VERSION ""

NS_ :

BS_:

BU_: MCTM_LS TIM_LS EOCM2cp_K2_LS EOCM2cp_K1_LS ADIMa_LS BCM_LS SAM_SR_LS SAM_SL_LS SAM_PR_LS SAM_PL_LS CGM3a_LS Dummy_LS VICM_LS ECC_LS PEPS_LS AOS_LS SDM_PR_LS AOS2_LS DLM_LS SCCM_2_LS SCCM_1_LS UPA_LS ADIMb_LS

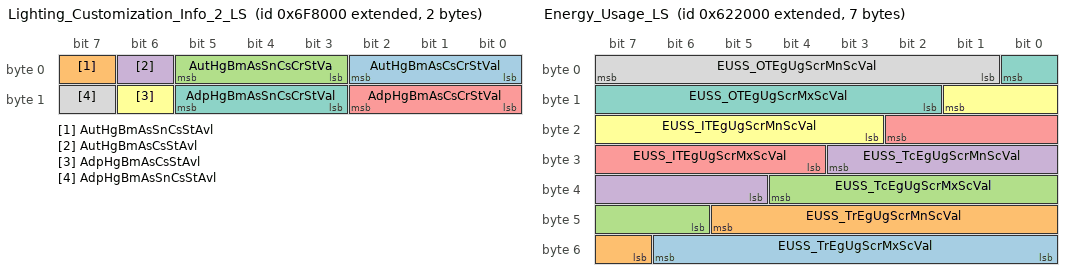
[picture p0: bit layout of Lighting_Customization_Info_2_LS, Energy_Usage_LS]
BO_ 2154790912 Lighting_Customization_Info_2_LS: 2 EOCM2cp_K2_LS
 SG_ AutHgBmAsCsCrStVal : 2|3@0+ (1,0) [0|7] ""  CGM3a_LS
 SG_ AutHgBmAsSnCsStAvl : 7|1@0+ (1,0) [0|1] ""  CGM3a_LS
 SG_ AutHgBmAsSnCsCrStVa : 5|3@0+ (1,0) [0|7] ""  CGM3a_LS
 SG_ AutHgBmAsCsStAvl : 6|1@0+ (1,0) [0|1] ""  CGM3a_LS
 SG_ AdpHgBmAsCsCrStVal : 10|3@0+ (1,0) [0|7] ""  CGM3a_LS
 SG_ AdpHgBmAsCsStAvl : 14|1@0+ (1,0) [0|1] ""  CGM3a_LS
 SG_ AdpHgBmAsSnCsCrStVal : 13|3@0+ (1,0) [0|7] ""  CGM3a_LS
 SG_ AdpHgBmAsSnCsStAvl : 15|1@0+ (1,0) [0|1] ""  CGM3a_LS

BO_ 2159149056 ODI_TEL_2_CenterStack_LS: 8 CGM3a_LS
 SG_ ODI_TEL2CntrStck : 7|64@0+ (1,0) [0|1.84467440737096E+019] ""  MCTM_LS

BO_ 2150227968 Phone_Speech_Rec_Status_LS: 1 CGM3a_LS
 SG_ PhnSpRcgnApSt : 1|2@0+ (1,0) [0|3] ""  MCTM_LS

BO_ 2153914368 Energy_Usage_LS: 7 VICM_LS
 SG_ EUSS_TrEgUgScrMxScVal : 54|7@0- (0.1,0) [-5|5] ""  CGM3a_LS
 SG_ EUSS_TrEgUgScrMnScVal : 45|7@0- (0.1,0) [-5|5] ""  CGM3a_LS
 SG_ EUSS_TcEgUgScrMxScVal : 36|7@0- (0.1,0) [-5|5] ""  CGM3a_LS
 SG_ EUSS_TcEgUgScrMnScVal : 27|7@0- (0.1,0) [-5|5] ""  CGM3a_LS
 SG_ EUSS_ITEgUgScrMxScVal : 18|7@0- (0.1,0) [-5|5] ""  CGM3a_LS
 SG_ EUSS_ITEgUgScrMnScVal : 9|7@0- (0.1,0) [-5|5] ""  CGM3a_LS
 SG_ EUSS_OTEgUgScrMxScVal : 0|7@0- (0.1,0) [-5|5] ""  CGM3a_LS
 SG_ EUSS_OTEgUgScrMnScVal : 7|7@0- (0.1,0) [-5|5] ""  CGM3a_LS

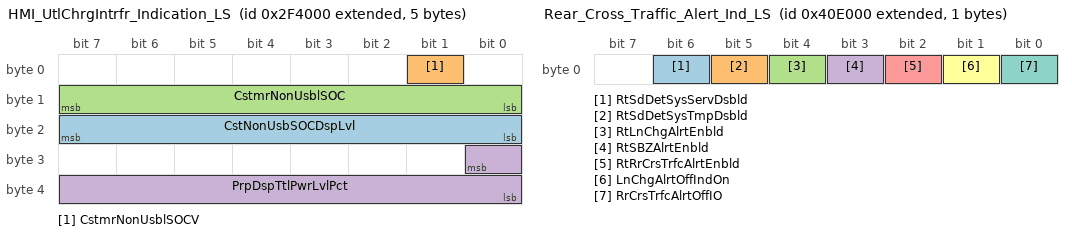
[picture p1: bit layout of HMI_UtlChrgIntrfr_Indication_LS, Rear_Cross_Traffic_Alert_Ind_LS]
BO_ 2150580224 HMI_UtlChrgIntrfr_Indication_LS: 5 VICM_LS
 SG_ CstNonUsbSOCDspLvl : 23|8@0+ (0.392157,0) [0|100.000035] "%"  CGM3a_LS
 SG_ CstmrNonUsblSOCV : 1|1@0+ (1,0) [0|1] ""  CGM3a_LS
 SG_ CstmrNonUsblSOC : 15|8@0+ (0.392157,0) [0|100.000035] "%"  CGM3a_LS
 SG_ PrpDspTtlPwrLvlPct : 24|9@0- (0.392157,0) [-100.392192|100.000035] "%"  CGM3a_LS

BO_ 2020 USDT_Req_to_VICM_LS: 8 CGM3a_LS
 SG_ DgnInf : 7|64@0+ (1,0) [0|1.84467440737096E+019] ""  CGM3a_LS,VICM_LS

BO_ 2151735296 Rear_Cross_Traffic_Alert_Ind_LS: 1 EOCM2cp_K2_LS
 SG_ RtSdDetSysServDsbld : 6|1@0+ (1,0) [0|1] ""  CGM3a_LS
 SG_ RtSdDetSysTmpDsbld : 5|1@0+ (1,0) [0|1] ""  CGM3a_LS
 SG_ RtLnChgAlrtEnbld : 4|1@0+ (1,0) [0|1] ""  CGM3a_LS
 SG_ RtSBZAlrtEnbld : 3|1@0+ (1,0) [0|1] ""  CGM3a_LS
 SG_ RtRrCrsTrfcAlrtEnbld : 2|1@0+ (1,0) [0|1] ""  CGM3a_LS
 SG_ LnChgAlrtOffIndOn : 1|1@0+ (1,0) [0|1] ""  CGM3a_LS
 SG_ RrCrsTrfcAlrtOffIO : 0|1@0+ (1,0) [0|1] ""  CGM3a_LS

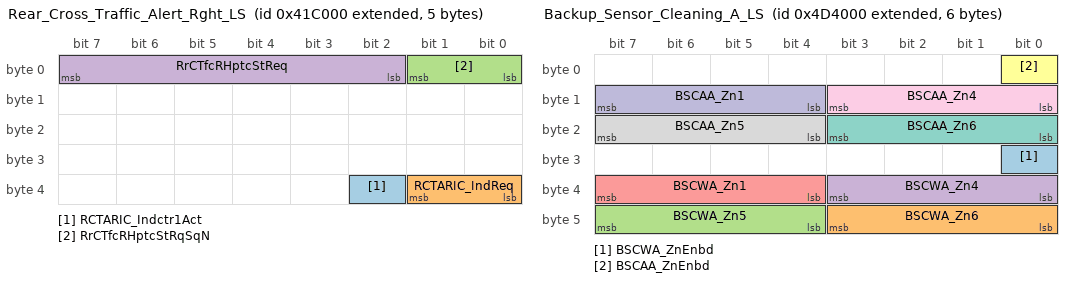
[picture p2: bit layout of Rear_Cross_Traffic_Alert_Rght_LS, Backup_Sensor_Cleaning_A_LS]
BO_ 2151792640 Rear_Cross_Traffic_Alert_Rght_LS: 5 EOCM2cp_K2_LS
 SG_ RCTARIC_Indctr1Act : 34|1@0+ (1,0) [0|1] ""  CGM3a_LS
 SG_ RCTARIC_IndReq : 33|2@0+ (1,0) [0|3] ""  CGM3a_LS
 SG_ RrCTfcRHptcStRqSqN : 1|2@0+ (1,0) [0|3] ""  CGM3a_LS
 SG_ RrCTfcRHptcStReq : 7|6@0+ (1,0) [0|63] ""  CGM3a_LS

BO_ 2152546304 Backup_Sensor_Cleaning_A_LS: 6 ADIMb_LS
 SG_ BSCWA_ZnEnbd : 24|1@0+ (1,0) [0|1] ""  CGM3a_LS,SCCM_1_LS
 SG_ BSCWA_Zn6 : 43|4@0+ (0.25,0) [0|3.75] "s"  CGM3a_LS,SCCM_1_LS
 SG_ BSCWA_Zn5 : 47|4@0+ (0.25,0) [0|3.75] "s"  CGM3a_LS,SCCM_1_LS
 SG_ BSCWA_Zn4 : 35|4@0+ (0.25,0) [0|3.75] "s"  CGM3a_LS,SCCM_1_LS
 SG_ BSCWA_Zn1 : 39|4@0+ (0.25,0) [0|3.75] "s"  CGM3a_LS,SCCM_1_LS
 SG_ BSCAA_ZnEnbd : 0|1@0+ (1,0) [0|1] ""  CGM3a_LS,SCCM_1_LS
 SG_ BSCAA_Zn6 : 19|4@0+ (0.25,0) [0|3.75] "s"  CGM3a_LS,SCCM_1_LS
 SG_ BSCAA_Zn5 : 23|4@0+ (0.25,0) [0|3.75] "s"  CGM3a_LS,SCCM_1_LS
 SG_ BSCAA_Zn4 : 11|4@0+ (0.25,0) [0|3.75] "s"  CGM3a_LS,SCCM_1_LS
 SG_ BSCAA_Zn1 : 15|4@0+ (0.25,0) [0|3.75] "s"  CGM3a_LS,SCCM_1_LS

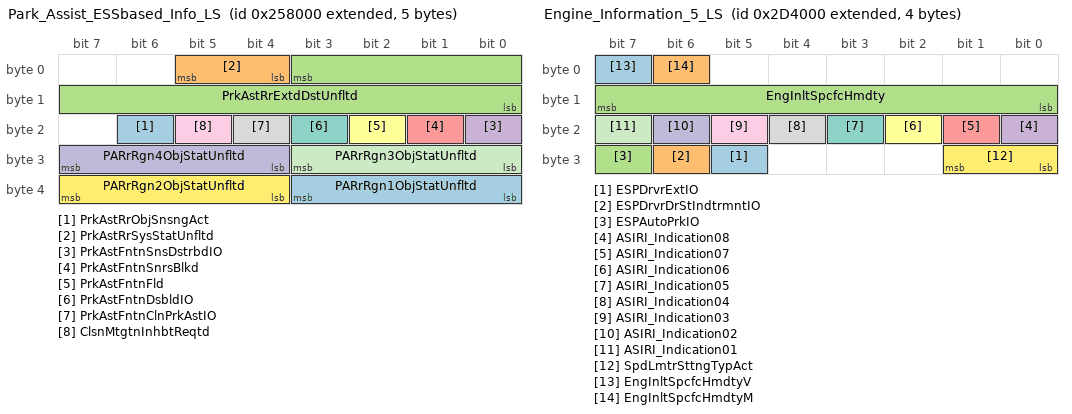
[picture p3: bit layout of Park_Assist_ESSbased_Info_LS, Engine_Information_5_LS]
BO_ 2149941248 Park_Assist_ESSbased_Info_LS: 5 UPA_LS
 SG_ PrkAstRrObjSnsngAct : 22|1@0+ (1,0) [0|1] ""  CGM3a_LS,EOCM2cp_K2_LS
 SG_ PrkAstRrSysStatUnfltd : 5|2@0+ (1,0) [0|3] ""  CGM3a_LS,EOCM2cp_K2_LS
 SG_ PrkAstRrExtdDstUnfltd : 3|12@0+ (0.01,0) [0|40.95] "m"  CGM3a_LS,EOCM2cp_K2_LS
 SG_ PrkAstFntnSnsDstrbdIO : 16|1@0+ (1,0) [0|1] ""  CGM3a_LS,EOCM2cp_K2_LS
 SG_ PrkAstFntnSnrsBlkd : 17|1@0+ (1,0) [0|1] ""  CGM3a_LS,EOCM2cp_K2_LS
 SG_ PrkAstFntnFld : 18|1@0+ (1,0) [0|1] ""  CGM3a_LS,EOCM2cp_K2_LS
 SG_ PrkAstFntnDsbldIO : 19|1@0+ (1,0) [0|1] ""  CGM3a_LS,EOCM2cp_K2_LS
 SG_ PrkAstFntnClnPrkAstIO : 20|1@0+ (1,0) [0|1] ""  CGM3a_LS,EOCM2cp_K2_LS
 SG_ ClsnMtgtnInhbtReqtd : 21|1@0+ (1,0) [0|1] ""  CGM3a_LS,EOCM2cp_K2_LS
 SG_ PARrRgn4ObjStatUnfltd : 31|4@0+ (1,0) [0|15] ""  CGM3a_LS,EOCM2cp_K2_LS
 SG_ PARrRgn3ObjStatUnfltd : 27|4@0+ (1,0) [0|15] ""  CGM3a_LS,EOCM2cp_K2_LS
 SG_ PARrRgn2ObjStatUnfltd : 39|4@0+ (1,0) [0|15] ""  CGM3a_LS,EOCM2cp_K2_LS
 SG_ PARrRgn1ObjStatUnfltd : 35|4@0+ (1,0) [0|15] ""  CGM3a_LS,EOCM2cp_K2_LS

BO_ 2156314624 High_Volt_Time_Based_Chrg_LS: 8 VICM_LS
 SG_ HVChrgSysSplyFltIO : 23|1@0+ (1,0) [0|1] ""  CGM3a_LS
 SG_ OffBrdCSFltDtctd : 6|1@0+ (1,0) [0|1] ""  CGM3a_LS
 SG_ OBVhCsACChgRqBnVs : 7|1@0+ (1,0) [0|1] ""  CGM3a_LS,BCM_LS
 SG_ TODCNPDT_Min : 13|6@0+ (1,0) [0|63] "Minute"  CGM3a_LS,BCM_LS
 SG_ TODCNPDT_Hr : 2|5@0+ (1,0) [0|31] "Hour"  CGM3a_LS,BCM_LS
 SG_ TODCNPDT_DyOfWk : 5|3@0+ (1,0) [0|7] ""  CGM3a_LS,BCM_LS
 SG_ HVBatBlkSOC : 63|8@0+ (0.392157,0) [0|100.000035] "%"  CGM3a_LS
 SG_ TODCOpMd : 22|3@0+ (1,0) [0|7] ""  CGM3a_LS
 SG_ TODCDMPTO_TpOvR : 51|4@0+ (1,0) [0|15] ""  CGM3a_LS,BCM_LS
 SG_ TODCDMPTO_CmPgR : 52|1@0+ (1,0) [0|1] ""  CGM3a_LS,BCM_LS
 SG_ HVChrgSysStNot : 55|3@0+ (1,0) [0|7] ""  CGM3a_LS,BCM_LS
 SG_ HVChrgAbrtRsn : 19|3@0+ (1,0) [0|7] ""  CGM3a_LS
 SG_ HVCSCLPD_UsrIntTyp : 16|2@0+ (1,0) [0|3] ""  CGM3a_LS,BCM_LS
 SG_ HVCSCLPD_RdCrntLv3 : 44|5@0+ (1,0) [0|31] "A"  CGM3a_LS,BCM_LS
 SG_ HVCSCLPD_RdCrntLv2 : 33|5@0+ (1,0) [0|31] "A"  CGM3a_LS,BCM_LS
 SG_ HVCSCLPD_RdCrntLv1 : 38|5@0+ (1,0) [0|31] "A"  CGM3a_LS,BCM_LS
 SG_ HVCSCLPD_NrmChrgC : 27|5@0+ (1,0) [0|31] "A"  CGM3a_LS,BCM_LS
 SG_ HVCSCLPD_ChgLvlPfS : 30|3@0+ (1,0) [0|7] ""  CGM3a_LS,BCM_LS

BO_ 2150449152 Engine_Information_5_LS: 4 BCM_LS
 SG_ ESPDrvrExtIO : 29|1@0+ (1,0) [0|1] ""  CGM3a_LS
 SG_ ESPDrvrDrStIndtrmntIO : 30|1@0+ (1,0) [0|1] ""  CGM3a_LS
 SG_ ESPAutoPrkIO : 31|1@0+ (1,0) [0|1] ""  CGM3a_LS
 SG_ ASIRI_Indication08 : 16|1@0+ (1,0) [0|1] ""  CGM3a_LS
 SG_ ASIRI_Indication07 : 17|1@0+ (1,0) [0|1] ""  CGM3a_LS
 SG_ ASIRI_Indication06 : 18|1@0+ (1,0) [0|1] ""  CGM3a_LS
 SG_ ASIRI_Indication05 : 19|1@0+ (1,0) [0|1] ""  CGM3a_LS
 SG_ ASIRI_Indication04 : 20|1@0+ (1,0) [0|1] ""  CGM3a_LS
 SG_ ASIRI_Indication03 : 21|1@0+ (1,0) [0|1] ""  CGM3a_LS
 SG_ ASIRI_Indication02 : 22|1@0+ (1,0) [0|1] ""  CGM3a_LS
 SG_ ASIRI_Indication01 : 23|1@0+ (1,0) [0|1] ""  CGM3a_LS
 SG_ SpdLmtrSttngTypAct : 25|2@0+ (1,0) [0|3] ""  CGM3a_LS
 SG_ EngInltSpcfcHmdtyV : 7|1@0+ (1,0) [0|1] ""  CGM3a_LS,ECC_LS
 SG_ EngInltSpcfcHmdtyM : 6|1@0+ (1,0) [0|1] ""  CGM3a_LS,ECC_LS
 SG_ EngInltSpcfcHmdty : 15|8@0+ (0.0196078,0) [0|4.999989] "% water"  CGM3a_LS,ECC_LS

BO_ 2149793792 FCA_VisionBased_Info_LS: 6 BCM_LS
 SG_ FCACustStngAvlbl : 6|1@0+ (1,0) [0|1] ""  CGM3a_LS
 SG_ FwdClnAlrtCustCrntSetngVal : 3|3@0+ (1,0) [0|7] ""  CGM3a_LS

BO_ 2150080512 Aux_Coolant_Heater_Status_LS: 8 VICM_LS
 SG_ LBCVLS_VehGPSLctV : 27|1@0+ (1,0) [0|1] ""  CGM3a_LS
 SG_ LBCVLS_VehGPSLct : 26|3@0+ (1,0) [0|7] ""  CGM3a_LS
 SG_ LBCPSS_PosUpdtStat : 20|2@0+ (1,0) [0|3] ""  CGM3a_LS
 SG_ LBCPSS_PosUpdtLct : 18|3@0+ (1,0) [0|7] ""  CGM3a_LS
 SG_ LBCCsStAvl : 7|1@0+ (1,0) [0|1] ""  CGM3a_LS
 SG_ LBCCsCrStVal : 2|2@0+ (1,0) [0|3] ""  CGM3a_LS
 SG_ LBCCF_Lct4PosStrdIO : 28|1@0+ (1,0) [0|1] ""  CGM3a_LS
 SG_ LBCCF_Lct3PosStrdIO : 29|1@0+ (1,0) [0|1] ""  CGM3a_LS
 SG_ LBCCF_Lct2PosStrdIO : 30|1@0+ (1,0) [0|1] ""  CGM3a_LS
 SG_ LBCCF_Lct1PosStrdIO : 31|1@0+ (1,0) [0|1] ""  CGM3a_LS
 SG_ LBCCDRR_PosNumbr : 10|3@0+ (1,0) [0|7] ""  CGM3a_LS
 SG_ LBCCDRR_ClrStrdPosResp : 12|2@0+ (1,0) [0|3] ""  CGM3a_LS
 SG_ ChrgCyclOvrlEngyEcnEq : 51|12@0+ (0.1,0) [0|409.5] "km/l"  CGM3a_LS
 SG_ ChrgCyclElecEngyEcnEq : 35|12@0+ (0.1,0) [0|409.5] "km/l"  CGM3a_LS
 SG_ LBCChrgLvlPrfExpIO : 6|1@0+ (1,0) [0|1] ""  CGM3a_LS
 SG_ EngAstHtDfrdHtMdAct : 0|1@0+ (1,0) [0|1] ""  CGM3a_LS,ECC_LS
 SG_ AuxClntHtrVlvStat : 5|3@0+ (1,0) [0|7] ""  CGM3a_LS,ECC_LS

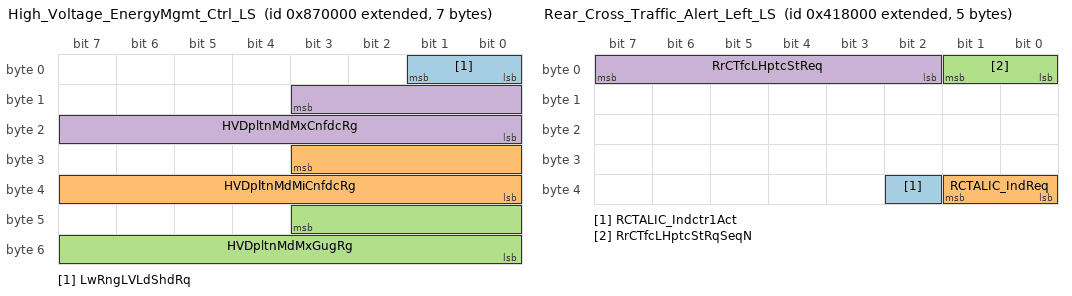
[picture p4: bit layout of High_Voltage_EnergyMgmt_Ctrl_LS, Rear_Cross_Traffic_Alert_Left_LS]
BO_ 2156331008 High_Voltage_EnergyMgmt_Ctrl_LS: 7 VICM_LS
 SG_ LwRngLVLdShdRq : 1|2@0+ (1,0) [0|3] ""  CGM3a_LS,BCM_LS
 SG_ HVDpltnMdMiCnfdcRg : 27|12@0+ (0.1,0) [0|409.5] "km"  CGM3a_LS
 SG_ HVDpltnMdMxGugRg : 43|12@0+ (0.1,0) [0|409.5] "km"  CGM3a_LS
 SG_ HVDpltnMdMxCnfdcRg : 11|12@0+ (0.1,0) [0|409.5] "km"  CGM3a_LS

BO_ 2151776256 Rear_Cross_Traffic_Alert_Left_LS: 5 EOCM2cp_K2_LS
 SG_ RCTALIC_Indctr1Act : 34|1@0+ (1,0) [0|1] ""  CGM3a_LS
 SG_ RCTALIC_IndReq : 33|2@0+ (1,0) [0|3] ""  CGM3a_LS
 SG_ RrCTfcLHptcStRqSeqN : 1|2@0+ (1,0) [0|3] ""  CGM3a_LS
 SG_ RrCTfcLHptcStReq : 7|6@0+ (1,0) [0|63] ""  CGM3a_LS

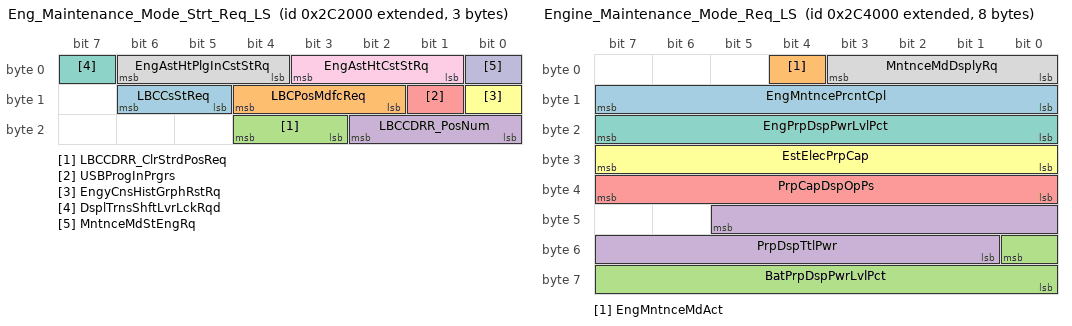
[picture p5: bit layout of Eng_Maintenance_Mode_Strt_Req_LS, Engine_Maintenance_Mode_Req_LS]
BO_ 2150375424 Eng_Maintenance_Mode_Strt_Req_LS: 3 CGM3a_LS
 SG_ LBCCsStReq : 14|2@0+ (1,0) [0|3] ""  VICM_LS
 SG_ LBCPosMdfcReq : 12|3@0+ (1,0) [0|7] ""  VICM_LS
 SG_ LBCCDRR_ClrStrdPosReq : 20|2@0+ (1,0) [0|3] ""  VICM_LS
 SG_ LBCCDRR_PosNum : 18|3@0+ (1,0) [0|7] ""  VICM_LS
 SG_ USBProgInPrgrs : 9|1@0+ (1,0) [0|1] ""  BCM_LS
 SG_ EngyCnsHistGrphRstRq : 8|1@0+ (1,0) [0|1] ""  VICM_LS
 SG_ DsplTrnsShftLvrLckRqd : 7|1@0+ (1,0) [0|1] ""  BCM_LS
 SG_ EngAstHtPlgInCstStRq : 6|3@0+ (1,0) [0|7] ""  VICM_LS
 SG_ EngAstHtCstStRq : 3|3@0+ (1,0) [0|7] ""  VICM_LS
 SG_ MntnceMdStEngRq : 0|1@0+ (1,0) [0|1] ""  VICM_LS

BO_ 2150383616 Engine_Maintenance_Mode_Req_LS: 8 VICM_LS
 SG_ EngMntncePrcntCpl : 15|8@0+ (0.392157,0) [0|100.000035] "%"  CGM3a_LS
 SG_ EngMntnceMdAct : 4|1@0+ (1,0) [0|1] ""  CGM3a_LS
 SG_ BatPrpDspPwrLvlPct : 48|9@0- (0.392157,0) [-100.392192|100.000035] "%"  CGM3a_LS
 SG_ PrpDspTtlPwr : 45|13@0+ (0.5,-326.6) [-326.6|3768.9] "kW"  CGM3a_LS
 SG_ PrpCapDspOpPs : 39|8@0+ (0.392157,0) [0|100.000035] "%"  CGM3a_LS
 SG_ EstElecPrpCap : 31|8@0+ (0.392157,0) [0|100.000035] "%"  CGM3a_LS
 SG_ EngPrpDspPwrLvlPct : 23|8@0+ (0.392157,0) [0|100.000035] "%"  CGM3a_LS
 SG_ MntnceMdDsplyRq : 3|4@0+ (1,0) [0|15] ""  CGM3a_LS

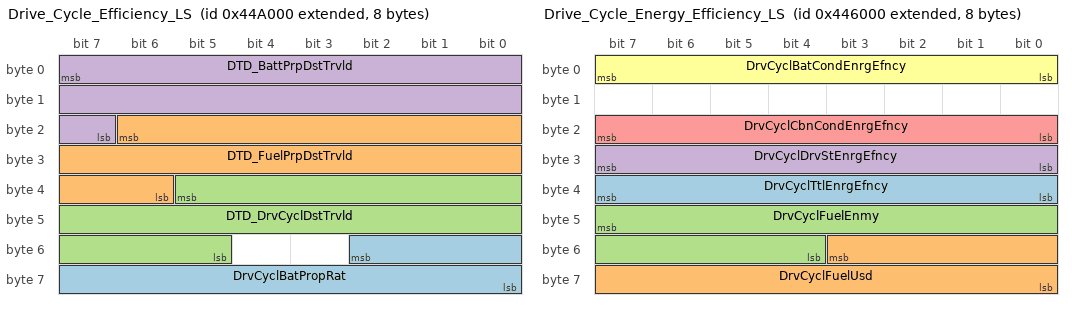
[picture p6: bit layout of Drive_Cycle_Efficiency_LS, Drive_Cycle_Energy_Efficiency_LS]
BO_ 2151981056 Drive_Cycle_Efficiency_LS: 8 VICM_LS
 SG_ DrvCyclBatPropRat : 50|11@0+ (0.048852,0) [0|100.000044] "%"  CGM3a_LS
 SG_ DTD_FuelPrpDstTrvld : 22|17@0+ (0.015625,0) [0|2047.984375] "km"  CGM3a_LS
 SG_ DTD_DrvCyclDstTrvld : 37|17@0+ (0.015625,0) [0|2047.984375] "km"  CGM3a_LS
 SG_ DTD_BattPrpDstTrvld : 7|17@0+ (0.015625,0) [0|2047.984375] "km"  CGM3a_LS

BO_ 2151964672 Drive_Cycle_Energy_Efficiency_LS: 8 VICM_LS
 SG_ DrvCyclTtlEnrgEfncy : 39|8@0+ (0.392157,0) [0|100.000035] "%"  CGM3a_LS
 SG_ DrvCyclFuelUsd : 51|12@0+ (0.125,0) [0|511.875] "liters"  CGM3a_LS
 SG_ DrvCyclFuelEnmy : 47|12@0+ (0.1,0) [0|409.5] "km/liters"  CGM3a_LS
 SG_ DrvCyclDrvStEnrgEfncy : 31|8@0+ (0.392157,0) [0|100.000035] "%"  CGM3a_LS
 SG_ DrvCyclCbnCondEnrgEfncy : 23|8@0+ (0.392157,0) [0|100.000035] "%"  CGM3a_LS
 SG_ DrvCyclBatCondEnrgEfncy : 7|8@0+ (0.392157,0) [0|100.000035] "%"  CGM3a_LS

BO_ 2156298240 High_Volt_Batt_Time_Pwr_Chrg_LS: 8 VICM_LS
 SG_ HTRActvIndOn : 59|1@0+ (1,0) [0|1] ""  CGM3a_LS
 SG_ HVBSTLPC_MntOfHr : 53|6@0+ (1,0) [0|63] "Minute"  CGM3a_LS,BCM_LS
 SG_ HVBSTLPC_HrOfDy : 42|5@0+ (1,0) [0|31] "Hour"  CGM3a_LS,BCM_LS
 SG_ HVBSTLPC_DyOfWk : 45|3@0+ (1,0) [0|7] ""  CGM3a_LS,BCM_LS
 SG_ HVBSTHPC_MntOfHr : 35|6@0+ (1,0) [0|63] "Minute"  CGM3a_LS,BCM_LS
 SG_ HVBSTHPC_HrOfDy : 24|5@0+ (1,0) [0|31] "Hour"  CGM3a_LS,BCM_LS
 SG_ HVBSTHPC_DyOfWk : 27|3@0+ (1,0) [0|7] ""  CGM3a_LS,BCM_LS
 SG_ HVBCTLPC_MntOfHr : 17|6@0+ (1,0) [0|63] "Minute"  CGM3a_LS,BCM_LS
 SG_ HVBCTLPC_HrOfDy : 22|5@0+ (1,0) [0|31] "Hour"  CGM3a_LS,BCM_LS
 SG_ HVBCTLPC_DyOfWk : 9|3@0+ (1,0) [0|7] ""  CGM3a_LS,BCM_LS
 SG_ HVBCTHPC_MntOfHr : 15|6@0+ (1,0) [0|63] "Minute"  CGM3a_LS,BCM_LS
 SG_ HVBCTHPC_HrOfDy : 4|5@0+ (1,0) [0|31] "Hour"  CGM3a_LS,BCM_LS
 SG_ HVBCTHPC_DyOfWk : 7|3@0+ (1,0) [0|7] ""  CGM3a_LS,BCM_LS
 SG_ InvldHMIEtrIO : 61|1@0+ (1,0) [0|1] ""  CGM3a_LS
 SG_ InsfcntTmTFlChrgIO : 60|1@0+ (1,0) [0|1] ""  CGM3a_LS
 SG_ HVBatChrgCrdAlrtReq : 63|2@0+ (1,0) [0|3] ""  CGM3a_LS,BCM_LS
 SG_ HVCSDTES_NPDTIO : 56|1@0+ (1,0) [0|1] ""  CGM3a_LS,BCM_LS
 SG_ HVCSDTES_LoPwrCIO : 58|1@0+ (1,0) [0|1] ""  CGM3a_LS,BCM_LS
 SG_ HVCSDTES_HiPwrCIO : 57|1@0+ (1,0) [0|1] ""  CGM3a_LS,BCM_LS

BO_ 2149924864 Drv_Pref_Mode_Switch_Status_LS: 8 BCM_LS
 SG_ a_12VBatSysUnstab : 55|1@0+ (1,0) [0|1] ""  CGM3a_LS
 SG_ FwdClnMtgnBrkReqAct : 7|1@0+ (1,0) [0|1] ""  CGM3a_LS
 SG_ TireRRLowTracIO : 54|1@0+ (1,0) [0|1] ""  CGM3a_LS
 SG_ TireRFLowTracIO : 53|1@0+ (1,0) [0|1] ""  CGM3a_LS
 SG_ TireLRLowTracIO : 52|1@0+ (1,0) [0|1] ""  CGM3a_LS
 SG_ TireLFLowTracIO : 51|1@0+ (1,0) [0|1] ""  CGM3a_LS
 SG_ HilRlbkCtrlActIO : 6|1@0+ (1,0) [0|1] ""  CGM3a_LS
 SG_ FstIdlMdAct : 39|1@0+ (1,0) [0|1] ""  CGM3a_LS
 SG_ DrvSelMd8Stat : 37|1@0+ (1,0) [0|1] ""  CGM3a_LS,ECC_LS
 SG_ DrvSelMd8ReqDnd : 38|1@0+ (1,0) [0|1] ""  CGM3a_LS
 SG_ DrvSelMd7Stat : 35|1@0+ (1,0) [0|1] ""  CGM3a_LS,ECC_LS
 SG_ DrvSelMd7ReqDnd : 36|1@0+ (1,0) [0|1] ""  CGM3a_LS
 SG_ DrvSelMd6Stat : 13|1@0+ (1,0) [0|1] ""  CGM3a_LS,ECC_LS
 SG_ DrvSelMd6ReqDnd : 14|1@0+ (1,0) [0|1] ""  CGM3a_LS
 SG_ DrvSelMd5Stat : 11|1@0+ (1,0) [0|1] ""  CGM3a_LS,ECC_LS
 SG_ DrvSelMd5ReqDnd : 12|1@0+ (1,0) [0|1] ""  CGM3a_LS
 SG_ DrvSelMd4Stat : 9|1@0+ (1,0) [0|1] ""  CGM3a_LS,ECC_LS
 SG_ DrvSelMd4ReqDnd : 10|1@0+ (1,0) [0|1] ""  CGM3a_LS
 SG_ DSMSS_DrvSelMd0Pn : 24|1@0+ (1,0) [0|1] ""  CGM3a_LS
 SG_ DSMSS_DrvSelMd8Pn : 25|1@0+ (1,0) [0|1] ""  CGM3a_LS
 SG_ DSMSS_DrvSelMd7Pn : 26|1@0+ (1,0) [0|1] ""  CGM3a_LS
 SG_ DSMSS_DrvSelMd6Pn : 27|1@0+ (1,0) [0|1] ""  CGM3a_LS
 SG_ DSMSS_DrvSelMd5Pn : 28|1@0+ (1,0) [0|1] ""  CGM3a_LS
 SG_ DSMSS_DrvSelMd4Pn : 29|1@0+ (1,0) [0|1] ""  CGM3a_LS
 SG_ DSMSS_DrvSelMd3Pn : 30|1@0+ (1,0) [0|1] ""  CGM3a_LS
 SG_ DSMSS_DrvSelMd2Pn : 31|1@0+ (1,0) [0|1] ""  CGM3a_LS
 SG_ DSMSS_DrvSelMd1Pn : 16|1@0+ (1,0) [0|1] ""  CGM3a_LS
 SG_ DSMSS_DrvSelMd8Un : 17|1@0+ (1,0) [0|1] ""  CGM3a_LS
 SG_ DSMSS_DrvSelMd7Un : 18|1@0+ (1,0) [0|1] ""  CGM3a_LS
 SG_ DSMSS_DrvSelMd6Un : 19|1@0+ (1,0) [0|1] ""  CGM3a_LS
 SG_ DSMSS_DrvSelMd5Un : 20|1@0+ (1,0) [0|1] ""  CGM3a_LS
 SG_ DSMSS_DrvSelMd4Un : 21|1@0+ (1,0) [0|1] ""  CGM3a_LS
 SG_ DSMSS_DrvSelMd3Un : 22|1@0+ (1,0) [0|1] ""  CGM3a_LS
 SG_ DSMSS_DrvSelMd2Un : 23|1@0+ (1,0) [0|1] ""  CGM3a_LS
 SG_ DSMSS_DrvSelMd1Un : 8|1@0+ (1,0) [0|1] ""  CGM3a_LS
 SG_ DrvSelMd3Stat : 4|1@0+ (1,0) [0|1] ""  CGM3a_LS,VICM_LS,ECC_LS
 SG_ DrvSelMd3ReqDnd : 5|1@0+ (1,0) [0|1] ""  CGM3a_LS
 SG_ DrvSelMd2Stat : 2|1@0+ (1,0) [0|1] ""  CGM3a_LS,VICM_LS,ECC_LS
 SG_ DrvSelMd2ReqDnd : 3|1@0+ (1,0) [0|1] ""  CGM3a_LS
 SG_ DrvSelMd1Stat : 0|1@0+ (1,0) [0|1] ""  CGM3a_LS,VICM_LS,ECC_LS
 SG_ DrvSelMd1ReqDnd : 1|1@0+ (1,0) [0|1] ""  CGM3a_LS
 SG_ CPSCA_Resrv3Avail : 56|1@0+ (1,0) [0|1] ""  CGM3a_LS
 SG_ CPSCA_Resrv2Avail : 57|1@0+ (1,0) [0|1] ""  CGM3a_LS
 SG_ CPSCA_Resrv1Avail : 58|1@0+ (1,0) [0|1] ""  CGM3a_LS
 SG_ CPSCA_AlrtBrkStrAvail : 59|1@0+ (1,0) [0|1] ""  CGM3a_LS
 SG_ CPSCA_AlrtBrkAvail : 60|1@0+ (1,0) [0|1] ""  CGM3a_LS
 SG_ CPSCA_AlrtAvail : 61|1@0+ (1,0) [0|1] ""  CGM3a_LS
 SG_ CPSCA_OffAvail : 62|1@0+ (1,0) [0|1] ""  CGM3a_LS

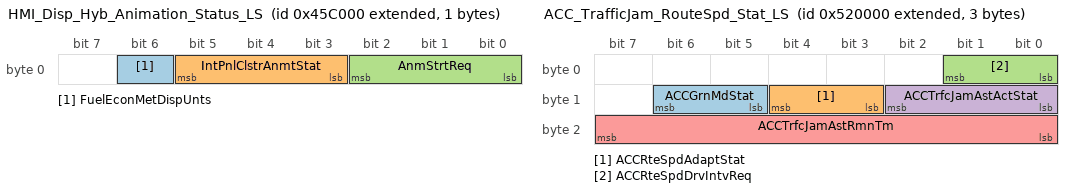
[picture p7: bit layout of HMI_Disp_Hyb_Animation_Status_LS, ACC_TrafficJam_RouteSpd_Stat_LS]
BO_ 2152054784 HMI_Disp_Hyb_Animation_Status_LS: 1 CGM3a_LS
 SG_ FuelEconMetDispUnts : 6|1@0+ (1,0) [0|1] ""  VICM_LS
 SG_ IntPnlClstrAnmtStat : 5|3@0+ (1,0) [0|7] "" Vector__XXX
 SG_ AnmStrtReq : 2|3@0+ (1,0) [0|7] "" Vector__XXX

BO_ 2150301696 HMI_Animation_Initiator_LS: 1 BCM_LS
 SG_ WlcAnmReq : 0|1@0+ (1,0) [0|1] ""  CGM3a_LS

BO_ 2152857600 ACC_TrafficJam_RouteSpd_Stat_LS: 3 EOCM2cp_K2_LS
 SG_ ACCGrnMdStat : 14|2@0+ (1,0) [0|3] ""  CGM3a_LS
 SG_ ACCRteSpdAdaptStat : 12|2@0+ (1,0) [0|3] ""  CGM3a_LS
 SG_ ACCRteSpdDrvIntvReq : 1|2@0+ (1,0) [0|3] ""  CGM3a_LS
 SG_ ACCTrfcJamAstActStat : 10|3@0+ (1,0) [0|7] ""  CGM3a_LS
 SG_ ACCTrfcJamAstRmnTm : 23|8@0+ (1,0) [0|255] "sec"  CGM3a_LS

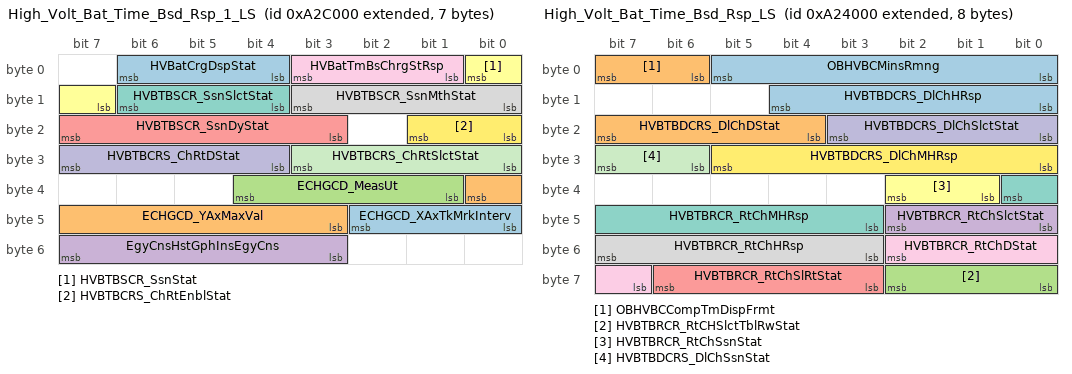
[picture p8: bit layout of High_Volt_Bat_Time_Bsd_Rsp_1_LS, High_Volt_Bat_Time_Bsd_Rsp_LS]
BO_ 2158149632 High_Volt_Bat_Time_Bsd_Rsp_1_LS: 7 VICM_LS
 SG_ ECHGCD_XAxTkMrkInterv : 42|3@0+ (1,0) [0|7] ""  CGM3a_LS
 SG_ ECHGCD_YAxMaxVal : 32|6@0+ (4,0) [0|252] ""  CGM3a_LS
 SG_ ECHGCD_MeasUt : 36|4@0+ (1,0) [0|15] ""  CGM3a_LS
 SG_ EgyCnsHstGphInsEgyCns : 55|5@0+ (1,0) [0|31] ""  CGM3a_LS
 SG_ HVBTBSCR_SsnDyStat : 23|5@0+ (1,0) [0|31] "day"  CGM3a_LS
 SG_ HVBTBSCR_SsnStat : 0|2@0+ (1,0) [0|3] ""  CGM3a_LS
 SG_ HVBTBSCR_SsnSlctStat : 14|3@0+ (1,0) [0|7] ""  CGM3a_LS
 SG_ HVBTBSCR_SsnMthStat : 11|4@0+ (1,0) [0|15] ""  CGM3a_LS
 SG_ HVBatTmBsChrgStRsp : 3|3@0+ (1,0) [0|7] ""  CGM3a_LS,BCM_LS
 SG_ HVBTBCRS_ChRtDStat : 31|4@0+ (1,0) [0|15] ""  CGM3a_LS
 SG_ HVBTBCRS_ChRtSlctStat : 27|4@0+ (1,0) [0|15] ""  CGM3a_LS
 SG_ HVBTBCRS_ChRtEnblStat : 17|2@0+ (1,0) [0|3] ""  CGM3a_LS
 SG_ HVBatCrgDspStat : 6|3@0+ (1,0) [0|7] ""  CGM3a_LS,BCM_LS

BO_ 2158116864 High_Volt_Bat_Time_Bsd_Rsp_LS: 8 VICM_LS
 SG_ OBHVBCMinsRmng : 5|6@0+ (1,0) [0|63] ""  CGM3a_LS
 SG_ OBHVBCCompTmDispFrmt : 7|2@0+ (1,0) [0|3] ""  CGM3a_LS
 SG_ HVBTBRCR_RtCHSlctTblRwStat : 58|3@0+ (1,0) [0|7] "rows"  CGM3a_LS
 SG_ HVBTBRCR_RtChSlctStat : 42|3@0+ (1,0) [0|7] ""  CGM3a_LS
 SG_ HVBTBRCR_RtChSlRtStat : 62|4@0+ (1,0) [0|15] ""  CGM3a_LS
 SG_ HVBTBRCR_RtChSsnStat : 34|2@0+ (1,0) [0|3] ""  CGM3a_LS
 SG_ HVBTBRCR_RtChMHRsp : 32|6@0+ (1,0) [0|63] "min"  CGM3a_LS
 SG_ HVBTBRCR_RtChHRsp : 55|5@0+ (1,0) [0|31] "hr"  CGM3a_LS
 SG_ HVBTBRCR_RtChDStat : 50|4@0+ (1,0) [0|15] ""  CGM3a_LS
 SG_ HVBTBDCRS_DlChSlctStat : 19|4@0+ (1,0) [0|15] ""  CGM3a_LS,BCM_LS
 SG_ HVBTBDCRS_DlChSsnStat : 31|2@0+ (1,0) [0|3] ""  CGM3a_LS,BCM_LS
 SG_ HVBTBDCRS_DlChMHRsp : 29|6@0+ (1,0) [0|63] "min"  CGM3a_LS,BCM_LS
 SG_ HVBTBDCRS_DlChHRsp : 12|5@0+ (1,0) [0|31] "hr"  CGM3a_LS,BCM_LS
 SG_ HVBTBDCRS_DlChDStat : 23|4@0+ (1,0) [0|15] ""  CGM3a_LS,BCM_LS

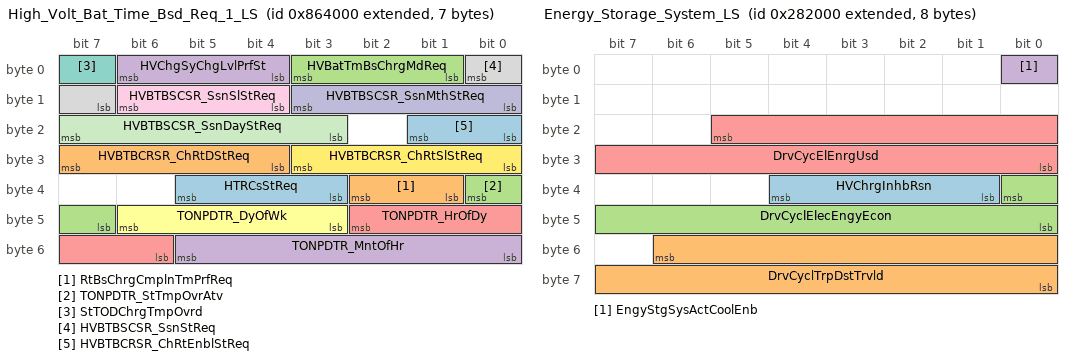
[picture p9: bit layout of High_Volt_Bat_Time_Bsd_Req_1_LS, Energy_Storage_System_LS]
BO_ 2156281856 High_Volt_Bat_Time_Bsd_Req_1_LS: 7 CGM3a_LS
 SG_ HTRCsStReq : 37|3@0+ (1,0) [0|7] ""  VICM_LS
 SG_ RtBsChrgCmplnTmPrfReq : 34|2@0+ (1,0) [0|3] ""  VICM_LS
 SG_ TONPDTR_StTmpOvrAtv : 32|2@0+ (1,0) [0|3] ""  VICM_LS
 SG_ TONPDTR_MntOfHr : 53|6@0+ (1,0) [0|63] "Minute"  VICM_LS
 SG_ TONPDTR_HrOfDy : 42|5@0+ (1,0) [0|31] "Hour"  VICM_LS
 SG_ TONPDTR_DyOfWk : 46|4@0+ (1,0) [0|15] ""  VICM_LS
 SG_ StTODChrgTmpOvrd : 7|1@0+ (1,0) [0|1] ""  VICM_LS
 SG_ HVBTBSCSR_SsnStReq : 0|2@0+ (1,0) [0|3] ""  VICM_LS
 SG_ HVBTBSCSR_SsnSlStReq : 14|3@0+ (1,0) [0|7] ""  VICM_LS
 SG_ HVBTBSCSR_SsnMthStReq : 11|4@0+ (1,0) [0|15] ""  VICM_LS
 SG_ HVBTBSCSR_SsnDayStReq : 23|5@0+ (1,0) [0|31] "day"  VICM_LS
 SG_ HVBTBCRSR_ChRtSlStReq : 27|4@0+ (1,0) [0|15] ""  VICM_LS
 SG_ HVBTBCRSR_ChRtEnblStReq : 17|2@0+ (1,0) [0|3] ""  VICM_LS
 SG_ HVBTBCRSR_ChRtDStReq : 31|4@0+ (1,0) [0|15] ""  VICM_LS
 SG_ HVBatTmBsChrgMdReq : 3|3@0+ (1,0) [0|7] ""  VICM_LS
 SG_ HVChgSyChgLvlPrfSt : 6|3@0+ (1,0) [0|7] ""  VICM_LS

BO_ 2156265472 High_Volt_Bat_Time_Bsd_Req_LS: 8 CGM3a_LS
 SG_ EngyUsgScrnMeasUtStat : 39|4@0+ (1,0) [0|15] ""  VICM_LS
 SG_ OffBrdHVCVehCsChRq : 35|1@0+ (1,0) [0|1] ""  VICM_LS
 SG_ PrtyChrgRq : 7|2@0+ (1,0) [0|3] ""  VICM_LS
 SG_ HVBTBRCSR_RtChSlStReq : 42|3@0+ (1,0) [0|7] ""  VICM_LS
 SG_ HVBTBRCSR_RtChSlRtStReq : 46|4@0+ (1,0) [0|15] ""  VICM_LS
 SG_ HVBTBRCSR_RtChSsnStReq : 50|2@0+ (1,0) [0|3] ""  VICM_LS
 SG_ HVBTBRCSR_RtChMHStReq : 48|6@0+ (1,0) [0|63] "min"  VICM_LS
 SG_ HVBTBRCSR_RtChHStReq : 55|5@0+ (1,0) [0|31] "hr"  VICM_LS
 SG_ HVBTBRCSR_RtChDStReq : 34|4@0+ (1,0) [0|15] ""  VICM_LS
 SG_ HVBTBRCSR_RtChSlTbRwReq : 58|3@0+ (1,0) [0|7] "rows"  VICM_LS
 SG_ HVBTBDCSRQ_DlChSlStReq : 19|4@0+ (1,0) [0|15] ""  VICM_LS
 SG_ HVBTBDCSRQ_DlChSsnStReq : 31|2@0+ (1,0) [0|3] ""  VICM_LS
 SG_ HVBTBDCSRQ_DlChMHStReq : 29|6@0+ (1,0) [0|63] "min"  VICM_LS
 SG_ HVBTBDCSRQ_DlChHStReq : 12|5@0+ (1,0) [0|31] "hr"  VICM_LS
 SG_ HVBTBDCSRQ_DlChDStReq : 23|4@0+ (1,0) [0|15] ""  VICM_LS
 SG_ ChgPwLsAlCzStRq : 5|3@0+ (1,0) [0|7] ""  VICM_LS
 SG_ ChgCdTfAlCzStRq : 2|3@0+ (1,0) [0|7] ""  VICM_LS
 SG_ ChgSysAudInCsStReq : 15|3@0+ (1,0) [0|7] ""  VICM_LS

BO_ 2150113280 Energy_Storage_System_LS: 8 VICM_LS
 SG_ HVChrgInhbRsn : 36|4@0+ (1,0) [0|15] ""  CGM3a_LS
 SG_ DrvCyclTrpDstTrvld : 54|15@0+ (0.1,0) [0|3276.7] "km"  CGM3a_LS
 SG_ DrvCyclElecEngyEcon : 32|9@0+ (0.1,0) [0|51.1] ""  CGM3a_LS
 SG_ EngyStgSysActCoolEnb : 0|1@0+ (1,0) [0|1] ""  CGM3a_LS,ECC_LS,BCM_LS
 SG_ DrvCycElEnrgUsd : 21|14@0+ (0.36,0) [0|5897.88] "MJ"  CGM3a_LS

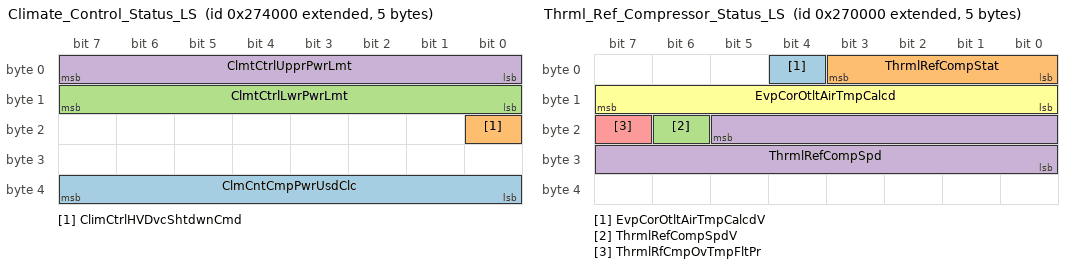
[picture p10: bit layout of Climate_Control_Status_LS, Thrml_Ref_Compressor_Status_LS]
BO_ 2150055936 Climate_Control_Status_LS: 5 VICM_LS
 SG_ ClmCntCmpPwrUsdClc : 39|8@0+ (0.04,0) [0|10.2] "kW"  CGM3a_LS,ECC_LS
 SG_ ClimCtrlHVDvcShtdwnCmd : 16|1@0+ (1,0) [0|1] ""  ECC_LS,CGM3a_LS
 SG_ ClmtCtrlLwrPwrLmt : 15|8@0+ (0.1,0) [0|25.5] "kW"  CGM3a_LS,ECC_LS
 SG_ ClmtCtrlUpprPwrLmt : 7|8@0+ (0.1,0) [0|25.5] "kW"  CGM3a_LS,ECC_LS

BO_ 2150039552 Thrml_Ref_Compressor_Status_LS: 5 VICM_LS
 SG_ EvpCorOtltAirTmpCalcdV : 4|1@0+ (1,0) [0|1] ""  CGM3a_LS,ECC_LS
 SG_ ThrmlRefCompStat : 3|4@0+ (1,0) [0|15] ""  CGM3a_LS,ECC_LS
 SG_ ThrmlRefCompSpdV : 22|1@0+ (1,0) [0|1] ""  CGM3a_LS,ECC_LS
 SG_ ThrmlRefCompSpd : 21|14@0+ (1,0) [0|16383] "rpm"  CGM3a_LS,ECC_LS
 SG_ ThrmlRfCmpOvTmpFltPr : 23|1@0+ (1,0) [0|1] ""  CGM3a_LS,ECC_LS
 SG_ EvpCorOtltAirTmpCalcd : 15|8@0+ (0.5,-40) [-40|87.5] "deg C"  CGM3a_LS,ECC_LS

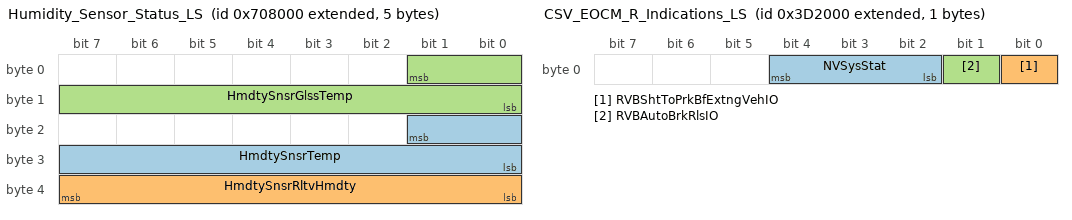
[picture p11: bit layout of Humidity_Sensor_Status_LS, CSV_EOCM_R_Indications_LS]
BO_ 2154856448 Humidity_Sensor_Status_LS: 5 BCM_LS
 SG_ HmdtySnsrTemp : 17|10@0+ (0.146628,-50) [-50|100.000444] "deg C"  CGM3a_LS,VICM_LS,ECC_LS
 SG_ HmdtySnsrRltvHmdty : 39|8@0+ (0.392157,0) [0|100.000035] "%"  CGM3a_LS,VICM_LS,ECC_LS
 SG_ HmdtySnsrGlssTemp : 1|10@0+ (0.146628,-50) [-50|100.000444] "deg C"  CGM3a_LS,ECC_LS

BO_ 2151489536 CSV_EOCM_R_Indications_LS: 1 EOCM2cp_K2_LS
 SG_ NVSysStat : 4|3@0+ (1,0) [0|7] ""  CGM3a_LS
 SG_ RVBShtToPrkBfExtngVehIO : 0|1@0+ (1,0) [0|1] ""  CGM3a_LS
 SG_ RVBAutoBrkRlsIO : 1|1@0+ (1,0) [0|1] ""  CGM3a_LS

BA_DEF_ SG_  "VNSigPrimaryTriggering" ENUM  "No","Yes";
BA_DEF_ SG_  "VNSigRemoteDiagnostics" ENUM  "No","Yes";
BA_DEF_ SG_  "VNSigInfotainment" ENUM  "No","Yes";
BA_DEF_ SG_  "VNSigParkedVehicle" ENUM  "No","Yes";
BA_DEF_ SG_  "VNSigIntermediate" ENUM  "No","Yes";
BA_DEF_ SG_  "VNSigUnused_4" ENUM  "No","Yes";
BA_DEF_ SG_  "SignalType" STRING ;
BA_DEF_ SG_  "PacketOrder" INT 0 65535;
BA_DEF_ SG_  "SignalLongName" STRING ;
BA_DEF_ SG_  "GenSigStartValue" INT 0 65535;
BA_DEF_ SG_  "VNSigDiagnostic" ENUM  "No","Yes";
BA_DEF_ SG_  "VNSigAllNodes" ENUM  "No","Yes";
BA_DEF_ SG_  "GenSigDeltaValue" INT 0 0;
BA_DEF_ SG_  "GenSigSendType" ENUM  "not used","not used","not used","not used","not used","not used","not used","NoSigSendType","not used","not used","OnAnyChange","OnChangeIfActive","OnDelta";
BA_DEF_ SG_  "GenSigSendOnInit" ENUM  "Not Initialized","Application","Handler";
BA_DEF_ BO_  "AppGenMsgCycleTime" INT 0 0;
BA_DEF_ BO_  "TpTxIndex" INT 0 99;
BA_DEF_ BO_  "GenMsgILSupport" ENUM  "No","Yes";
BA_DEF_ BO_  "TpApplType" STRING ;
BA_DEF_ BO_  "Prio" INT 0 7;
BA_DEF_ BO_  "MessageSubnet" ENUM  "LS","HS","CE","PE","HV","FO","LE","HE2","PHS","PCE","DLCLS","DLCHS","DLCCE","DLCFO";
BA_DEF_ BO_  "GenMsgMandatoryToSupervision" ENUM  "No","Yes";
BA_DEF_ BO_  "DiagState" ENUM  "No","Yes";
BA_DEF_ BO_  "GenMsgStartDelayTime" INT 0 100000;
BA_DEF_ BO_  "GenMsgDelayTime" INT 0 100000;
BA_DEF_ BO_  "GenMsgCycleTime" INT 0 100000;
BA_DEF_ BO_  "GenMsgCycleTimeFast" INT 0 100000;
BA_DEF_ BO_  "GenMsgSendType" ENUM  "cyclicX","spontanX","cyclicIfActiveX","spontanWithDelay","cyclicAndSpontanX","cyclicAndSpontanWithDelay","spontanWithRepitition","cyclicIfActiveAndSpontanWD";
BA_DEF_ BO_  "DiagResponse" ENUM  "No","Yes";
BA_DEF_ BO_  "DiagRequest" ENUM  "No","Yes";
BA_DEF_ BO_  "NmMessage" ENUM  "No","Yes";
BA_DEF_REL_ BU_SG_REL_  "GenSigSuprvRespComment" STRING ;
BA_DEF_REL_ BU_SG_REL_  "GenSigVBitResp" ENUM  "No","Yes";
BA_DEF_REL_ BU_SG_REL_  "GenSigVBitRespComment" STRING ;
BA_DEF_REL_ BU_SG_REL_  "GenSigVDAFailComment" STRING ;
BA_DEF_REL_ BU_SG_REL_  "GenSigVDAFailResp" ENUM  "No","Yes";
BA_DEF_REL_ BU_SG_REL_  "GenSigRxStartValue" STRING ;
BA_DEF_REL_ BU_SG_REL_  "GenSigSuprvRespSubValue" INT 0 65535;
BA_DEF_REL_ BU_SG_REL_  "GenSigSuprvResp" ENUM  "None","Notify App","Substitute Default";
BA_DEF_REL_ BU_SG_REL_  "GenSigTimeoutMsg" HEX 0 268435455;
BA_DEF_REL_ BU_SG_REL_  "GenSigTimeoutTime" INT 0 15000;
BA_DEF_DEF_  "VNSigPrimaryTriggering" "No";
BA_DEF_DEF_  "VNSigRemoteDiagnostics" "No";
BA_DEF_DEF_  "VNSigInfotainment" "No";
BA_DEF_DEF_  "VNSigParkedVehicle" "No";
BA_DEF_DEF_  "VNSigIntermediate" "No";
BA_DEF_DEF_  "VNSigUnused_4" "No";
BA_DEF_DEF_  "SignalType" "";
BA_DEF_DEF_  "PacketOrder" 0;
BA_DEF_DEF_  "SignalLongName" "";
BA_DEF_DEF_  "GenSigStartValue" 0;
BA_DEF_DEF_  "VNSigDiagnostic" "No";
BA_DEF_DEF_  "VNSigAllNodes" "No";
BA_DEF_DEF_  "GenSigDeltaValue" 0;
BA_DEF_DEF_  "GenSigSendType" "NoSigSendType";
BA_DEF_DEF_  "GenSigSendOnInit" "Not Initialized";
BA_DEF_DEF_  "AppGenMsgCycleTime" 0;
BA_DEF_DEF_  "TpTxIndex" 0;
BA_DEF_DEF_  "GenMsgILSupport" "Yes";
BA_DEF_DEF_  "TpApplType" "";
BA_DEF_DEF_  "Prio" 4;
BA_DEF_DEF_  "MessageSubnet" "LS";
BA_DEF_DEF_  "GenMsgMandatoryToSupervision" "No";
BA_DEF_DEF_  "DiagState" "No";
BA_DEF_DEF_  "GenMsgStartDelayTime" 0;
BA_DEF_DEF_  "GenMsgDelayTime" 0;
BA_DEF_DEF_  "GenMsgCycleTime" 0;
BA_DEF_DEF_  "GenMsgCycleTimeFast" 0;
BA_DEF_DEF_  "GenMsgSendType" "spontanX";
BA_DEF_DEF_  "DiagResponse" "No";
BA_DEF_DEF_  "DiagRequest" "No";
BA_DEF_DEF_  "NmMessage" "No";
BA_DEF_DEF_REL_ "GenSigSuprvRespComment" "";
BA_DEF_DEF_REL_ "GenSigVBitResp" "No";
BA_DEF_DEF_REL_ "GenSigVBitRespComment" "";
BA_DEF_DEF_REL_ "GenSigVDAFailComment" "";
BA_DEF_DEF_REL_ "GenSigVDAFailResp" "No";
BA_DEF_DEF_REL_ "GenSigRxStartValue" "";
BA_DEF_DEF_REL_ "GenSigSuprvRespSubValue" 0;
BA_DEF_DEF_REL_ "GenSigSuprvResp" "None";
BA_DEF_DEF_REL_ "GenSigTimeoutMsg" 0;
BA_DEF_DEF_REL_ "GenSigTimeoutTime" 0;
BA_ "GenMsgDelayTime" BO_ 2154790912 100;
BA_ "GenMsgDelayTime" BO_ 2159149056 10;
BA_ "GenMsgDelayTime" BO_ 2150227968 100;
BA_ "GenMsgDelayTime" BO_ 2153914368 100;
BA_ "GenMsgDelayTime" BO_ 2150580224 100;
BA_ "Prio" BO_ 2020 0;
BA_ "DiagRequest" BO_ 2020 1;
BA_ "GenMsgDelayTime" BO_ 2151735296 100;
BA_ "GenMsgDelayTime" BO_ 2151792640 100;
BA_ "GenMsgDelayTime" BO_ 2152546304 100;
BA_ "GenMsgDelayTime" BO_ 2149941248 30;
BA_ "GenMsgDelayTime" BO_ 2156314624 100;
BA_ "GenMsgDelayTime" BO_ 2150449152 100;
BA_ "GenMsgDelayTime" BO_ 2149793792 100;
BA_ "GenMsgDelayTime" BO_ 2150080512 100;
BA_ "GenMsgDelayTime" BO_ 2156331008 100;
BA_ "GenMsgDelayTime" BO_ 2151776256 100;
BA_ "GenMsgDelayTime" BO_ 2150375424 100;
BA_ "GenMsgDelayTime" BO_ 2150383616 100;
BA_ "GenMsgDelayTime" BO_ 2151981056 100;
BA_ "GenMsgDelayTime" BO_ 2151964672 100;
BA_ "GenMsgDelayTime" BO_ 2156298240 100;
BA_ "GenMsgDelayTime" BO_ 2149924864 100;
BA_ "GenMsgDelayTime" BO_ 2152054784 100;
BA_ "GenMsgDelayTime" BO_ 2150301696 100;
BA_ "GenMsgDelayTime" BO_ 2152857600 100;
BA_ "GenMsgDelayTime" BO_ 2158149632 100;
BA_ "GenMsgDelayTime" BO_ 2158116864 100;
BA_ "GenMsgDelayTime" BO_ 2156281856 100;
BA_ "GenMsgDelayTime" BO_ 2156265472 100;
BA_ "GenMsgDelayTime" BO_ 2150113280 100;
BA_ "GenMsgDelayTime" BO_ 2150055936 100;
BA_ "GenMsgDelayTime" BO_ 2150039552 100;
BA_ "GenMsgDelayTime" BO_ 2154856448 100;
BA_ "GenMsgDelayTime" BO_ 2151489536 100;
BA_ "GenSigSendType" SG_ 2154790912 AutHgBmAsCsCrStVal 10;
BA_ "GenSigSendOnInit" SG_ 2154790912 AutHgBmAsCsCrStVal 2;
BA_ "SignalType" SG_ 2154790912 AutHgBmAsCsCrStVal "ENM";
BA_ "SignalLongName" SG_ 2154790912 AutHgBmAsCsCrStVal "Auto High Beam Assist Customization Current Setting Value";
BA_ "VNSigAllNodes" SG_ 2154790912 AutHgBmAsCsCrStVal 1;
BA_ "GenSigSendType" SG_ 2154790912 AutHgBmAsSnCsStAvl 10;
BA_ "GenSigSendOnInit" SG_ 2154790912 AutHgBmAsSnCsStAvl 2;
BA_ "SignalType" SG_ 2154790912 AutHgBmAsSnCsStAvl "BLN";
BA_ "SignalLongName" SG_ 2154790912 AutHgBmAsSnCsStAvl "Auto High Beam Assist With Sensitivity Customization Setting Available";
BA_ "VNSigAllNodes" SG_ 2154790912 AutHgBmAsSnCsStAvl 1;
BA_ "GenSigSendType" SG_ 2154790912 AutHgBmAsSnCsCrStVa 10;
BA_ "GenSigSendOnInit" SG_ 2154790912 AutHgBmAsSnCsCrStVa 2;
BA_ "SignalType" SG_ 2154790912 AutHgBmAsSnCsCrStVa "ENM";
BA_ "SignalLongName" SG_ 2154790912 AutHgBmAsSnCsCrStVa "Auto High Beam Assist With Sensitivity Customization Current Setting Value";
BA_ "VNSigAllNodes" SG_ 2154790912 AutHgBmAsSnCsCrStVa 1;
BA_ "GenSigSendType" SG_ 2154790912 AutHgBmAsCsStAvl 10;
BA_ "GenSigSendOnInit" SG_ 2154790912 AutHgBmAsCsStAvl 2;
BA_ "SignalType" SG_ 2154790912 AutHgBmAsCsStAvl "BLN";
BA_ "SignalLongName" SG_ 2154790912 AutHgBmAsCsStAvl "Auto High Beam Assist Customization Setting Available";
BA_ "VNSigAllNodes" SG_ 2154790912 AutHgBmAsCsStAvl 1;
BA_ "GenSigSendType" SG_ 2154790912 AdpHgBmAsCsCrStVal 10;
BA_ "GenSigSendOnInit" SG_ 2154790912 AdpHgBmAsCsCrStVal 2;
BA_ "SignalType" SG_ 2154790912 AdpHgBmAsCsCrStVal "ENM";
BA_ "SignalLongName" SG_ 2154790912 AdpHgBmAsCsCrStVal "Adaptive High Beam Assist Customization Current Setting Value";
BA_ "VNSigAllNodes" SG_ 2154790912 AdpHgBmAsCsCrStVal 1;
BA_ "GenSigSendType" SG_ 2154790912 AdpHgBmAsCsStAvl 10;
BA_ "GenSigSendOnInit" SG_ 2154790912 AdpHgBmAsCsStAvl 2;
BA_ "SignalType" SG_ 2154790912 AdpHgBmAsCsStAvl "BLN";
BA_ "SignalLongName" SG_ 2154790912 AdpHgBmAsCsStAvl "Adaptive High Beam Assist Customization Setting Available";
BA_ "VNSigAllNodes" SG_ 2154790912 AdpHgBmAsCsStAvl 1;
BA_ "GenSigSendType" SG_ 2154790912 AdpHgBmAsSnCsCrStVal 10;
BA_ "GenSigSendOnInit" SG_ 2154790912 AdpHgBmAsSnCsCrStVal 2;
BA_ "SignalType" SG_ 2154790912 AdpHgBmAsSnCsCrStVal "ENM";
BA_ "SignalLongName" SG_ 2154790912 AdpHgBmAsSnCsCrStVal "Adaptive High Beam Assist With Sensitivity Customization Current Setting Value";
BA_ "VNSigAllNodes" SG_ 2154790912 AdpHgBmAsSnCsCrStVal 1;
BA_ "GenSigSendType" SG_ 2154790912 AdpHgBmAsSnCsStAvl 10;
BA_ "GenSigSendOnInit" SG_ 2154790912 AdpHgBmAsSnCsStAvl 2;
BA_ "SignalType" SG_ 2154790912 AdpHgBmAsSnCsStAvl "BLN";
BA_ "SignalLongName" SG_ 2154790912 AdpHgBmAsSnCsStAvl "Adaptive High Beam Assist With Sensitivity Customization Setting Available";
BA_ "VNSigAllNodes" SG_ 2154790912 AdpHgBmAsSnCsStAvl 1;
BA_ "VNSigInfotainment" SG_ 2159149056 ODI_TEL2CntrStck 1;
BA_ "SignalType" SG_ 2159149056 ODI_TEL2CntrStck "UNM";
BA_ "SignalLongName" SG_ 2159149056 ODI_TEL2CntrStck "Open Display Interface TEL 2 CenterStack";
BA_ "VNSigAllNodes" SG_ 2159149056 ODI_TEL2CntrStck 1;
BA_ "VNSigInfotainment" SG_ 2150227968 PhnSpRcgnApSt 1;
BA_ "SignalType" SG_ 2150227968 PhnSpRcgnApSt "ENM";
BA_ "SignalLongName" SG_ 2150227968 PhnSpRcgnApSt "Phone Speech Recognition/Audio Prompt Status";
BA_ "VNSigAllNodes" SG_ 2150227968 PhnSpRcgnApSt 1;
BA_ "GenSigDeltaValue" SG_ 2153914368 EUSS_TrEgUgScrMxScVal 1;
BA_ "GenSigSendType" SG_ 2153914368 EUSS_TrEgUgScrMxScVal 12;
BA_ "GenSigSendOnInit" SG_ 2153914368 EUSS_TrEgUgScrMxScVal 1;
BA_ "VNSigInfotainment" SG_ 2153914368 EUSS_TrEgUgScrMxScVal 1;
BA_ "SignalType" SG_ 2153914368 EUSS_TrEgUgScrMxScVal "SNM";
BA_ "PacketOrder" SG_ 2153914368 EUSS_TrEgUgScrMxScVal 8;
BA_ "SignalLongName" SG_ 2153914368 EUSS_TrEgUgScrMxScVal "Energy Usage Score Scaling : Terrain Energy Usage Score Maximum Scale Value";
BA_ "VNSigAllNodes" SG_ 2153914368 EUSS_TrEgUgScrMxScVal 1;
BA_ "GenSigDeltaValue" SG_ 2153914368 EUSS_TrEgUgScrMnScVal 1;
BA_ "GenSigSendType" SG_ 2153914368 EUSS_TrEgUgScrMnScVal 12;
BA_ "GenSigSendOnInit" SG_ 2153914368 EUSS_TrEgUgScrMnScVal 1;
BA_ "VNSigInfotainment" SG_ 2153914368 EUSS_TrEgUgScrMnScVal 1;
BA_ "SignalType" SG_ 2153914368 EUSS_TrEgUgScrMnScVal "SNM";
BA_ "PacketOrder" SG_ 2153914368 EUSS_TrEgUgScrMnScVal 7;
BA_ "SignalLongName" SG_ 2153914368 EUSS_TrEgUgScrMnScVal "Energy Usage Score Scaling : Terrain Energy Usage Score Minimum Scale Value";
BA_ "VNSigAllNodes" SG_ 2153914368 EUSS_TrEgUgScrMnScVal 1;
BA_ "GenSigDeltaValue" SG_ 2153914368 EUSS_TcEgUgScrMxScVal 1;
BA_ "GenSigSendType" SG_ 2153914368 EUSS_TcEgUgScrMxScVal 12;
BA_ "GenSigSendOnInit" SG_ 2153914368 EUSS_TcEgUgScrMxScVal 1;
BA_ "VNSigInfotainment" SG_ 2153914368 EUSS_TcEgUgScrMxScVal 1;
BA_ "SignalType" SG_ 2153914368 EUSS_TcEgUgScrMxScVal "SNM";
BA_ "PacketOrder" SG_ 2153914368 EUSS_TcEgUgScrMxScVal 6;
BA_ "SignalLongName" SG_ 2153914368 EUSS_TcEgUgScrMxScVal "Energy Usage Score Scaling : Technique Energy Usage Score Maximum Scale Value";
BA_ "VNSigAllNodes" SG_ 2153914368 EUSS_TcEgUgScrMxScVal 1;
BA_ "GenSigDeltaValue" SG_ 2153914368 EUSS_TcEgUgScrMnScVal 1;
BA_ "GenSigSendType" SG_ 2153914368 EUSS_TcEgUgScrMnScVal 12;
BA_ "GenSigSendOnInit" SG_ 2153914368 EUSS_TcEgUgScrMnScVal 1;
BA_ "VNSigInfotainment" SG_ 2153914368 EUSS_TcEgUgScrMnScVal 1;
BA_ "SignalType" SG_ 2153914368 EUSS_TcEgUgScrMnScVal "SNM";
BA_ "PacketOrder" SG_ 2153914368 EUSS_TcEgUgScrMnScVal 5;
BA_ "SignalLongName" SG_ 2153914368 EUSS_TcEgUgScrMnScVal "Energy Usage Score Scaling : Technique Energy Usage Score Minimum Scale Value";
BA_ "VNSigAllNodes" SG_ 2153914368 EUSS_TcEgUgScrMnScVal 1;
BA_ "GenSigDeltaValue" SG_ 2153914368 EUSS_ITEgUgScrMxScVal 1;
BA_ "GenSigSendType" SG_ 2153914368 EUSS_ITEgUgScrMxScVal 12;
BA_ "GenSigSendOnInit" SG_ 2153914368 EUSS_ITEgUgScrMxScVal 1;
BA_ "VNSigInfotainment" SG_ 2153914368 EUSS_ITEgUgScrMxScVal 1;
BA_ "SignalType" SG_ 2153914368 EUSS_ITEgUgScrMxScVal "SNM";
BA_ "PacketOrder" SG_ 2153914368 EUSS_ITEgUgScrMxScVal 4;
BA_ "SignalLongName" SG_ 2153914368 EUSS_ITEgUgScrMxScVal "Energy Usage Score Scaling : Inside Temp Energy Usage Score Max Scale Value";
BA_ "VNSigAllNodes" SG_ 2153914368 EUSS_ITEgUgScrMxScVal 1;
BA_ "GenSigDeltaValue" SG_ 2153914368 EUSS_ITEgUgScrMnScVal 1;
BA_ "GenSigSendType" SG_ 2153914368 EUSS_ITEgUgScrMnScVal 12;
BA_ "GenSigSendOnInit" SG_ 2153914368 EUSS_ITEgUgScrMnScVal 1;
BA_ "VNSigInfotainment" SG_ 2153914368 EUSS_ITEgUgScrMnScVal 1;
BA_ "SignalType" SG_ 2153914368 EUSS_ITEgUgScrMnScVal "SNM";
BA_ "PacketOrder" SG_ 2153914368 EUSS_ITEgUgScrMnScVal 3;
BA_ "SignalLongName" SG_ 2153914368 EUSS_ITEgUgScrMnScVal "Energy Usage Score Scaling : Inside Temp Energy Usage Score Min Scale Value";
BA_ "VNSigAllNodes" SG_ 2153914368 EUSS_ITEgUgScrMnScVal 1;
BA_ "GenSigDeltaValue" SG_ 2153914368 EUSS_OTEgUgScrMxScVal 1;
BA_ "GenSigSendType" SG_ 2153914368 EUSS_OTEgUgScrMxScVal 12;
BA_ "GenSigSendOnInit" SG_ 2153914368 EUSS_OTEgUgScrMxScVal 1;
BA_ "VNSigInfotainment" SG_ 2153914368 EUSS_OTEgUgScrMxScVal 1;
BA_ "SignalType" SG_ 2153914368 EUSS_OTEgUgScrMxScVal "SNM";
BA_ "PacketOrder" SG_ 2153914368 EUSS_OTEgUgScrMxScVal 2;
BA_ "SignalLongName" SG_ 2153914368 EUSS_OTEgUgScrMxScVal "Energy Usage Score Scaling : Outside Temp Energy Usage Score Max Scale Value";
BA_ "VNSigAllNodes" SG_ 2153914368 EUSS_OTEgUgScrMxScVal 1;
BA_ "GenSigDeltaValue" SG_ 2153914368 EUSS_OTEgUgScrMnScVal 1;
BA_ "GenSigSendType" SG_ 2153914368 EUSS_OTEgUgScrMnScVal 12;
BA_ "GenSigSendOnInit" SG_ 2153914368 EUSS_OTEgUgScrMnScVal 1;
BA_ "VNSigInfotainment" SG_ 2153914368 EUSS_OTEgUgScrMnScVal 1;
BA_ "SignalType" SG_ 2153914368 EUSS_OTEgUgScrMnScVal "SNM";
BA_ "PacketOrder" SG_ 2153914368 EUSS_OTEgUgScrMnScVal 1;
BA_ "SignalLongName" SG_ 2153914368 EUSS_OTEgUgScrMnScVal "Energy Usage Score Scaling : Outside Temp Energy Usage Score Min Scale Value";
BA_ "VNSigAllNodes" SG_ 2153914368 EUSS_OTEgUgScrMnScVal 1;
BA_ "GenSigDeltaValue" SG_ 2150580224 CstNonUsbSOCDspLvl 1;
BA_ "GenSigSendType" SG_ 2150580224 CstNonUsbSOCDspLvl 12;
BA_ "GenSigSendOnInit" SG_ 2150580224 CstNonUsbSOCDspLvl 1;
BA_ "SignalType" SG_ 2150580224 CstNonUsbSOCDspLvl "UNM";
BA_ "SignalLongName" SG_ 2150580224 CstNonUsbSOCDspLvl "Customer Non Usable State of Charge Display Level";
BA_ "VNSigAllNodes" SG_ 2150580224 CstNonUsbSOCDspLvl 1;
BA_ "GenSigSendType" SG_ 2150580224 CstmrNonUsblSOCV 10;
BA_ "GenSigSendOnInit" SG_ 2150580224 CstmrNonUsblSOCV 1;
BA_ "SignalType" SG_ 2150580224 CstmrNonUsblSOCV "ENM";
BA_ "SignalLongName" SG_ 2150580224 CstmrNonUsblSOCV "Customer Non Usable State of Charge Validity";
BA_ "VNSigAllNodes" SG_ 2150580224 CstmrNonUsblSOCV 1;
BA_ "GenSigDeltaValue" SG_ 2150580224 CstmrNonUsblSOC 1;
BA_ "GenSigSendType" SG_ 2150580224 CstmrNonUsblSOC 12;
BA_ "GenSigSendOnInit" SG_ 2150580224 CstmrNonUsblSOC 1;
BA_ "SignalType" SG_ 2150580224 CstmrNonUsblSOC "UNM";
BA_ "SignalLongName" SG_ 2150580224 CstmrNonUsblSOC "Customer Non Usable State of Charge";
BA_ "VNSigAllNodes" SG_ 2150580224 CstmrNonUsblSOC 1;
BA_ "GenSigDeltaValue" SG_ 2150580224 PrpDspTtlPwrLvlPct 1;
BA_ "GenSigSendType" SG_ 2150580224 PrpDspTtlPwrLvlPct 12;
BA_ "GenSigSendOnInit" SG_ 2150580224 PrpDspTtlPwrLvlPct 1;
BA_ "VNSigInfotainment" SG_ 2150580224 PrpDspTtlPwrLvlPct 1;
BA_ "SignalType" SG_ 2150580224 PrpDspTtlPwrLvlPct "SNM";
BA_ "SignalLongName" SG_ 2150580224 PrpDspTtlPwrLvlPct "Propulsion Display Total Power Level Percent";
BA_ "VNSigAllNodes" SG_ 2150580224 PrpDspTtlPwrLvlPct 1;
BA_ "SignalType" SG_ 2020 DgnInf "UNM";
BA_ "SignalLongName" SG_ 2020 DgnInf "Diagnostic Information";
BA_ "VNSigDiagnostic" SG_ 2020 DgnInf 1;
BA_ "VNSigAllNodes" SG_ 2020 DgnInf 1;
BA_ "GenSigSendType" SG_ 2151735296 RtSdDetSysServDsbld 10;
BA_ "SignalType" SG_ 2151735296 RtSdDetSysServDsbld "BLN";
BA_ "SignalLongName" SG_ 2151735296 RtSdDetSysServDsbld "Right Side Detection System Service Disabled";
BA_ "VNSigAllNodes" SG_ 2151735296 RtSdDetSysServDsbld 1;
BA_ "GenSigSendType" SG_ 2151735296 RtSdDetSysTmpDsbld 10;
BA_ "SignalType" SG_ 2151735296 RtSdDetSysTmpDsbld "BLN";
BA_ "SignalLongName" SG_ 2151735296 RtSdDetSysTmpDsbld "Right Side Detection System Temp Disabled";
BA_ "VNSigAllNodes" SG_ 2151735296 RtSdDetSysTmpDsbld 1;
BA_ "GenSigSendType" SG_ 2151735296 RtLnChgAlrtEnbld 10;
BA_ "SignalType" SG_ 2151735296 RtLnChgAlrtEnbld "BLN";
BA_ "SignalLongName" SG_ 2151735296 RtLnChgAlrtEnbld "Right Lane Change Alert Enabled";
BA_ "VNSigAllNodes" SG_ 2151735296 RtLnChgAlrtEnbld 1;
BA_ "GenSigSendType" SG_ 2151735296 RtSBZAlrtEnbld 10;
BA_ "SignalType" SG_ 2151735296 RtSBZAlrtEnbld "BLN";
BA_ "SignalLongName" SG_ 2151735296 RtSBZAlrtEnbld "Right Side Blind Zone Alert Enabled";
BA_ "VNSigAllNodes" SG_ 2151735296 RtSBZAlrtEnbld 1;
BA_ "GenSigSendType" SG_ 2151735296 RtRrCrsTrfcAlrtEnbld 10;
BA_ "SignalType" SG_ 2151735296 RtRrCrsTrfcAlrtEnbld "BLN";
BA_ "SignalLongName" SG_ 2151735296 RtRrCrsTrfcAlrtEnbld "Right Rear Cross Traffic Alert Enabled";
BA_ "VNSigAllNodes" SG_ 2151735296 RtRrCrsTrfcAlrtEnbld 1;
BA_ "GenSigSendType" SG_ 2151735296 LnChgAlrtOffIndOn 10;
BA_ "SignalType" SG_ 2151735296 LnChgAlrtOffIndOn "BLN";
BA_ "SignalLongName" SG_ 2151735296 LnChgAlrtOffIndOn "Lane Change Alert Off Indication On";
BA_ "VNSigAllNodes" SG_ 2151735296 LnChgAlrtOffIndOn 1;
BA_ "GenSigSendType" SG_ 2151735296 RrCrsTrfcAlrtOffIO 10;
BA_ "SignalType" SG_ 2151735296 RrCrsTrfcAlrtOffIO "BLN";
BA_ "SignalLongName" SG_ 2151735296 RrCrsTrfcAlrtOffIO "Rear Cross Traffic Alert Off Indication On";
BA_ "VNSigAllNodes" SG_ 2151735296 RrCrsTrfcAlrtOffIO 1;
BA_ "GenSigSendType" SG_ 2151792640 RCTARIC_Indctr1Act 10;
BA_ "SignalType" SG_ 2151792640 RCTARIC_Indctr1Act "BLN";
BA_ "PacketOrder" SG_ 2151792640 RCTARIC_Indctr1Act 1;
BA_ "SignalLongName" SG_ 2151792640 RCTARIC_Indctr1Act "Rear Cross Traffic Alert Right Indication Control : Indicator 1 Active";
BA_ "VNSigAllNodes" SG_ 2151792640 RCTARIC_Indctr1Act 1;
BA_ "GenSigSendType" SG_ 2151792640 RCTARIC_IndReq 10;
BA_ "SignalType" SG_ 2151792640 RCTARIC_IndReq "ENM";
BA_ "PacketOrder" SG_ 2151792640 RCTARIC_IndReq 2;
BA_ "SignalLongName" SG_ 2151792640 RCTARIC_IndReq "Rear Cross Traffic Alert Right Indication Control : Indication Request";
BA_ "VNSigAllNodes" SG_ 2151792640 RCTARIC_IndReq 1;
BA_ "GenSigDeltaValue" SG_ 2151792640 RrCTfcRHptcStRqSqN 1;
BA_ "GenSigSendType" SG_ 2151792640 RrCTfcRHptcStRqSqN 12;
BA_ "SignalType" SG_ 2151792640 RrCTfcRHptcStRqSqN "UNM";
BA_ "SignalLongName" SG_ 2151792640 RrCTfcRHptcStRqSqN "Rear Cross Traffic Alert Right Haptic Seat Request Sequence Number";
BA_ "VNSigAllNodes" SG_ 2151792640 RrCTfcRHptcStRqSqN 1;
BA_ "GenSigDeltaValue" SG_ 2151792640 RrCTfcRHptcStReq 1;
BA_ "GenSigSendType" SG_ 2151792640 RrCTfcRHptcStReq 12;
BA_ "SignalType" SG_ 2151792640 RrCTfcRHptcStReq "UNM";
BA_ "SignalLongName" SG_ 2151792640 RrCTfcRHptcStReq "Rear Cross Traffic Alert Right Haptic Seat Request";
BA_ "VNSigAllNodes" SG_ 2151792640 RrCTfcRHptcStReq 1;
BA_ "GenSigSendType" SG_ 2152546304 BSCWA_ZnEnbd 10;
BA_ "SignalType" SG_ 2152546304 BSCWA_ZnEnbd "BLN";
BA_ "SignalLongName" SG_ 2152546304 BSCWA_ZnEnbd "Backup Sensor Cleaning Wash A: Zone Enabled";
BA_ "VNSigAllNodes" SG_ 2152546304 BSCWA_ZnEnbd 1;
BA_ "GenSigDeltaValue" SG_ 2152546304 BSCWA_Zn6 1;
BA_ "GenSigSendType" SG_ 2152546304 BSCWA_Zn6 12;
BA_ "SignalType" SG_ 2152546304 BSCWA_Zn6 "UNM";
BA_ "SignalLongName" SG_ 2152546304 BSCWA_Zn6 "Backup Sensor Cleaning Wash A: Zone 6";
BA_ "VNSigAllNodes" SG_ 2152546304 BSCWA_Zn6 1;
BA_ "GenSigDeltaValue" SG_ 2152546304 BSCWA_Zn5 1;
BA_ "GenSigSendType" SG_ 2152546304 BSCWA_Zn5 12;
BA_ "SignalType" SG_ 2152546304 BSCWA_Zn5 "UNM";
BA_ "SignalLongName" SG_ 2152546304 BSCWA_Zn5 "Backup Sensor Cleaning Wash A: Zone 5";
BA_ "VNSigAllNodes" SG_ 2152546304 BSCWA_Zn5 1;
BA_ "GenSigDeltaValue" SG_ 2152546304 BSCWA_Zn4 1;
BA_ "GenSigSendType" SG_ 2152546304 BSCWA_Zn4 12;
BA_ "SignalType" SG_ 2152546304 BSCWA_Zn4 "UNM";
BA_ "SignalLongName" SG_ 2152546304 BSCWA_Zn4 "Backup Sensor Cleaning Wash A: Zone 4";
BA_ "VNSigAllNodes" SG_ 2152546304 BSCWA_Zn4 1;
BA_ "GenSigDeltaValue" SG_ 2152546304 BSCWA_Zn1 1;
BA_ "GenSigSendType" SG_ 2152546304 BSCWA_Zn1 12;
BA_ "SignalType" SG_ 2152546304 BSCWA_Zn1 "UNM";
BA_ "SignalLongName" SG_ 2152546304 BSCWA_Zn1 "Backup Sensor Cleaning Wash A: Zone 1";
BA_ "VNSigAllNodes" SG_ 2152546304 BSCWA_Zn1 1;
BA_ "GenSigSendType" SG_ 2152546304 BSCAA_ZnEnbd 10;
BA_ "SignalType" SG_ 2152546304 BSCAA_ZnEnbd "BLN";
BA_ "SignalLongName" SG_ 2152546304 BSCAA_ZnEnbd "Backup Sensor Cleaning Air A: Zone Enabled";
BA_ "VNSigAllNodes" SG_ 2152546304 BSCAA_ZnEnbd 1;
BA_ "GenSigDeltaValue" SG_ 2152546304 BSCAA_Zn6 1;
BA_ "GenSigSendType" SG_ 2152546304 BSCAA_Zn6 12;
BA_ "SignalType" SG_ 2152546304 BSCAA_Zn6 "UNM";
BA_ "SignalLongName" SG_ 2152546304 BSCAA_Zn6 "Backup Sensor Cleaning Air A: Zone 6";
BA_ "VNSigAllNodes" SG_ 2152546304 BSCAA_Zn6 1;
BA_ "GenSigDeltaValue" SG_ 2152546304 BSCAA_Zn5 1;
BA_ "GenSigSendType" SG_ 2152546304 BSCAA_Zn5 12;
BA_ "SignalType" SG_ 2152546304 BSCAA_Zn5 "UNM";
BA_ "SignalLongName" SG_ 2152546304 BSCAA_Zn5 "Backup Sensor Cleaning Air A: Zone 5";
BA_ "VNSigAllNodes" SG_ 2152546304 BSCAA_Zn5 1;
BA_ "GenSigDeltaValue" SG_ 2152546304 BSCAA_Zn4 1;
BA_ "GenSigSendType" SG_ 2152546304 BSCAA_Zn4 12;
BA_ "SignalType" SG_ 2152546304 BSCAA_Zn4 "UNM";
BA_ "SignalLongName" SG_ 2152546304 BSCAA_Zn4 "Backup Sensor Cleaning Air A: Zone 4";
BA_ "VNSigAllNodes" SG_ 2152546304 BSCAA_Zn4 1;
BA_ "GenSigDeltaValue" SG_ 2152546304 BSCAA_Zn1 1;
BA_ "GenSigSendType" SG_ 2152546304 BSCAA_Zn1 12;
BA_ "SignalType" SG_ 2152546304 BSCAA_Zn1 "UNM";
BA_ "SignalLongName" SG_ 2152546304 BSCAA_Zn1 "Backup Sensor Cleaning Air A: Zone 1";
BA_ "VNSigAllNodes" SG_ 2152546304 BSCAA_Zn1 1;
BA_ "GenSigSendType" SG_ 2149941248 PrkAstRrObjSnsngAct 10;
BA_ "GenSigSendOnInit" SG_ 2149941248 PrkAstRrObjSnsngAct 2;
BA_ "SignalType" SG_ 2149941248 PrkAstRrObjSnsngAct "BLN";
BA_ "SignalLongName" SG_ 2149941248 PrkAstRrObjSnsngAct "Park Assistance Rear Object Sensing Active";
BA_ "VNSigAllNodes" SG_ 2149941248 PrkAstRrObjSnsngAct 1;
BA_ "GenSigSendType" SG_ 2149941248 PrkAstRrSysStatUnfltd 10;
BA_ "GenSigSendOnInit" SG_ 2149941248 PrkAstRrSysStatUnfltd 2;
BA_ "SignalType" SG_ 2149941248 PrkAstRrSysStatUnfltd "ENM";
BA_ "SignalLongName" SG_ 2149941248 PrkAstRrSysStatUnfltd "Parking Assistance Rear System Status Unfiltered";
BA_ "VNSigAllNodes" SG_ 2149941248 PrkAstRrSysStatUnfltd 1;
BA_ "GenSigDeltaValue" SG_ 2149941248 PrkAstRrExtdDstUnfltd 1;
BA_ "GenSigSendType" SG_ 2149941248 PrkAstRrExtdDstUnfltd 12;
BA_ "GenSigSendOnInit" SG_ 2149941248 PrkAstRrExtdDstUnfltd 2;
BA_ "SignalType" SG_ 2149941248 PrkAstRrExtdDstUnfltd "UNM";
BA_ "SignalLongName" SG_ 2149941248 PrkAstRrExtdDstUnfltd "Parking Assistance Rear Extended Distance Unfiltered";
BA_ "VNSigAllNodes" SG_ 2149941248 PrkAstRrExtdDstUnfltd 1;
BA_ "GenSigSendType" SG_ 2149941248 PrkAstFntnSnsDstrbdIO 10;
BA_ "GenSigSendOnInit" SG_ 2149941248 PrkAstFntnSnsDstrbdIO 2;
BA_ "SignalType" SG_ 2149941248 PrkAstFntnSnsDstrbdIO "BLN";
BA_ "SignalLongName" SG_ 2149941248 PrkAstFntnSnsDstrbdIO "Parking Assistance Function Sensors Disturbed Indication On";
BA_ "VNSigAllNodes" SG_ 2149941248 PrkAstFntnSnsDstrbdIO 1;
BA_ "GenSigSendType" SG_ 2149941248 PrkAstFntnSnrsBlkd 10;
BA_ "GenSigSendOnInit" SG_ 2149941248 PrkAstFntnSnrsBlkd 2;
BA_ "SignalType" SG_ 2149941248 PrkAstFntnSnrsBlkd "BLN";
BA_ "SignalLongName" SG_ 2149941248 PrkAstFntnSnrsBlkd "Parking Assistance Function Sensors Blocked";
BA_ "VNSigAllNodes" SG_ 2149941248 PrkAstFntnSnrsBlkd 1;
BA_ "GenSigSendType" SG_ 2149941248 PrkAstFntnFld 10;
BA_ "GenSigSendOnInit" SG_ 2149941248 PrkAstFntnFld 2;
BA_ "SignalType" SG_ 2149941248 PrkAstFntnFld "BLN";
BA_ "SignalLongName" SG_ 2149941248 PrkAstFntnFld "Parking Assistance Function Failed";
BA_ "VNSigAllNodes" SG_ 2149941248 PrkAstFntnFld 1;
BA_ "GenSigSendType" SG_ 2149941248 PrkAstFntnDsbldIO 10;
BA_ "GenSigSendOnInit" SG_ 2149941248 PrkAstFntnDsbldIO 2;
BA_ "SignalType" SG_ 2149941248 PrkAstFntnDsbldIO "BLN";
BA_ "SignalLongName" SG_ 2149941248 PrkAstFntnDsbldIO "Parking Assistance Function Disabled Indication On";
BA_ "VNSigAllNodes" SG_ 2149941248 PrkAstFntnDsbldIO 1;
BA_ "GenSigSendType" SG_ 2149941248 PrkAstFntnClnPrkAstIO 10;
BA_ "GenSigSendOnInit" SG_ 2149941248 PrkAstFntnClnPrkAstIO 2;
BA_ "SignalType" SG_ 2149941248 PrkAstFntnClnPrkAstIO "BLN";
BA_ "SignalLongName" SG_ 2149941248 PrkAstFntnClnPrkAstIO "Parking Assistance Function Clean Parking Assist Indication On";
BA_ "VNSigAllNodes" SG_ 2149941248 PrkAstFntnClnPrkAstIO 1;
BA_ "GenSigSendType" SG_ 2149941248 ClsnMtgtnInhbtReqtd 10;
BA_ "GenSigSendOnInit" SG_ 2149941248 ClsnMtgtnInhbtReqtd 2;
BA_ "SignalType" SG_ 2149941248 ClsnMtgtnInhbtReqtd "BLN";
BA_ "SignalLongName" SG_ 2149941248 ClsnMtgtnInhbtReqtd "Collision Mitigation Inhibit Requested";
BA_ "VNSigAllNodes" SG_ 2149941248 ClsnMtgtnInhbtReqtd 1;
BA_ "GenSigSendType" SG_ 2149941248 PARrRgn4ObjStatUnfltd 10;
BA_ "GenSigSendOnInit" SG_ 2149941248 PARrRgn4ObjStatUnfltd 2;
BA_ "SignalType" SG_ 2149941248 PARrRgn4ObjStatUnfltd "ENM";
BA_ "SignalLongName" SG_ 2149941248 PARrRgn4ObjStatUnfltd "Parking Assistance Rear Region 4 Object Status Unfiltered";
BA_ "VNSigAllNodes" SG_ 2149941248 PARrRgn4ObjStatUnfltd 1;
BA_ "GenSigSendType" SG_ 2149941248 PARrRgn3ObjStatUnfltd 10;
BA_ "GenSigSendOnInit" SG_ 2149941248 PARrRgn3ObjStatUnfltd 2;
BA_ "SignalType" SG_ 2149941248 PARrRgn3ObjStatUnfltd "ENM";
BA_ "SignalLongName" SG_ 2149941248 PARrRgn3ObjStatUnfltd "Parking Assistance Rear Region 3 Object Status Unfiltered";
BA_ "VNSigAllNodes" SG_ 2149941248 PARrRgn3ObjStatUnfltd 1;
BA_ "GenSigSendType" SG_ 2149941248 PARrRgn2ObjStatUnfltd 10;
BA_ "GenSigSendOnInit" SG_ 2149941248 PARrRgn2ObjStatUnfltd 2;
BA_ "SignalType" SG_ 2149941248 PARrRgn2ObjStatUnfltd "ENM";
BA_ "SignalLongName" SG_ 2149941248 PARrRgn2ObjStatUnfltd "Parking Assistance Rear Region 2 Object Status Unfiltered";
BA_ "VNSigAllNodes" SG_ 2149941248 PARrRgn2ObjStatUnfltd 1;
BA_ "GenSigSendType" SG_ 2149941248 PARrRgn1ObjStatUnfltd 10;
BA_ "GenSigSendOnInit" SG_ 2149941248 PARrRgn1ObjStatUnfltd 2;
BA_ "SignalType" SG_ 2149941248 PARrRgn1ObjStatUnfltd "ENM";
BA_ "SignalLongName" SG_ 2149941248 PARrRgn1ObjStatUnfltd "Parking Assistance Rear Region 1 Object Status Unfiltered";
BA_ "VNSigAllNodes" SG_ 2149941248 PARrRgn1ObjStatUnfltd 1;
BA_ "GenSigSendType" SG_ 2156314624 HVChrgSysSplyFltIO 10;
BA_ "SignalType" SG_ 2156314624 HVChrgSysSplyFltIO "BLN";
BA_ "SignalLongName" SG_ 2156314624 HVChrgSysSplyFltIO "High Voltage Charging System Supply Fault Indication On";
BA_ "VNSigAllNodes" SG_ 2156314624 HVChrgSysSplyFltIO 1;
BA_ "GenSigSendType" SG_ 2156314624 OffBrdCSFltDtctd 10;
BA_ "VNSigInfotainment" SG_ 2156314624 OffBrdCSFltDtctd 1;
BA_ "SignalType" SG_ 2156314624 OffBrdCSFltDtctd "BLN";
BA_ "SignalLongName" SG_ 2156314624 OffBrdCSFltDtctd "Off Board Charge Station Fault Detected";
BA_ "VNSigAllNodes" SG_ 2156314624 OffBrdCSFltDtctd 1;
BA_ "GenSigSendType" SG_ 2156314624 OBVhCsACChgRqBnVs 10;
BA_ "GenSigSendOnInit" SG_ 2156314624 OBVhCsACChgRqBnVs 1;
BA_ "VNSigInfotainment" SG_ 2156314624 OBVhCsACChgRqBnVs 1;
BA_ "SignalType" SG_ 2156314624 OBVhCsACChgRqBnVs "BLN";
BA_ "SignalLongName" SG_ 2156314624 OBVhCsACChgRqBnVs "On Board Vehicle Cease AC Charging Request Button Visible";
BA_ "VNSigAllNodes" SG_ 2156314624 OBVhCsACChgRqBnVs 1;
BA_ "GenSigDeltaValue" SG_ 2156314624 TODCNPDT_Min 1;
BA_ "GenSigSendType" SG_ 2156314624 TODCNPDT_Min 12;
BA_ "GenSigSendOnInit" SG_ 2156314624 TODCNPDT_Min 1;
BA_ "VNSigInfotainment" SG_ 2156314624 TODCNPDT_Min 1;
BA_ "SignalType" SG_ 2156314624 TODCNPDT_Min "UNM";
BA_ "PacketOrder" SG_ 2156314624 TODCNPDT_Min 3;
BA_ "SignalLongName" SG_ 2156314624 TODCNPDT_Min "Time Of Day Charging Next Planned Departure Time : Minute";
BA_ "VNSigAllNodes" SG_ 2156314624 TODCNPDT_Min 1;
BA_ "GenSigDeltaValue" SG_ 2156314624 TODCNPDT_Hr 1;
BA_ "GenSigSendType" SG_ 2156314624 TODCNPDT_Hr 12;
BA_ "GenSigSendOnInit" SG_ 2156314624 TODCNPDT_Hr 1;
BA_ "VNSigInfotainment" SG_ 2156314624 TODCNPDT_Hr 1;
BA_ "SignalType" SG_ 2156314624 TODCNPDT_Hr "UNM";
BA_ "PacketOrder" SG_ 2156314624 TODCNPDT_Hr 2;
BA_ "SignalLongName" SG_ 2156314624 TODCNPDT_Hr "Time Of Day Charging Next Planned Departure Time : Hour";
BA_ "VNSigAllNodes" SG_ 2156314624 TODCNPDT_Hr 1;
BA_ "GenSigSendType" SG_ 2156314624 TODCNPDT_DyOfWk 10;
BA_ "GenSigSendOnInit" SG_ 2156314624 TODCNPDT_DyOfWk 1;
BA_ "VNSigInfotainment" SG_ 2156314624 TODCNPDT_DyOfWk 1;
BA_ "SignalType" SG_ 2156314624 TODCNPDT_DyOfWk "ENM";
BA_ "PacketOrder" SG_ 2156314624 TODCNPDT_DyOfWk 1;
BA_ "SignalLongName" SG_ 2156314624 TODCNPDT_DyOfWk "Time Of Day Charging Next Planned Departure Time : Day of Week";
BA_ "VNSigAllNodes" SG_ 2156314624 TODCNPDT_DyOfWk 1;
BA_ "GenSigDeltaValue" SG_ 2156314624 HVBatBlkSOC 1;
BA_ "GenSigSendType" SG_ 2156314624 HVBatBlkSOC 12;
BA_ "GenSigSendOnInit" SG_ 2156314624 HVBatBlkSOC 1;
BA_ "VNSigInfotainment" SG_ 2156314624 HVBatBlkSOC 1;
BA_ "SignalType" SG_ 2156314624 HVBatBlkSOC "UNM";
BA_ "SignalLongName" SG_ 2156314624 HVBatBlkSOC "High Voltage Battery Bulk State of Charge";
BA_ "VNSigAllNodes" SG_ 2156314624 HVBatBlkSOC 1;
BA_ "GenSigSendType" SG_ 2156314624 TODCOpMd 10;
BA_ "VNSigInfotainment" SG_ 2156314624 TODCOpMd 1;
BA_ "SignalType" SG_ 2156314624 TODCOpMd "ENM";
BA_ "SignalLongName" SG_ 2156314624 TODCOpMd "Time of Day Charging Operating Mode";
BA_ "VNSigAllNodes" SG_ 2156314624 TODCOpMd 1;
BA_ "GenSigSendType" SG_ 2156314624 TODCDMPTO_TpOvR 10;
BA_ "GenSigSendOnInit" SG_ 2156314624 TODCDMPTO_TpOvR 1;
BA_ "VNSigInfotainment" SG_ 2156314624 TODCDMPTO_TpOvR 1;
BA_ "SignalType" SG_ 2156314624 TODCDMPTO_TpOvR "ENM";
BA_ "PacketOrder" SG_ 2156314624 TODCDMPTO_TpOvR 2;
BA_ "SignalLongName" SG_ 2156314624 TODCDMPTO_TpOvR "Time of Day Charging Display Main Page Temporary Override : Display Temporary Override Request";
BA_ "VNSigAllNodes" SG_ 2156314624 TODCDMPTO_TpOvR 1;
BA_ "GenSigSendType" SG_ 2156314624 TODCDMPTO_CmPgR 10;
BA_ "GenSigSendOnInit" SG_ 2156314624 TODCDMPTO_CmPgR 1;
BA_ "VNSigInfotainment" SG_ 2156314624 TODCDMPTO_CmPgR 1;
BA_ "SignalType" SG_ 2156314624 TODCDMPTO_CmPgR "BLN";
BA_ "PacketOrder" SG_ 2156314624 TODCDMPTO_CmPgR 1;
BA_ "SignalLongName" SG_ 2156314624 TODCDMPTO_CmPgR "Time of Day Charging Display Main Page Temporary Override : Charging Complete Page Requested";
BA_ "VNSigAllNodes" SG_ 2156314624 TODCDMPTO_CmPgR 1;
BA_ "GenSigSendType" SG_ 2156314624 HVChrgSysStNot 10;
BA_ "VNSigInfotainment" SG_ 2156314624 HVChrgSysStNot 1;
BA_ "SignalType" SG_ 2156314624 HVChrgSysStNot "ENM";
BA_ "SignalLongName" SG_ 2156314624 HVChrgSysStNot "High Voltage Charger System Status Notification";
BA_ "VNSigAllNodes" SG_ 2156314624 HVChrgSysStNot 1;
BA_ "GenSigSendType" SG_ 2156314624 HVChrgAbrtRsn 10;
BA_ "VNSigInfotainment" SG_ 2156314624 HVChrgAbrtRsn 1;
BA_ "SignalType" SG_ 2156314624 HVChrgAbrtRsn "ENM";
BA_ "SignalLongName" SG_ 2156314624 HVChrgAbrtRsn "High Voltage Charge Abort Reason";
BA_ "VNSigAllNodes" SG_ 2156314624 HVChrgAbrtRsn 1;
BA_ "GenSigSendType" SG_ 2156314624 HVCSCLPD_UsrIntTyp 10;
BA_ "GenSigSendOnInit" SG_ 2156314624 HVCSCLPD_UsrIntTyp 1;
BA_ "VNSigInfotainment" SG_ 2156314624 HVCSCLPD_UsrIntTyp 1;
BA_ "SignalType" SG_ 2156314624 HVCSCLPD_UsrIntTyp "ENM";
BA_ "PacketOrder" SG_ 2156314624 HVCSCLPD_UsrIntTyp 1;
BA_ "SignalLongName" SG_ 2156314624 HVCSCLPD_UsrIntTyp "High Voltage Charging System Charge Level Preference Data : User Interface Type";
BA_ "VNSigAllNodes" SG_ 2156314624 HVCSCLPD_UsrIntTyp 1;
BA_ "GenSigDeltaValue" SG_ 2156314624 HVCSCLPD_RdCrntLv3 1;
BA_ "GenSigSendType" SG_ 2156314624 HVCSCLPD_RdCrntLv3 12;
BA_ "GenSigSendOnInit" SG_ 2156314624 HVCSCLPD_RdCrntLv3 1;
BA_ "VNSigInfotainment" SG_ 2156314624 HVCSCLPD_RdCrntLv3 1;
BA_ "SignalType" SG_ 2156314624 HVCSCLPD_RdCrntLv3 "UNM";
BA_ "PacketOrder" SG_ 2156314624 HVCSCLPD_RdCrntLv3 6;
BA_ "SignalLongName" SG_ 2156314624 HVCSCLPD_RdCrntLv3 "High Voltage Charging System Charge Level Preference Data : Reduced Current Level 3";
BA_ "VNSigAllNodes" SG_ 2156314624 HVCSCLPD_RdCrntLv3 1;
BA_ "GenSigDeltaValue" SG_ 2156314624 HVCSCLPD_RdCrntLv2 1;
BA_ "GenSigSendType" SG_ 2156314624 HVCSCLPD_RdCrntLv2 12;
BA_ "GenSigSendOnInit" SG_ 2156314624 HVCSCLPD_RdCrntLv2 1;
BA_ "VNSigInfotainment" SG_ 2156314624 HVCSCLPD_RdCrntLv2 1;
BA_ "SignalType" SG_ 2156314624 HVCSCLPD_RdCrntLv2 "UNM";
BA_ "PacketOrder" SG_ 2156314624 HVCSCLPD_RdCrntLv2 5;
BA_ "SignalLongName" SG_ 2156314624 HVCSCLPD_RdCrntLv2 "High Voltage Charging System Charge Level Preference Data : Reduced Current Level 2";
BA_ "VNSigAllNodes" SG_ 2156314624 HVCSCLPD_RdCrntLv2 1;
BA_ "GenSigDeltaValue" SG_ 2156314624 HVCSCLPD_RdCrntLv1 1;
BA_ "GenSigSendType" SG_ 2156314624 HVCSCLPD_RdCrntLv1 12;
BA_ "GenSigSendOnInit" SG_ 2156314624 HVCSCLPD_RdCrntLv1 1;
BA_ "VNSigInfotainment" SG_ 2156314624 HVCSCLPD_RdCrntLv1 1;
BA_ "SignalType" SG_ 2156314624 HVCSCLPD_RdCrntLv1 "UNM";
BA_ "PacketOrder" SG_ 2156314624 HVCSCLPD_RdCrntLv1 4;
BA_ "SignalLongName" SG_ 2156314624 HVCSCLPD_RdCrntLv1 "High Voltage Charging System Charge Level Preference Data : Reduced Current Level 1";
BA_ "VNSigAllNodes" SG_ 2156314624 HVCSCLPD_RdCrntLv1 1;
BA_ "GenSigDeltaValue" SG_ 2156314624 HVCSCLPD_NrmChrgC 1;
BA_ "GenSigSendType" SG_ 2156314624 HVCSCLPD_NrmChrgC 12;
BA_ "GenSigSendOnInit" SG_ 2156314624 HVCSCLPD_NrmChrgC 1;
BA_ "VNSigInfotainment" SG_ 2156314624 HVCSCLPD_NrmChrgC 1;
BA_ "SignalType" SG_ 2156314624 HVCSCLPD_NrmChrgC "UNM";
BA_ "PacketOrder" SG_ 2156314624 HVCSCLPD_NrmChrgC 3;
BA_ "SignalLongName" SG_ 2156314624 HVCSCLPD_NrmChrgC "High Voltage Charging System Charge Level Preference Data : Normal Charge Current";
BA_ "VNSigAllNodes" SG_ 2156314624 HVCSCLPD_NrmChrgC 1;
BA_ "GenSigSendType" SG_ 2156314624 HVCSCLPD_ChgLvlPfS 10;
BA_ "GenSigSendOnInit" SG_ 2156314624 HVCSCLPD_ChgLvlPfS 1;
BA_ "VNSigInfotainment" SG_ 2156314624 HVCSCLPD_ChgLvlPfS 1;
BA_ "SignalType" SG_ 2156314624 HVCSCLPD_ChgLvlPfS "ENM";
BA_ "PacketOrder" SG_ 2156314624 HVCSCLPD_ChgLvlPfS 2;
BA_ "SignalLongName" SG_ 2156314624 HVCSCLPD_ChgLvlPfS "High Voltage Charging System Charge Level Preference Data : Charge Level Preference Status";
BA_ "VNSigAllNodes" SG_ 2156314624 HVCSCLPD_ChgLvlPfS 1;
BA_ "GenSigSendType" SG_ 2150449152 ESPDrvrExtIO 10;
BA_ "SignalType" SG_ 2150449152 ESPDrvrExtIO "BLN";
BA_ "SignalLongName" SG_ 2150449152 ESPDrvrExtIO "Electronic Shift Primary Driver Exit Indication On";
BA_ "VNSigAllNodes" SG_ 2150449152 ESPDrvrExtIO 1;
BA_ "GenSigSendType" SG_ 2150449152 ESPDrvrDrStIndtrmntIO 10;
BA_ "SignalType" SG_ 2150449152 ESPDrvrDrStIndtrmntIO "BLN";
BA_ "SignalLongName" SG_ 2150449152 ESPDrvrDrStIndtrmntIO "Electronic Shift Primary Driver Door State Indeterminate Indication On";
BA_ "VNSigAllNodes" SG_ 2150449152 ESPDrvrDrStIndtrmntIO 1;
BA_ "GenSigSendType" SG_ 2150449152 ESPAutoPrkIO 10;
BA_ "SignalType" SG_ 2150449152 ESPAutoPrkIO "BLN";
BA_ "SignalLongName" SG_ 2150449152 ESPAutoPrkIO "Electronic Shift Primary Auto Park Indication On";
BA_ "VNSigAllNodes" SG_ 2150449152 ESPAutoPrkIO 1;
BA_ "GenSigSendType" SG_ 2150449152 ASIRI_Indication08 10;
BA_ "SignalType" SG_ 2150449152 ASIRI_Indication08 "BLN";
BA_ "PacketOrder" SG_ 2150449152 ASIRI_Indication08 8;
BA_ "SignalLongName" SG_ 2150449152 ASIRI_Indication08 "Auto Stop Inhibit Reason Indication : Indication 8";
BA_ "VNSigAllNodes" SG_ 2150449152 ASIRI_Indication08 1;
BA_ "GenSigSendType" SG_ 2150449152 ASIRI_Indication07 10;
BA_ "SignalType" SG_ 2150449152 ASIRI_Indication07 "BLN";
BA_ "PacketOrder" SG_ 2150449152 ASIRI_Indication07 7;
BA_ "SignalLongName" SG_ 2150449152 ASIRI_Indication07 "Auto Stop Inhibit Reason Indication : Indication 7";
BA_ "VNSigAllNodes" SG_ 2150449152 ASIRI_Indication07 1;
BA_ "GenSigSendType" SG_ 2150449152 ASIRI_Indication06 10;
BA_ "SignalType" SG_ 2150449152 ASIRI_Indication06 "BLN";
BA_ "PacketOrder" SG_ 2150449152 ASIRI_Indication06 6;
BA_ "SignalLongName" SG_ 2150449152 ASIRI_Indication06 "Auto Stop Inhibit Reason Indication : Indication 6";
BA_ "VNSigAllNodes" SG_ 2150449152 ASIRI_Indication06 1;
BA_ "GenSigSendType" SG_ 2150449152 ASIRI_Indication05 10;
BA_ "SignalType" SG_ 2150449152 ASIRI_Indication05 "BLN";
BA_ "PacketOrder" SG_ 2150449152 ASIRI_Indication05 5;
BA_ "SignalLongName" SG_ 2150449152 ASIRI_Indication05 "Auto Stop Inhibit Reason Indication : Indication 5";
BA_ "VNSigAllNodes" SG_ 2150449152 ASIRI_Indication05 1;
BA_ "GenSigSendType" SG_ 2150449152 ASIRI_Indication04 10;
BA_ "SignalType" SG_ 2150449152 ASIRI_Indication04 "BLN";
BA_ "PacketOrder" SG_ 2150449152 ASIRI_Indication04 4;
BA_ "SignalLongName" SG_ 2150449152 ASIRI_Indication04 "Auto Stop Inhibit Reason Indication : Indication 4";
BA_ "VNSigAllNodes" SG_ 2150449152 ASIRI_Indication04 1;
BA_ "GenSigSendType" SG_ 2150449152 ASIRI_Indication03 10;
BA_ "SignalType" SG_ 2150449152 ASIRI_Indication03 "BLN";
BA_ "PacketOrder" SG_ 2150449152 ASIRI_Indication03 3;
BA_ "SignalLongName" SG_ 2150449152 ASIRI_Indication03 "Auto Stop Inhibit Reason Indication : Indication 3";
BA_ "VNSigAllNodes" SG_ 2150449152 ASIRI_Indication03 1;
BA_ "GenSigSendType" SG_ 2150449152 ASIRI_Indication02 10;
BA_ "SignalType" SG_ 2150449152 ASIRI_Indication02 "BLN";
BA_ "PacketOrder" SG_ 2150449152 ASIRI_Indication02 2;
BA_ "SignalLongName" SG_ 2150449152 ASIRI_Indication02 "Auto Stop Inhibit Reason Indication : Indication 2";
BA_ "VNSigAllNodes" SG_ 2150449152 ASIRI_Indication02 1;
BA_ "GenSigSendType" SG_ 2150449152 ASIRI_Indication01 10;
BA_ "SignalType" SG_ 2150449152 ASIRI_Indication01 "BLN";
BA_ "PacketOrder" SG_ 2150449152 ASIRI_Indication01 1;
BA_ "SignalLongName" SG_ 2150449152 ASIRI_Indication01 "Auto Stop Inhibit Reason Indication : Indication 1";
BA_ "VNSigAllNodes" SG_ 2150449152 ASIRI_Indication01 1;
BA_ "GenSigSendType" SG_ 2150449152 SpdLmtrSttngTypAct 10;
BA_ "SignalType" SG_ 2150449152 SpdLmtrSttngTypAct "ENM";
BA_ "SignalLongName" SG_ 2150449152 SpdLmtrSttngTypAct "Speed Limiter Setting Type Active";
BA_ "VNSigAllNodes" SG_ 2150449152 SpdLmtrSttngTypAct 1;
BA_ "GenSigSendType" SG_ 2150449152 EngInltSpcfcHmdtyV 10;
BA_ "SignalType" SG_ 2150449152 EngInltSpcfcHmdtyV "ENM";
BA_ "SignalLongName" SG_ 2150449152 EngInltSpcfcHmdtyV "Engine Inlet Specific Humidity Validity";
BA_ "VNSigAllNodes" SG_ 2150449152 EngInltSpcfcHmdtyV 1;
BA_ "GenSigSendType" SG_ 2150449152 EngInltSpcfcHmdtyM 10;
BA_ "SignalType" SG_ 2150449152 EngInltSpcfcHmdtyM "ENM";
BA_ "SignalLongName" SG_ 2150449152 EngInltSpcfcHmdtyM "Engine Inlet Specific Humidity Mask";
BA_ "VNSigAllNodes" SG_ 2150449152 EngInltSpcfcHmdtyM 1;
BA_ "GenSigDeltaValue" SG_ 2150449152 EngInltSpcfcHmdty 1;
BA_ "GenSigSendType" SG_ 2150449152 EngInltSpcfcHmdty 12;
BA_ "SignalType" SG_ 2150449152 EngInltSpcfcHmdty "UNM";
BA_ "SignalLongName" SG_ 2150449152 EngInltSpcfcHmdty "Engine Inlet Specific Humidity";
BA_ "VNSigAllNodes" SG_ 2150449152 EngInltSpcfcHmdty 1;
BA_ "GenSigSendType" SG_ 2149793792 FCACustStngAvlbl 10;
BA_ "GenSigSendOnInit" SG_ 2149793792 FCACustStngAvlbl 2;
BA_ "SignalType" SG_ 2149793792 FCACustStngAvlbl "BLN";
BA_ "SignalLongName" SG_ 2149793792 FCACustStngAvlbl "Forward Collision Alert Customization Setting Available";
BA_ "VNSigAllNodes" SG_ 2149793792 FCACustStngAvlbl 1;
BA_ "GenSigSendType" SG_ 2149793792 FwdClnAlrtCustCrntSetngVal 10;
BA_ "GenSigSendOnInit" SG_ 2149793792 FwdClnAlrtCustCrntSetngVal 2;
BA_ "SignalType" SG_ 2149793792 FwdClnAlrtCustCrntSetngVal "ENM";
BA_ "SignalLongName" SG_ 2149793792 FwdClnAlrtCustCrntSetngVal "Forward Collision Alert Customization Current Setting Value";
BA_ "VNSigAllNodes" SG_ 2149793792 FwdClnAlrtCustCrntSetngVal 1;
BA_ "GenSigSendType" SG_ 2150080512 LBCVLS_VehGPSLctV 10;
BA_ "GenSigSendOnInit" SG_ 2150080512 LBCVLS_VehGPSLctV 1;
BA_ "PacketOrder" SG_ 2150080512 LBCVLS_VehGPSLctV 1;
BA_ "VNSigInfotainment" SG_ 2150080512 LBCVLS_VehGPSLctV 1;
BA_ "SignalType" SG_ 2150080512 LBCVLS_VehGPSLctV "ENM";
BA_ "SignalLongName" SG_ 2150080512 LBCVLS_VehGPSLctV "Location Based Charging Vehicle Location Status : Vehicle GPS Location Validity";
BA_ "VNSigAllNodes" SG_ 2150080512 LBCVLS_VehGPSLctV 1;
BA_ "GenSigSendType" SG_ 2150080512 LBCVLS_VehGPSLct 10;
BA_ "GenSigSendOnInit" SG_ 2150080512 LBCVLS_VehGPSLct 1;
BA_ "PacketOrder" SG_ 2150080512 LBCVLS_VehGPSLct 2;
BA_ "VNSigInfotainment" SG_ 2150080512 LBCVLS_VehGPSLct 1;
BA_ "SignalType" SG_ 2150080512 LBCVLS_VehGPSLct "ENM";
BA_ "SignalLongName" SG_ 2150080512 LBCVLS_VehGPSLct "Location Based Charging Vehicle Location Status : Vehicle GPS Location";
BA_ "VNSigAllNodes" SG_ 2150080512 LBCVLS_VehGPSLct 1;
BA_ "GenSigSendType" SG_ 2150080512 LBCPSS_PosUpdtStat 10;
BA_ "GenSigSendOnInit" SG_ 2150080512 LBCPSS_PosUpdtStat 1;
BA_ "VNSigInfotainment" SG_ 2150080512 LBCPSS_PosUpdtStat 1;
BA_ "SignalType" SG_ 2150080512 LBCPSS_PosUpdtStat "ENM";
BA_ "PacketOrder" SG_ 2150080512 LBCPSS_PosUpdtStat 1;
BA_ "SignalLongName" SG_ 2150080512 LBCPSS_PosUpdtStat "Location Based Charging Position Storage Status : Position Update Status";
BA_ "VNSigAllNodes" SG_ 2150080512 LBCPSS_PosUpdtStat 1;
BA_ "GenSigSendType" SG_ 2150080512 LBCPSS_PosUpdtLct 10;
BA_ "GenSigSendOnInit" SG_ 2150080512 LBCPSS_PosUpdtLct 1;
BA_ "VNSigInfotainment" SG_ 2150080512 LBCPSS_PosUpdtLct 1;
BA_ "SignalType" SG_ 2150080512 LBCPSS_PosUpdtLct "ENM";
BA_ "PacketOrder" SG_ 2150080512 LBCPSS_PosUpdtLct 2;
BA_ "SignalLongName" SG_ 2150080512 LBCPSS_PosUpdtLct "Location Based Charging Position Storage Status : Position Update Location";
BA_ "VNSigAllNodes" SG_ 2150080512 LBCPSS_PosUpdtLct 1;
BA_ "GenSigSendType" SG_ 2150080512 LBCCsStAvl 10;
BA_ "GenSigSendOnInit" SG_ 2150080512 LBCCsStAvl 1;
BA_ "VNSigInfotainment" SG_ 2150080512 LBCCsStAvl 1;
BA_ "SignalType" SG_ 2150080512 LBCCsStAvl "BLN";
BA_ "SignalLongName" SG_ 2150080512 LBCCsStAvl "Location Based Charging Customization Setting Available";
BA_ "VNSigAllNodes" SG_ 2150080512 LBCCsStAvl 1;
BA_ "GenSigSendType" SG_ 2150080512 LBCCsCrStVal 10;
BA_ "GenSigSendOnInit" SG_ 2150080512 LBCCsCrStVal 1;
BA_ "VNSigInfotainment" SG_ 2150080512 LBCCsCrStVal 1;
BA_ "SignalType" SG_ 2150080512 LBCCsCrStVal "ENM";
BA_ "SignalLongName" SG_ 2150080512 LBCCsCrStVal "Location Based Charging Customization Current Setting Value";
BA_ "VNSigAllNodes" SG_ 2150080512 LBCCsCrStVal 1;
BA_ "GenSigSendType" SG_ 2150080512 LBCCF_Lct4PosStrdIO 10;
BA_ "GenSigSendOnInit" SG_ 2150080512 LBCCF_Lct4PosStrdIO 1;
BA_ "VNSigInfotainment" SG_ 2150080512 LBCCF_Lct4PosStrdIO 1;
BA_ "SignalType" SG_ 2150080512 LBCCF_Lct4PosStrdIO "BLN";
BA_ "PacketOrder" SG_ 2150080512 LBCCF_Lct4PosStrdIO 4;
BA_ "SignalLongName" SG_ 2150080512 LBCCF_Lct4PosStrdIO "Location Based Charging Customer Feedback : Location 4 Position Stored Indication On";
BA_ "VNSigAllNodes" SG_ 2150080512 LBCCF_Lct4PosStrdIO 1;
BA_ "GenSigSendType" SG_ 2150080512 LBCCF_Lct3PosStrdIO 10;
BA_ "GenSigSendOnInit" SG_ 2150080512 LBCCF_Lct3PosStrdIO 1;
BA_ "VNSigInfotainment" SG_ 2150080512 LBCCF_Lct3PosStrdIO 1;
BA_ "SignalType" SG_ 2150080512 LBCCF_Lct3PosStrdIO "BLN";
BA_ "PacketOrder" SG_ 2150080512 LBCCF_Lct3PosStrdIO 3;
BA_ "SignalLongName" SG_ 2150080512 LBCCF_Lct3PosStrdIO "Location Based Charging Customer Feedback : Location 3 Position Stored Indication On";
BA_ "VNSigAllNodes" SG_ 2150080512 LBCCF_Lct3PosStrdIO 1;
BA_ "GenSigSendType" SG_ 2150080512 LBCCF_Lct2PosStrdIO 10;
BA_ "GenSigSendOnInit" SG_ 2150080512 LBCCF_Lct2PosStrdIO 1;
BA_ "VNSigInfotainment" SG_ 2150080512 LBCCF_Lct2PosStrdIO 1;
BA_ "SignalType" SG_ 2150080512 LBCCF_Lct2PosStrdIO "BLN";
BA_ "PacketOrder" SG_ 2150080512 LBCCF_Lct2PosStrdIO 2;
BA_ "SignalLongName" SG_ 2150080512 LBCCF_Lct2PosStrdIO "Location Based Charging Customer Feedback : Location 2 Position Stored Indication On";
BA_ "VNSigAllNodes" SG_ 2150080512 LBCCF_Lct2PosStrdIO 1;
BA_ "GenSigSendType" SG_ 2150080512 LBCCF_Lct1PosStrdIO 10;
BA_ "GenSigSendOnInit" SG_ 2150080512 LBCCF_Lct1PosStrdIO 1;
BA_ "VNSigInfotainment" SG_ 2150080512 LBCCF_Lct1PosStrdIO 1;
BA_ "SignalType" SG_ 2150080512 LBCCF_Lct1PosStrdIO "BLN";
BA_ "PacketOrder" SG_ 2150080512 LBCCF_Lct1PosStrdIO 1;
BA_ "SignalLongName" SG_ 2150080512 LBCCF_Lct1PosStrdIO "Location Based Charging Customer Feedback : Location 1 Position Stored Indication On";
BA_ "VNSigAllNodes" SG_ 2150080512 LBCCF_Lct1PosStrdIO 1;
BA_ "GenSigSendType" SG_ 2150080512 LBCCDRR_PosNumbr 10;
BA_ "VNSigInfotainment" SG_ 2150080512 LBCCDRR_PosNumbr 1;
BA_ "SignalType" SG_ 2150080512 LBCCDRR_PosNumbr "ENM";
BA_ "PacketOrder" SG_ 2150080512 LBCCDRR_PosNumbr 2;
BA_ "SignalLongName" SG_ 2150080512 LBCCDRR_PosNumbr "Location Based Charging Customer Data Reset Response : Position Number";
BA_ "VNSigAllNodes" SG_ 2150080512 LBCCDRR_PosNumbr 1;
BA_ "GenSigSendType" SG_ 2150080512 LBCCDRR_ClrStrdPosResp 10;
BA_ "VNSigInfotainment" SG_ 2150080512 LBCCDRR_ClrStrdPosResp 1;
BA_ "SignalType" SG_ 2150080512 LBCCDRR_ClrStrdPosResp "ENM";
BA_ "PacketOrder" SG_ 2150080512 LBCCDRR_ClrStrdPosResp 1;
BA_ "SignalLongName" SG_ 2150080512 LBCCDRR_ClrStrdPosResp "Location Based Charging Customer Data Reset Response : Clear Stored Position response";
BA_ "VNSigAllNodes" SG_ 2150080512 LBCCDRR_ClrStrdPosResp 1;
BA_ "GenSigDeltaValue" SG_ 2150080512 ChrgCyclOvrlEngyEcnEq 1;
BA_ "GenSigSendType" SG_ 2150080512 ChrgCyclOvrlEngyEcnEq 12;
BA_ "GenSigSendOnInit" SG_ 2150080512 ChrgCyclOvrlEngyEcnEq 1;
BA_ "VNSigInfotainment" SG_ 2150080512 ChrgCyclOvrlEngyEcnEq 1;
BA_ "SignalType" SG_ 2150080512 ChrgCyclOvrlEngyEcnEq "UNM";
BA_ "SignalLongName" SG_ 2150080512 ChrgCyclOvrlEngyEcnEq "Charge Cycle Overall Energy Economy Equivalent";
BA_ "VNSigAllNodes" SG_ 2150080512 ChrgCyclOvrlEngyEcnEq 1;
BA_ "GenSigDeltaValue" SG_ 2150080512 ChrgCyclElecEngyEcnEq 1;
BA_ "GenSigSendType" SG_ 2150080512 ChrgCyclElecEngyEcnEq 12;
BA_ "GenSigSendOnInit" SG_ 2150080512 ChrgCyclElecEngyEcnEq 1;
BA_ "VNSigInfotainment" SG_ 2150080512 ChrgCyclElecEngyEcnEq 1;
BA_ "SignalType" SG_ 2150080512 ChrgCyclElecEngyEcnEq "UNM";
BA_ "SignalLongName" SG_ 2150080512 ChrgCyclElecEngyEcnEq "Charge Cycle Electrical Energy Economy Equivalent";
BA_ "VNSigAllNodes" SG_ 2150080512 ChrgCyclElecEngyEcnEq 1;
BA_ "GenSigSendType" SG_ 2150080512 LBCChrgLvlPrfExpIO 10;
BA_ "GenSigSendOnInit" SG_ 2150080512 LBCChrgLvlPrfExpIO 1;
BA_ "VNSigInfotainment" SG_ 2150080512 LBCChrgLvlPrfExpIO 1;
BA_ "SignalType" SG_ 2150080512 LBCChrgLvlPrfExpIO "BLN";
BA_ "SignalLongName" SG_ 2150080512 LBCChrgLvlPrfExpIO "Location Based Charging Charge Level Preference Expiration Indication On";
BA_ "VNSigAllNodes" SG_ 2150080512 LBCChrgLvlPrfExpIO 1;
BA_ "GenSigSendType" SG_ 2150080512 EngAstHtDfrdHtMdAct 10;
BA_ "SignalType" SG_ 2150080512 EngAstHtDfrdHtMdAct "BLN";
BA_ "SignalLongName" SG_ 2150080512 EngAstHtDfrdHtMdAct "Engine Assisted Heating Deferred Heat Mode Active";
BA_ "VNSigAllNodes" SG_ 2150080512 EngAstHtDfrdHtMdAct 1;
BA_ "GenSigSendType" SG_ 2150080512 AuxClntHtrVlvStat 10;
BA_ "GenSigSendOnInit" SG_ 2150080512 AuxClntHtrVlvStat 1;
BA_ "SignalType" SG_ 2150080512 AuxClntHtrVlvStat "ENM";
BA_ "SignalLongName" SG_ 2150080512 AuxClntHtrVlvStat "Auxiliary Coolant Heater Valve Status";
BA_ "VNSigAllNodes" SG_ 2150080512 AuxClntHtrVlvStat 1;
BA_ "GenSigSendType" SG_ 2156331008 LwRngLVLdShdRq 10;
BA_ "VNSigInfotainment" SG_ 2156331008 LwRngLVLdShdRq 1;
BA_ "SignalType" SG_ 2156331008 LwRngLVLdShdRq "ENM";
BA_ "SignalLongName" SG_ 2156331008 LwRngLVLdShdRq "Low Range Low Voltage Load Shedding Request";
BA_ "VNSigAllNodes" SG_ 2156331008 LwRngLVLdShdRq 1;
BA_ "GenSigDeltaValue" SG_ 2156331008 HVDpltnMdMiCnfdcRg 1;
BA_ "GenSigSendType" SG_ 2156331008 HVDpltnMdMiCnfdcRg 12;
BA_ "GenSigSendOnInit" SG_ 2156331008 HVDpltnMdMiCnfdcRg 1;
BA_ "VNSigInfotainment" SG_ 2156331008 HVDpltnMdMiCnfdcRg 1;
BA_ "SignalType" SG_ 2156331008 HVDpltnMdMiCnfdcRg "UNM";
BA_ "SignalLongName" SG_ 2156331008 HVDpltnMdMiCnfdcRg "High Voltage Depletion Mode Minimum Confidence Range";
BA_ "VNSigAllNodes" SG_ 2156331008 HVDpltnMdMiCnfdcRg 1;
BA_ "GenSigDeltaValue" SG_ 2156331008 HVDpltnMdMxGugRg 1;
BA_ "GenSigSendType" SG_ 2156331008 HVDpltnMdMxGugRg 12;
BA_ "VNSigInfotainment" SG_ 2156331008 HVDpltnMdMxGugRg 1;
BA_ "SignalType" SG_ 2156331008 HVDpltnMdMxGugRg "UNM";
BA_ "SignalLongName" SG_ 2156331008 HVDpltnMdMxGugRg "High Voltage Depletion Mode Maximum Gauge Range";
BA_ "VNSigAllNodes" SG_ 2156331008 HVDpltnMdMxGugRg 1;
BA_ "GenSigDeltaValue" SG_ 2156331008 HVDpltnMdMxCnfdcRg 1;
BA_ "GenSigSendType" SG_ 2156331008 HVDpltnMdMxCnfdcRg 12;
BA_ "GenSigSendOnInit" SG_ 2156331008 HVDpltnMdMxCnfdcRg 1;
BA_ "VNSigInfotainment" SG_ 2156331008 HVDpltnMdMxCnfdcRg 1;
BA_ "SignalType" SG_ 2156331008 HVDpltnMdMxCnfdcRg "UNM";
BA_ "SignalLongName" SG_ 2156331008 HVDpltnMdMxCnfdcRg "High Voltage Depletion Mode Maximum Confidence Range";
BA_ "VNSigAllNodes" SG_ 2156331008 HVDpltnMdMxCnfdcRg 1;
BA_ "GenSigSendType" SG_ 2151776256 RCTALIC_Indctr1Act 10;
BA_ "SignalType" SG_ 2151776256 RCTALIC_Indctr1Act "BLN";
BA_ "PacketOrder" SG_ 2151776256 RCTALIC_Indctr1Act 1;
BA_ "SignalLongName" SG_ 2151776256 RCTALIC_Indctr1Act "Rear Cross Traffic Alert Left Indication Control : Indicator 1 Active";
BA_ "VNSigAllNodes" SG_ 2151776256 RCTALIC_Indctr1Act 1;
BA_ "GenSigSendType" SG_ 2151776256 RCTALIC_IndReq 10;
BA_ "SignalType" SG_ 2151776256 RCTALIC_IndReq "ENM";
BA_ "PacketOrder" SG_ 2151776256 RCTALIC_IndReq 2;
BA_ "SignalLongName" SG_ 2151776256 RCTALIC_IndReq "Rear Cross Traffic Alert Left Indication Control : Indication Request";
BA_ "VNSigAllNodes" SG_ 2151776256 RCTALIC_IndReq 1;
BA_ "GenSigDeltaValue" SG_ 2151776256 RrCTfcLHptcStRqSeqN 1;
BA_ "GenSigSendType" SG_ 2151776256 RrCTfcLHptcStRqSeqN 12;
BA_ "SignalType" SG_ 2151776256 RrCTfcLHptcStRqSeqN "UNM";
BA_ "SignalLongName" SG_ 2151776256 RrCTfcLHptcStRqSeqN "Rear Cross Traffic Alert Left Haptic Seat Request Sequence Number";
BA_ "VNSigAllNodes" SG_ 2151776256 RrCTfcLHptcStRqSeqN 1;
BA_ "GenSigDeltaValue" SG_ 2151776256 RrCTfcLHptcStReq 1;
BA_ "GenSigSendType" SG_ 2151776256 RrCTfcLHptcStReq 12;
BA_ "SignalType" SG_ 2151776256 RrCTfcLHptcStReq "UNM";
BA_ "SignalLongName" SG_ 2151776256 RrCTfcLHptcStReq "Rear Cross Traffic Alert Left Haptic Seat Request";
BA_ "VNSigAllNodes" SG_ 2151776256 RrCTfcLHptcStReq 1;
BA_ "GenSigSendType" SG_ 2150375424 LBCCsStReq 10;
BA_ "VNSigInfotainment" SG_ 2150375424 LBCCsStReq 1;
BA_ "SignalType" SG_ 2150375424 LBCCsStReq "ENM";
BA_ "SignalLongName" SG_ 2150375424 LBCCsStReq "Location Based Charging Customization Setting Request";
BA_ "VNSigAllNodes" SG_ 2150375424 LBCCsStReq 1;
BA_ "GenSigSendType" SG_ 2150375424 LBCPosMdfcReq 10;
BA_ "VNSigInfotainment" SG_ 2150375424 LBCPosMdfcReq 1;
BA_ "SignalType" SG_ 2150375424 LBCPosMdfcReq "ENM";
BA_ "SignalLongName" SG_ 2150375424 LBCPosMdfcReq "Location Based Charging Position Modification Request";
BA_ "VNSigAllNodes" SG_ 2150375424 LBCPosMdfcReq 1;
BA_ "GenSigSendType" SG_ 2150375424 LBCCDRR_ClrStrdPosReq 10;
BA_ "VNSigInfotainment" SG_ 2150375424 LBCCDRR_ClrStrdPosReq 1;
BA_ "SignalType" SG_ 2150375424 LBCCDRR_ClrStrdPosReq "ENM";
BA_ "PacketOrder" SG_ 2150375424 LBCCDRR_ClrStrdPosReq 1;
BA_ "SignalLongName" SG_ 2150375424 LBCCDRR_ClrStrdPosReq "Location Based Charging Customer Data Reset Request : Clear Stored Position Request";
BA_ "VNSigAllNodes" SG_ 2150375424 LBCCDRR_ClrStrdPosReq 1;
BA_ "GenSigSendType" SG_ 2150375424 LBCCDRR_PosNum 10;
BA_ "VNSigInfotainment" SG_ 2150375424 LBCCDRR_PosNum 1;
BA_ "SignalType" SG_ 2150375424 LBCCDRR_PosNum "ENM";
BA_ "PacketOrder" SG_ 2150375424 LBCCDRR_PosNum 2;
BA_ "SignalLongName" SG_ 2150375424 LBCCDRR_PosNum "Location Based Charging Customer Data Reset Request : Position Number";
BA_ "VNSigAllNodes" SG_ 2150375424 LBCCDRR_PosNum 1;
BA_ "GenSigSendType" SG_ 2150375424 USBProgInPrgrs 10;
BA_ "SignalType" SG_ 2150375424 USBProgInPrgrs "BLN";
BA_ "SignalLongName" SG_ 2150375424 USBProgInPrgrs "USB Programming In Progress";
BA_ "VNSigAllNodes" SG_ 2150375424 USBProgInPrgrs 1;
BA_ "GenSigSendType" SG_ 2150375424 EngyCnsHistGrphRstRq 10;
BA_ "VNSigInfotainment" SG_ 2150375424 EngyCnsHistGrphRstRq 1;
BA_ "SignalType" SG_ 2150375424 EngyCnsHistGrphRstRq "BLN";
BA_ "SignalLongName" SG_ 2150375424 EngyCnsHistGrphRstRq "Energy Consumption History Graph Reset Requested";
BA_ "VNSigAllNodes" SG_ 2150375424 EngyCnsHistGrphRstRq 1;
BA_ "GenSigSendType" SG_ 2150375424 DsplTrnsShftLvrLckRqd 10;
BA_ "SignalType" SG_ 2150375424 DsplTrnsShftLvrLckRqd "BLN";
BA_ "SignalLongName" SG_ 2150375424 DsplTrnsShftLvrLckRqd "Displays Transmission Shift Lever Lock Requested";
BA_ "VNSigAllNodes" SG_ 2150375424 DsplTrnsShftLvrLckRqd 1;
BA_ "GenSigSendType" SG_ 2150375424 EngAstHtPlgInCstStRq 10;
BA_ "VNSigInfotainment" SG_ 2150375424 EngAstHtPlgInCstStRq 1;
BA_ "SignalType" SG_ 2150375424 EngAstHtPlgInCstStRq "ENM";
BA_ "SignalLongName" SG_ 2150375424 EngAstHtPlgInCstStRq "Engine Assisted Heating Plugged-In Customization Setting Request";
BA_ "VNSigAllNodes" SG_ 2150375424 EngAstHtPlgInCstStRq 1;
BA_ "GenSigSendType" SG_ 2150375424 EngAstHtCstStRq 10;
BA_ "VNSigInfotainment" SG_ 2150375424 EngAstHtCstStRq 1;
BA_ "SignalType" SG_ 2150375424 EngAstHtCstStRq "ENM";
BA_ "SignalLongName" SG_ 2150375424 EngAstHtCstStRq "Engine Assisted Heating Customization Setting Request";
BA_ "VNSigAllNodes" SG_ 2150375424 EngAstHtCstStRq 1;
BA_ "GenSigSendType" SG_ 2150375424 MntnceMdStEngRq 10;
BA_ "GenSigSendOnInit" SG_ 2150375424 MntnceMdStEngRq 2;
BA_ "VNSigInfotainment" SG_ 2150375424 MntnceMdStEngRq 1;
BA_ "SignalType" SG_ 2150375424 MntnceMdStEngRq "BLN";
BA_ "SignalLongName" SG_ 2150375424 MntnceMdStEngRq "Maintenance Mode Start Engine Request";
BA_ "VNSigAllNodes" SG_ 2150375424 MntnceMdStEngRq 1;
BA_ "GenSigDeltaValue" SG_ 2150383616 EngMntncePrcntCpl 1;
BA_ "GenSigSendType" SG_ 2150383616 EngMntncePrcntCpl 12;
BA_ "SignalType" SG_ 2150383616 EngMntncePrcntCpl "UNM";
BA_ "SignalLongName" SG_ 2150383616 EngMntncePrcntCpl "Engine Maintenance Percent Complete";
BA_ "VNSigAllNodes" SG_ 2150383616 EngMntncePrcntCpl 1;
BA_ "GenSigSendType" SG_ 2150383616 EngMntnceMdAct 10;
BA_ "SignalType" SG_ 2150383616 EngMntnceMdAct "BLN";
BA_ "SignalLongName" SG_ 2150383616 EngMntnceMdAct "Engine Maintenance Mode Active";
BA_ "VNSigAllNodes" SG_ 2150383616 EngMntnceMdAct 1;
BA_ "GenSigDeltaValue" SG_ 2150383616 BatPrpDspPwrLvlPct 1;
BA_ "GenSigSendType" SG_ 2150383616 BatPrpDspPwrLvlPct 12;
BA_ "SignalType" SG_ 2150383616 BatPrpDspPwrLvlPct "SNM";
BA_ "SignalLongName" SG_ 2150383616 BatPrpDspPwrLvlPct "Battery Propulsion Display Power Level Percent";
BA_ "VNSigAllNodes" SG_ 2150383616 BatPrpDspPwrLvlPct 1;
BA_ "GenSigDeltaValue" SG_ 2150383616 PrpDspTtlPwr 1;
BA_ "GenSigSendType" SG_ 2150383616 PrpDspTtlPwr 12;
BA_ "VNSigInfotainment" SG_ 2150383616 PrpDspTtlPwr 1;
BA_ "SignalType" SG_ 2150383616 PrpDspTtlPwr "UNM";
BA_ "SignalLongName" SG_ 2150383616 PrpDspTtlPwr "Propulsion Display Total Power";
BA_ "VNSigAllNodes" SG_ 2150383616 PrpDspTtlPwr 1;
BA_ "GenSigDeltaValue" SG_ 2150383616 PrpCapDspOpPs 1;
BA_ "GenSigSendType" SG_ 2150383616 PrpCapDspOpPs 12;
BA_ "VNSigInfotainment" SG_ 2150383616 PrpCapDspOpPs 1;
BA_ "SignalType" SG_ 2150383616 PrpCapDspOpPs "UNM";
BA_ "SignalLongName" SG_ 2150383616 PrpCapDspOpPs "Propulsion Capability Display Operating Position";
BA_ "VNSigAllNodes" SG_ 2150383616 PrpCapDspOpPs 1;
BA_ "GenSigDeltaValue" SG_ 2150383616 EstElecPrpCap 1;
BA_ "GenSigSendType" SG_ 2150383616 EstElecPrpCap 12;
BA_ "SignalType" SG_ 2150383616 EstElecPrpCap "UNM";
BA_ "SignalLongName" SG_ 2150383616 EstElecPrpCap "Estimated Electrical Propulsion Capability";
BA_ "VNSigAllNodes" SG_ 2150383616 EstElecPrpCap 1;
BA_ "GenSigDeltaValue" SG_ 2150383616 EngPrpDspPwrLvlPct 1;
BA_ "GenSigSendType" SG_ 2150383616 EngPrpDspPwrLvlPct 12;
BA_ "VNSigInfotainment" SG_ 2150383616 EngPrpDspPwrLvlPct 1;
BA_ "SignalType" SG_ 2150383616 EngPrpDspPwrLvlPct "UNM";
BA_ "SignalLongName" SG_ 2150383616 EngPrpDspPwrLvlPct "Engine Propulsion Display Power Level Percent";
BA_ "VNSigAllNodes" SG_ 2150383616 EngPrpDspPwrLvlPct 1;
BA_ "GenSigSendType" SG_ 2150383616 MntnceMdDsplyRq 10;
BA_ "GenSigSendOnInit" SG_ 2150383616 MntnceMdDsplyRq 1;
BA_ "VNSigInfotainment" SG_ 2150383616 MntnceMdDsplyRq 1;
BA_ "SignalType" SG_ 2150383616 MntnceMdDsplyRq "ENM";
BA_ "SignalLongName" SG_ 2150383616 MntnceMdDsplyRq "Maintenance Mode Display Request";
BA_ "VNSigAllNodes" SG_ 2150383616 MntnceMdDsplyRq 1;
BA_ "GenSigDeltaValue" SG_ 2151981056 DrvCyclBatPropRat 1;
BA_ "GenSigSendType" SG_ 2151981056 DrvCyclBatPropRat 12;
BA_ "GenSigSendOnInit" SG_ 2151981056 DrvCyclBatPropRat 1;
BA_ "VNSigInfotainment" SG_ 2151981056 DrvCyclBatPropRat 1;
BA_ "SignalType" SG_ 2151981056 DrvCyclBatPropRat "UNM";
BA_ "SignalLongName" SG_ 2151981056 DrvCyclBatPropRat "Drive Cycle Battery Propulsion Ratio";
BA_ "VNSigAllNodes" SG_ 2151981056 DrvCyclBatPropRat 1;
BA_ "GenSigDeltaValue" SG_ 2151981056 DTD_FuelPrpDstTrvld 1;
BA_ "GenSigSendType" SG_ 2151981056 DTD_FuelPrpDstTrvld 12;
BA_ "GenSigSendOnInit" SG_ 2151981056 DTD_FuelPrpDstTrvld 1;
BA_ "VNSigInfotainment" SG_ 2151981056 DTD_FuelPrpDstTrvld 1;
BA_ "SignalType" SG_ 2151981056 DTD_FuelPrpDstTrvld "UNM";
BA_ "PacketOrder" SG_ 2151981056 DTD_FuelPrpDstTrvld 2;
BA_ "SignalLongName" SG_ 2151981056 DTD_FuelPrpDstTrvld "Distance Traveled Data : Fuel Propulsion Distance Traveled";
BA_ "VNSigAllNodes" SG_ 2151981056 DTD_FuelPrpDstTrvld 1;
BA_ "GenSigDeltaValue" SG_ 2151981056 DTD_DrvCyclDstTrvld 1;
BA_ "GenSigSendType" SG_ 2151981056 DTD_DrvCyclDstTrvld 12;
BA_ "GenSigSendOnInit" SG_ 2151981056 DTD_DrvCyclDstTrvld 1;
BA_ "VNSigInfotainment" SG_ 2151981056 DTD_DrvCyclDstTrvld 1;
BA_ "SignalType" SG_ 2151981056 DTD_DrvCyclDstTrvld "UNM";
BA_ "PacketOrder" SG_ 2151981056 DTD_DrvCyclDstTrvld 3;
BA_ "SignalLongName" SG_ 2151981056 DTD_DrvCyclDstTrvld "Distance Traveled Data : Drive Cycle Distance Traveled";
BA_ "VNSigAllNodes" SG_ 2151981056 DTD_DrvCyclDstTrvld 1;
BA_ "GenSigDeltaValue" SG_ 2151981056 DTD_BattPrpDstTrvld 1;
BA_ "GenSigSendType" SG_ 2151981056 DTD_BattPrpDstTrvld 12;
BA_ "GenSigSendOnInit" SG_ 2151981056 DTD_BattPrpDstTrvld 1;
BA_ "VNSigInfotainment" SG_ 2151981056 DTD_BattPrpDstTrvld 1;
BA_ "SignalType" SG_ 2151981056 DTD_BattPrpDstTrvld "UNM";
BA_ "PacketOrder" SG_ 2151981056 DTD_BattPrpDstTrvld 1;
BA_ "SignalLongName" SG_ 2151981056 DTD_BattPrpDstTrvld "Distance Traveled Data : Battery Propulsion Distance Traveled";
BA_ "VNSigAllNodes" SG_ 2151981056 DTD_BattPrpDstTrvld 1;
BA_ "GenSigDeltaValue" SG_ 2151964672 DrvCyclTtlEnrgEfncy 1;
BA_ "GenSigSendType" SG_ 2151964672 DrvCyclTtlEnrgEfncy 12;
BA_ "GenSigSendOnInit" SG_ 2151964672 DrvCyclTtlEnrgEfncy 1;
BA_ "VNSigInfotainment" SG_ 2151964672 DrvCyclTtlEnrgEfncy 1;
BA_ "SignalType" SG_ 2151964672 DrvCyclTtlEnrgEfncy "UNM";
BA_ "SignalLongName" SG_ 2151964672 DrvCyclTtlEnrgEfncy "Drive Cycle Total Energy Efficiency";
BA_ "VNSigAllNodes" SG_ 2151964672 DrvCyclTtlEnrgEfncy 1;
BA_ "GenSigDeltaValue" SG_ 2151964672 DrvCyclFuelUsd 1;
BA_ "GenSigSendType" SG_ 2151964672 DrvCyclFuelUsd 12;
BA_ "GenSigSendOnInit" SG_ 2151964672 DrvCyclFuelUsd 1;
BA_ "VNSigInfotainment" SG_ 2151964672 DrvCyclFuelUsd 1;
BA_ "SignalType" SG_ 2151964672 DrvCyclFuelUsd "UNM";
BA_ "SignalLongName" SG_ 2151964672 DrvCyclFuelUsd "Drive Cycle Fuel Used";
BA_ "VNSigAllNodes" SG_ 2151964672 DrvCyclFuelUsd 1;
BA_ "GenSigDeltaValue" SG_ 2151964672 DrvCyclFuelEnmy 1;
BA_ "GenSigSendType" SG_ 2151964672 DrvCyclFuelEnmy 12;
BA_ "GenSigSendOnInit" SG_ 2151964672 DrvCyclFuelEnmy 1;
BA_ "VNSigInfotainment" SG_ 2151964672 DrvCyclFuelEnmy 1;
BA_ "SignalType" SG_ 2151964672 DrvCyclFuelEnmy "UNM";
BA_ "SignalLongName" SG_ 2151964672 DrvCyclFuelEnmy "Drive Cycle Fuel Economy";
BA_ "VNSigAllNodes" SG_ 2151964672 DrvCyclFuelEnmy 1;
BA_ "GenSigDeltaValue" SG_ 2151964672 DrvCyclDrvStEnrgEfncy 1;
BA_ "GenSigSendType" SG_ 2151964672 DrvCyclDrvStEnrgEfncy 12;
BA_ "GenSigSendOnInit" SG_ 2151964672 DrvCyclDrvStEnrgEfncy 1;
BA_ "VNSigInfotainment" SG_ 2151964672 DrvCyclDrvStEnrgEfncy 1;
BA_ "SignalType" SG_ 2151964672 DrvCyclDrvStEnrgEfncy "UNM";
BA_ "SignalLongName" SG_ 2151964672 DrvCyclDrvStEnrgEfncy "Drive Cycle Driving Style Energy Efficiency";
BA_ "VNSigAllNodes" SG_ 2151964672 DrvCyclDrvStEnrgEfncy 1;
BA_ "GenSigDeltaValue" SG_ 2151964672 DrvCyclCbnCondEnrgEfncy 1;
BA_ "GenSigSendType" SG_ 2151964672 DrvCyclCbnCondEnrgEfncy 12;
BA_ "GenSigSendOnInit" SG_ 2151964672 DrvCyclCbnCondEnrgEfncy 1;
BA_ "VNSigInfotainment" SG_ 2151964672 DrvCyclCbnCondEnrgEfncy 1;
BA_ "SignalType" SG_ 2151964672 DrvCyclCbnCondEnrgEfncy "UNM";
BA_ "SignalLongName" SG_ 2151964672 DrvCyclCbnCondEnrgEfncy "Drive Cycle Cabin Conditioning Energy Efficiency";
BA_ "VNSigAllNodes" SG_ 2151964672 DrvCyclCbnCondEnrgEfncy 1;
BA_ "GenSigDeltaValue" SG_ 2151964672 DrvCyclBatCondEnrgEfncy 1;
BA_ "GenSigSendType" SG_ 2151964672 DrvCyclBatCondEnrgEfncy 12;
BA_ "GenSigSendOnInit" SG_ 2151964672 DrvCyclBatCondEnrgEfncy 1;
BA_ "VNSigInfotainment" SG_ 2151964672 DrvCyclBatCondEnrgEfncy 1;
BA_ "SignalType" SG_ 2151964672 DrvCyclBatCondEnrgEfncy "UNM";
BA_ "SignalLongName" SG_ 2151964672 DrvCyclBatCondEnrgEfncy "Drive Cycle Battery Conditioning Energy Efficiency";
BA_ "VNSigAllNodes" SG_ 2151964672 DrvCyclBatCondEnrgEfncy 1;
BA_ "GenSigSendType" SG_ 2156298240 HTRActvIndOn 10;
BA_ "GenSigSendOnInit" SG_ 2156298240 HTRActvIndOn 1;
BA_ "VNSigInfotainment" SG_ 2156298240 HTRActvIndOn 1;
BA_ "SignalType" SG_ 2156298240 HTRActvIndOn "BLN";
BA_ "SignalLongName" SG_ 2156298240 HTRActvIndOn "Hill Top Reserve Active Indication On";
BA_ "VNSigAllNodes" SG_ 2156298240 HTRActvIndOn 1;
BA_ "GenSigDeltaValue" SG_ 2156298240 HVBSTLPC_MntOfHr 1;
BA_ "GenSigSendType" SG_ 2156298240 HVBSTLPC_MntOfHr 12;
BA_ "GenSigSendOnInit" SG_ 2156298240 HVBSTLPC_MntOfHr 1;
BA_ "VNSigInfotainment" SG_ 2156298240 HVBSTLPC_MntOfHr 1;
BA_ "SignalType" SG_ 2156298240 HVBSTLPC_MntOfHr "UNM";
BA_ "PacketOrder" SG_ 2156298240 HVBSTLPC_MntOfHr 3;
BA_ "SignalLongName" SG_ 2156298240 HVBSTLPC_MntOfHr "High Voltage Battery Start Time Low Power Charge : Minute of Hour";
BA_ "VNSigAllNodes" SG_ 2156298240 HVBSTLPC_MntOfHr 1;
BA_ "GenSigDeltaValue" SG_ 2156298240 HVBSTLPC_HrOfDy 1;
BA_ "GenSigSendType" SG_ 2156298240 HVBSTLPC_HrOfDy 12;
BA_ "GenSigSendOnInit" SG_ 2156298240 HVBSTLPC_HrOfDy 1;
BA_ "VNSigInfotainment" SG_ 2156298240 HVBSTLPC_HrOfDy 1;
BA_ "SignalType" SG_ 2156298240 HVBSTLPC_HrOfDy "UNM";
BA_ "PacketOrder" SG_ 2156298240 HVBSTLPC_HrOfDy 2;
BA_ "SignalLongName" SG_ 2156298240 HVBSTLPC_HrOfDy "High Voltage Battery Start Time Low Power Charge : Hour of Day";
BA_ "VNSigAllNodes" SG_ 2156298240 HVBSTLPC_HrOfDy 1;
BA_ "GenSigSendType" SG_ 2156298240 HVBSTLPC_DyOfWk 10;
BA_ "GenSigSendOnInit" SG_ 2156298240 HVBSTLPC_DyOfWk 1;
BA_ "VNSigInfotainment" SG_ 2156298240 HVBSTLPC_DyOfWk 1;
BA_ "SignalType" SG_ 2156298240 HVBSTLPC_DyOfWk "ENM";
BA_ "PacketOrder" SG_ 2156298240 HVBSTLPC_DyOfWk 1;
BA_ "SignalLongName" SG_ 2156298240 HVBSTLPC_DyOfWk "High Voltage Battery Start Time Low Power Charge : Day of Week";
BA_ "VNSigAllNodes" SG_ 2156298240 HVBSTLPC_DyOfWk 1;
BA_ "GenSigDeltaValue" SG_ 2156298240 HVBSTHPC_MntOfHr 1;
BA_ "GenSigSendType" SG_ 2156298240 HVBSTHPC_MntOfHr 12;
BA_ "GenSigSendOnInit" SG_ 2156298240 HVBSTHPC_MntOfHr 1;
BA_ "VNSigInfotainment" SG_ 2156298240 HVBSTHPC_MntOfHr 1;
BA_ "SignalType" SG_ 2156298240 HVBSTHPC_MntOfHr "UNM";
BA_ "PacketOrder" SG_ 2156298240 HVBSTHPC_MntOfHr 3;
BA_ "SignalLongName" SG_ 2156298240 HVBSTHPC_MntOfHr "High Voltage Battery Start Time High Power Charge : Minute of Hour";
BA_ "VNSigAllNodes" SG_ 2156298240 HVBSTHPC_MntOfHr 1;
BA_ "GenSigDeltaValue" SG_ 2156298240 HVBSTHPC_HrOfDy 1;
BA_ "GenSigSendType" SG_ 2156298240 HVBSTHPC_HrOfDy 12;
BA_ "GenSigSendOnInit" SG_ 2156298240 HVBSTHPC_HrOfDy 1;
BA_ "VNSigInfotainment" SG_ 2156298240 HVBSTHPC_HrOfDy 1;
BA_ "SignalType" SG_ 2156298240 HVBSTHPC_HrOfDy "UNM";
BA_ "PacketOrder" SG_ 2156298240 HVBSTHPC_HrOfDy 2;
BA_ "SignalLongName" SG_ 2156298240 HVBSTHPC_HrOfDy "High Voltage Battery Start Time High Power Charge : Hour of Day";
BA_ "VNSigAllNodes" SG_ 2156298240 HVBSTHPC_HrOfDy 1;
BA_ "GenSigSendType" SG_ 2156298240 HVBSTHPC_DyOfWk 10;
BA_ "GenSigSendOnInit" SG_ 2156298240 HVBSTHPC_DyOfWk 1;
BA_ "VNSigInfotainment" SG_ 2156298240 HVBSTHPC_DyOfWk 1;
BA_ "SignalType" SG_ 2156298240 HVBSTHPC_DyOfWk "ENM";
BA_ "PacketOrder" SG_ 2156298240 HVBSTHPC_DyOfWk 1;
BA_ "SignalLongName" SG_ 2156298240 HVBSTHPC_DyOfWk "High Voltage Battery Start Time High Power Charge : Day of Week";
BA_ "VNSigAllNodes" SG_ 2156298240 HVBSTHPC_DyOfWk 1;
BA_ "GenSigDeltaValue" SG_ 2156298240 HVBCTLPC_MntOfHr 1;
BA_ "GenSigSendType" SG_ 2156298240 HVBCTLPC_MntOfHr 12;
BA_ "GenSigSendOnInit" SG_ 2156298240 HVBCTLPC_MntOfHr 1;
BA_ "VNSigInfotainment" SG_ 2156298240 HVBCTLPC_MntOfHr 1;
BA_ "SignalType" SG_ 2156298240 HVBCTLPC_MntOfHr "UNM";
BA_ "PacketOrder" SG_ 2156298240 HVBCTLPC_MntOfHr 3;
BA_ "SignalLongName" SG_ 2156298240 HVBCTLPC_MntOfHr "High Voltage Battery Complete Time Low Power Charge : Minute of Hour";
BA_ "VNSigAllNodes" SG_ 2156298240 HVBCTLPC_MntOfHr 1;
BA_ "GenSigDeltaValue" SG_ 2156298240 HVBCTLPC_HrOfDy 1;
BA_ "GenSigSendType" SG_ 2156298240 HVBCTLPC_HrOfDy 12;
BA_ "GenSigSendOnInit" SG_ 2156298240 HVBCTLPC_HrOfDy 1;
BA_ "VNSigInfotainment" SG_ 2156298240 HVBCTLPC_HrOfDy 1;
BA_ "SignalType" SG_ 2156298240 HVBCTLPC_HrOfDy "UNM";
BA_ "PacketOrder" SG_ 2156298240 HVBCTLPC_HrOfDy 2;
BA_ "SignalLongName" SG_ 2156298240 HVBCTLPC_HrOfDy "High Voltage Battery Complete Time Low Power Charge : Hour of Day";
BA_ "VNSigAllNodes" SG_ 2156298240 HVBCTLPC_HrOfDy 1;
BA_ "GenSigSendType" SG_ 2156298240 HVBCTLPC_DyOfWk 10;
BA_ "GenSigSendOnInit" SG_ 2156298240 HVBCTLPC_DyOfWk 1;
BA_ "VNSigInfotainment" SG_ 2156298240 HVBCTLPC_DyOfWk 1;
BA_ "SignalType" SG_ 2156298240 HVBCTLPC_DyOfWk "ENM";
BA_ "PacketOrder" SG_ 2156298240 HVBCTLPC_DyOfWk 1;
BA_ "SignalLongName" SG_ 2156298240 HVBCTLPC_DyOfWk "High Voltage Battery Complete Time Low Power Charge : Day of Week";
BA_ "VNSigAllNodes" SG_ 2156298240 HVBCTLPC_DyOfWk 1;
BA_ "GenSigDeltaValue" SG_ 2156298240 HVBCTHPC_MntOfHr 1;
BA_ "GenSigSendType" SG_ 2156298240 HVBCTHPC_MntOfHr 12;
BA_ "GenSigSendOnInit" SG_ 2156298240 HVBCTHPC_MntOfHr 1;
BA_ "VNSigInfotainment" SG_ 2156298240 HVBCTHPC_MntOfHr 1;
BA_ "SignalType" SG_ 2156298240 HVBCTHPC_MntOfHr "UNM";
BA_ "PacketOrder" SG_ 2156298240 HVBCTHPC_MntOfHr 3;
BA_ "SignalLongName" SG_ 2156298240 HVBCTHPC_MntOfHr "High Voltage Battery Complete Time High Power Charge : Minute of Hour";
BA_ "VNSigAllNodes" SG_ 2156298240 HVBCTHPC_MntOfHr 1;
BA_ "GenSigDeltaValue" SG_ 2156298240 HVBCTHPC_HrOfDy 1;
BA_ "GenSigSendType" SG_ 2156298240 HVBCTHPC_HrOfDy 12;
BA_ "GenSigSendOnInit" SG_ 2156298240 HVBCTHPC_HrOfDy 1;
BA_ "VNSigInfotainment" SG_ 2156298240 HVBCTHPC_HrOfDy 1;
BA_ "SignalType" SG_ 2156298240 HVBCTHPC_HrOfDy "UNM";
BA_ "PacketOrder" SG_ 2156298240 HVBCTHPC_HrOfDy 2;
BA_ "SignalLongName" SG_ 2156298240 HVBCTHPC_HrOfDy "High Voltage Battery Complete Time High Power Charge : Hour of Day";
BA_ "VNSigAllNodes" SG_ 2156298240 HVBCTHPC_HrOfDy 1;
BA_ "GenSigSendType" SG_ 2156298240 HVBCTHPC_DyOfWk 10;
BA_ "GenSigSendOnInit" SG_ 2156298240 HVBCTHPC_DyOfWk 1;
BA_ "VNSigInfotainment" SG_ 2156298240 HVBCTHPC_DyOfWk 1;
BA_ "SignalType" SG_ 2156298240 HVBCTHPC_DyOfWk "ENM";
BA_ "PacketOrder" SG_ 2156298240 HVBCTHPC_DyOfWk 1;
BA_ "SignalLongName" SG_ 2156298240 HVBCTHPC_DyOfWk "High Voltage Battery Complete Time High Power Charge : Day of Week";
BA_ "VNSigAllNodes" SG_ 2156298240 HVBCTHPC_DyOfWk 1;
BA_ "GenSigSendType" SG_ 2156298240 InvldHMIEtrIO 10;
BA_ "VNSigInfotainment" SG_ 2156298240 InvldHMIEtrIO 1;
BA_ "SignalType" SG_ 2156298240 InvldHMIEtrIO "BLN";
BA_ "SignalLongName" SG_ 2156298240 InvldHMIEtrIO "Invalid HMI Entry Indication On";
BA_ "VNSigAllNodes" SG_ 2156298240 InvldHMIEtrIO 1;
BA_ "GenSigSendType" SG_ 2156298240 InsfcntTmTFlChrgIO 10;
BA_ "VNSigInfotainment" SG_ 2156298240 InsfcntTmTFlChrgIO 1;
BA_ "SignalType" SG_ 2156298240 InsfcntTmTFlChrgIO "BLN";
BA_ "SignalLongName" SG_ 2156298240 InsfcntTmTFlChrgIO "Insufficient Time to Fully Charge Indication On";
BA_ "VNSigAllNodes" SG_ 2156298240 InsfcntTmTFlChrgIO 1;
BA_ "GenSigSendType" SG_ 2156298240 HVBatChrgCrdAlrtReq 10;
BA_ "VNSigInfotainment" SG_ 2156298240 HVBatChrgCrdAlrtReq 1;
BA_ "SignalType" SG_ 2156298240 HVBatChrgCrdAlrtReq "ENM";
BA_ "SignalLongName" SG_ 2156298240 HVBatChrgCrdAlrtReq "High Voltage Battery Charge Cord Alert Request";
BA_ "VNSigAllNodes" SG_ 2156298240 HVBatChrgCrdAlrtReq 1;
BA_ "GenSigSendType" SG_ 2156298240 HVCSDTES_NPDTIO 10;
BA_ "GenSigSendOnInit" SG_ 2156298240 HVCSDTES_NPDTIO 1;
BA_ "VNSigInfotainment" SG_ 2156298240 HVCSDTES_NPDTIO 1;
BA_ "SignalType" SG_ 2156298240 HVCSDTES_NPDTIO "BLN";
BA_ "PacketOrder" SG_ 2156298240 HVCSDTES_NPDTIO 3;
BA_ "SignalLongName" SG_ 2156298240 HVCSDTES_NPDTIO "High Voltage Charging System Departure Time Exceeded Status : Next Planned Departure Time Indication On";
BA_ "VNSigAllNodes" SG_ 2156298240 HVCSDTES_NPDTIO 1;
BA_ "GenSigSendType" SG_ 2156298240 HVCSDTES_LoPwrCIO 10;
BA_ "GenSigSendOnInit" SG_ 2156298240 HVCSDTES_LoPwrCIO 1;
BA_ "VNSigInfotainment" SG_ 2156298240 HVCSDTES_LoPwrCIO 1;
BA_ "SignalType" SG_ 2156298240 HVCSDTES_LoPwrCIO "BLN";
BA_ "PacketOrder" SG_ 2156298240 HVCSDTES_LoPwrCIO 1;
BA_ "SignalLongName" SG_ 2156298240 HVCSDTES_LoPwrCIO "High Voltage Charging System Departure Time Exceeded Status : Low Power Charge Complete Time Indication On";
BA_ "VNSigAllNodes" SG_ 2156298240 HVCSDTES_LoPwrCIO 1;
BA_ "GenSigSendType" SG_ 2156298240 HVCSDTES_HiPwrCIO 10;
BA_ "GenSigSendOnInit" SG_ 2156298240 HVCSDTES_HiPwrCIO 1;
BA_ "VNSigInfotainment" SG_ 2156298240 HVCSDTES_HiPwrCIO 1;
BA_ "SignalType" SG_ 2156298240 HVCSDTES_HiPwrCIO "BLN";
BA_ "PacketOrder" SG_ 2156298240 HVCSDTES_HiPwrCIO 2;
BA_ "SignalLongName" SG_ 2156298240 HVCSDTES_HiPwrCIO "High Voltage Charging System Departure Time Exceeded Status : High Power Charge Complete Time Indication On";
BA_ "VNSigAllNodes" SG_ 2156298240 HVCSDTES_HiPwrCIO 1;
BA_ "GenSigSendType" SG_ 2149924864 a_12VBatSysUnstab 10;
BA_ "SignalType" SG_ 2149924864 a_12VBatSysUnstab "BLN";
BA_ "SignalLongName" SG_ 2149924864 a_12VBatSysUnstab "12 Volt Battery System Unstable";
BA_ "VNSigAllNodes" SG_ 2149924864 a_12VBatSysUnstab 1;
BA_ "GenSigSendType" SG_ 2149924864 FwdClnMtgnBrkReqAct 10;
BA_ "SignalType" SG_ 2149924864 FwdClnMtgnBrkReqAct "BLN";
BA_ "SignalLongName" SG_ 2149924864 FwdClnMtgnBrkReqAct "Forward Collision Mitigation Braking Request Active";
BA_ "VNSigAllNodes" SG_ 2149924864 FwdClnMtgnBrkReqAct 1;
BA_ "GenSigSendType" SG_ 2149924864 TireRRLowTracIO 10;
BA_ "SignalType" SG_ 2149924864 TireRRLowTracIO "BLN";
BA_ "SignalLongName" SG_ 2149924864 TireRRLowTracIO "Tire Right Rear Low Traction Indication On";
BA_ "VNSigAllNodes" SG_ 2149924864 TireRRLowTracIO 1;
BA_ "GenSigSendType" SG_ 2149924864 TireRFLowTracIO 10;
BA_ "SignalType" SG_ 2149924864 TireRFLowTracIO "BLN";
BA_ "SignalLongName" SG_ 2149924864 TireRFLowTracIO "Tire Right Front Low Traction Indication On";
BA_ "VNSigAllNodes" SG_ 2149924864 TireRFLowTracIO 1;
BA_ "GenSigSendType" SG_ 2149924864 TireLRLowTracIO 10;
BA_ "SignalType" SG_ 2149924864 TireLRLowTracIO "BLN";
BA_ "SignalLongName" SG_ 2149924864 TireLRLowTracIO "Tire Left Rear Low Traction Indication On";
BA_ "VNSigAllNodes" SG_ 2149924864 TireLRLowTracIO 1;
BA_ "GenSigSendType" SG_ 2149924864 TireLFLowTracIO 10;
BA_ "SignalType" SG_ 2149924864 TireLFLowTracIO "BLN";
BA_ "SignalLongName" SG_ 2149924864 TireLFLowTracIO "Tire Left Front Low Traction Indication On";
BA_ "VNSigAllNodes" SG_ 2149924864 TireLFLowTracIO 1;
BA_ "GenSigSendType" SG_ 2149924864 HilRlbkCtrlActIO 10;
BA_ "SignalType" SG_ 2149924864 HilRlbkCtrlActIO "BLN";
BA_ "SignalLongName" SG_ 2149924864 HilRlbkCtrlActIO "Hill Rollback Control Active Indiction On";
BA_ "VNSigAllNodes" SG_ 2149924864 HilRlbkCtrlActIO 1;
BA_ "GenSigSendType" SG_ 2149924864 FstIdlMdAct 10;
BA_ "SignalType" SG_ 2149924864 FstIdlMdAct "BLN";
BA_ "SignalLongName" SG_ 2149924864 FstIdlMdAct "Fast Idle Mode Active";
BA_ "VNSigAllNodes" SG_ 2149924864 FstIdlMdAct 1;
BA_ "GenSigSendType" SG_ 2149924864 DrvSelMd8Stat 10;
BA_ "SignalType" SG_ 2149924864 DrvSelMd8Stat "ENM";
BA_ "SignalLongName" SG_ 2149924864 DrvSelMd8Stat "Driver Selected Mode 8 Status";
BA_ "VNSigAllNodes" SG_ 2149924864 DrvSelMd8Stat 1;
BA_ "GenSigSendType" SG_ 2149924864 DrvSelMd8ReqDnd 10;
BA_ "SignalType" SG_ 2149924864 DrvSelMd8ReqDnd "BLN";
BA_ "SignalLongName" SG_ 2149924864 DrvSelMd8ReqDnd "Driver Selected Mode 8 Request Denied";
BA_ "VNSigAllNodes" SG_ 2149924864 DrvSelMd8ReqDnd 1;
BA_ "GenSigSendType" SG_ 2149924864 DrvSelMd7Stat 10;
BA_ "SignalType" SG_ 2149924864 DrvSelMd7Stat "ENM";
BA_ "SignalLongName" SG_ 2149924864 DrvSelMd7Stat "Driver Selected Mode 7 Status";
BA_ "VNSigAllNodes" SG_ 2149924864 DrvSelMd7Stat 1;
BA_ "GenSigSendType" SG_ 2149924864 DrvSelMd7ReqDnd 10;
BA_ "SignalType" SG_ 2149924864 DrvSelMd7ReqDnd "BLN";
BA_ "SignalLongName" SG_ 2149924864 DrvSelMd7ReqDnd "Driver Selected Mode 7 Request Denied";
BA_ "VNSigAllNodes" SG_ 2149924864 DrvSelMd7ReqDnd 1;
BA_ "GenSigSendType" SG_ 2149924864 DrvSelMd6Stat 10;
BA_ "SignalType" SG_ 2149924864 DrvSelMd6Stat "ENM";
BA_ "SignalLongName" SG_ 2149924864 DrvSelMd6Stat "Driver Selected Mode 6 Status";
BA_ "VNSigAllNodes" SG_ 2149924864 DrvSelMd6Stat 1;
BA_ "GenSigSendType" SG_ 2149924864 DrvSelMd6ReqDnd 10;
BA_ "SignalType" SG_ 2149924864 DrvSelMd6ReqDnd "BLN";
BA_ "SignalLongName" SG_ 2149924864 DrvSelMd6ReqDnd "Driver Selected Mode 6 Request Denied";
BA_ "VNSigAllNodes" SG_ 2149924864 DrvSelMd6ReqDnd 1;
BA_ "GenSigSendType" SG_ 2149924864 DrvSelMd5Stat 10;
BA_ "SignalType" SG_ 2149924864 DrvSelMd5Stat "ENM";
BA_ "SignalLongName" SG_ 2149924864 DrvSelMd5Stat "Driver Selected Mode 5 Status";
BA_ "VNSigAllNodes" SG_ 2149924864 DrvSelMd5Stat 1;
BA_ "GenSigSendType" SG_ 2149924864 DrvSelMd5ReqDnd 10;
BA_ "SignalType" SG_ 2149924864 DrvSelMd5ReqDnd "BLN";
BA_ "SignalLongName" SG_ 2149924864 DrvSelMd5ReqDnd "Driver Selected Mode 5 Request Denied";
BA_ "VNSigAllNodes" SG_ 2149924864 DrvSelMd5ReqDnd 1;
BA_ "GenSigSendType" SG_ 2149924864 DrvSelMd4Stat 10;
BA_ "SignalType" SG_ 2149924864 DrvSelMd4Stat "ENM";
BA_ "SignalLongName" SG_ 2149924864 DrvSelMd4Stat "Driver Selected Mode 4 Status";
BA_ "VNSigAllNodes" SG_ 2149924864 DrvSelMd4Stat 1;
BA_ "GenSigSendType" SG_ 2149924864 DrvSelMd4ReqDnd 10;
BA_ "SignalType" SG_ 2149924864 DrvSelMd4ReqDnd "BLN";
BA_ "SignalLongName" SG_ 2149924864 DrvSelMd4ReqDnd "Driver Selected Mode 4 Request Denied";
BA_ "VNSigAllNodes" SG_ 2149924864 DrvSelMd4ReqDnd 1;
BA_ "GenSigSendType" SG_ 2149924864 DSMSS_DrvSelMd0Pn 10;
BA_ "GenSigSendOnInit" SG_ 2149924864 DSMSS_DrvSelMd0Pn 1;
BA_ "SignalType" SG_ 2149924864 DSMSS_DrvSelMd0Pn "BLN";
BA_ "PacketOrder" SG_ 2149924864 DSMSS_DrvSelMd0Pn 17;
BA_ "SignalLongName" SG_ 2149924864 DSMSS_DrvSelMd0Pn "Driver Selected Mode Selection Status : Driver Selected Mode 0 Pending";
BA_ "VNSigAllNodes" SG_ 2149924864 DSMSS_DrvSelMd0Pn 1;
BA_ "GenSigSendType" SG_ 2149924864 DSMSS_DrvSelMd8Pn 10;
BA_ "GenSigSendOnInit" SG_ 2149924864 DSMSS_DrvSelMd8Pn 1;
BA_ "SignalType" SG_ 2149924864 DSMSS_DrvSelMd8Pn "BLN";
BA_ "PacketOrder" SG_ 2149924864 DSMSS_DrvSelMd8Pn 16;
BA_ "SignalLongName" SG_ 2149924864 DSMSS_DrvSelMd8Pn "Driver Selected Mode Selection Status : Driver Selected Mode 8 Pending";
BA_ "VNSigAllNodes" SG_ 2149924864 DSMSS_DrvSelMd8Pn 1;
BA_ "GenSigSendType" SG_ 2149924864 DSMSS_DrvSelMd7Pn 10;
BA_ "GenSigSendOnInit" SG_ 2149924864 DSMSS_DrvSelMd7Pn 1;
BA_ "SignalType" SG_ 2149924864 DSMSS_DrvSelMd7Pn "BLN";
BA_ "PacketOrder" SG_ 2149924864 DSMSS_DrvSelMd7Pn 15;
BA_ "SignalLongName" SG_ 2149924864 DSMSS_DrvSelMd7Pn "Driver Selected Mode Selection Status : Driver Selected Mode 7 Pending";
BA_ "VNSigAllNodes" SG_ 2149924864 DSMSS_DrvSelMd7Pn 1;
BA_ "GenSigSendType" SG_ 2149924864 DSMSS_DrvSelMd6Pn 10;
BA_ "GenSigSendOnInit" SG_ 2149924864 DSMSS_DrvSelMd6Pn 1;
BA_ "SignalType" SG_ 2149924864 DSMSS_DrvSelMd6Pn "BLN";
BA_ "PacketOrder" SG_ 2149924864 DSMSS_DrvSelMd6Pn 14;
BA_ "SignalLongName" SG_ 2149924864 DSMSS_DrvSelMd6Pn "Driver Selected Mode Selection Status : Driver Selected Mode 6 Pending";
BA_ "VNSigAllNodes" SG_ 2149924864 DSMSS_DrvSelMd6Pn 1;
BA_ "GenSigSendType" SG_ 2149924864 DSMSS_DrvSelMd5Pn 10;
BA_ "GenSigSendOnInit" SG_ 2149924864 DSMSS_DrvSelMd5Pn 1;
BA_ "SignalType" SG_ 2149924864 DSMSS_DrvSelMd5Pn "BLN";
BA_ "PacketOrder" SG_ 2149924864 DSMSS_DrvSelMd5Pn 13;
BA_ "SignalLongName" SG_ 2149924864 DSMSS_DrvSelMd5Pn "Driver Selected Mode Selection Status : Driver Selected Mode 5 Pending";
BA_ "VNSigAllNodes" SG_ 2149924864 DSMSS_DrvSelMd5Pn 1;
BA_ "GenSigSendType" SG_ 2149924864 DSMSS_DrvSelMd4Pn 10;
BA_ "GenSigSendOnInit" SG_ 2149924864 DSMSS_DrvSelMd4Pn 1;
BA_ "SignalType" SG_ 2149924864 DSMSS_DrvSelMd4Pn "BLN";
BA_ "PacketOrder" SG_ 2149924864 DSMSS_DrvSelMd4Pn 12;
BA_ "SignalLongName" SG_ 2149924864 DSMSS_DrvSelMd4Pn "Driver Selected Mode Selection Status : Driver Selected Mode 4 Pending";
BA_ "VNSigAllNodes" SG_ 2149924864 DSMSS_DrvSelMd4Pn 1;
BA_ "GenSigSendType" SG_ 2149924864 DSMSS_DrvSelMd3Pn 10;
BA_ "GenSigSendOnInit" SG_ 2149924864 DSMSS_DrvSelMd3Pn 1;
BA_ "SignalType" SG_ 2149924864 DSMSS_DrvSelMd3Pn "BLN";
BA_ "PacketOrder" SG_ 2149924864 DSMSS_DrvSelMd3Pn 11;
BA_ "SignalLongName" SG_ 2149924864 DSMSS_DrvSelMd3Pn "Driver Selected Mode Selection Status : Driver Selected Mode 3 Pending";
BA_ "VNSigAllNodes" SG_ 2149924864 DSMSS_DrvSelMd3Pn 1;
BA_ "GenSigSendType" SG_ 2149924864 DSMSS_DrvSelMd2Pn 10;
BA_ "GenSigSendOnInit" SG_ 2149924864 DSMSS_DrvSelMd2Pn 1;
BA_ "SignalType" SG_ 2149924864 DSMSS_DrvSelMd2Pn "BLN";
BA_ "PacketOrder" SG_ 2149924864 DSMSS_DrvSelMd2Pn 10;
BA_ "SignalLongName" SG_ 2149924864 DSMSS_DrvSelMd2Pn "Driver Selected Mode Selection Status : Driver Selected Mode 2 Pending";
BA_ "VNSigAllNodes" SG_ 2149924864 DSMSS_DrvSelMd2Pn 1;
BA_ "GenSigSendType" SG_ 2149924864 DSMSS_DrvSelMd1Pn 10;
BA_ "GenSigSendOnInit" SG_ 2149924864 DSMSS_DrvSelMd1Pn 1;
BA_ "SignalType" SG_ 2149924864 DSMSS_DrvSelMd1Pn "BLN";
BA_ "PacketOrder" SG_ 2149924864 DSMSS_DrvSelMd1Pn 9;
BA_ "SignalLongName" SG_ 2149924864 DSMSS_DrvSelMd1Pn "Driver Selected Mode Selection Status : Driver Selected Mode 1 Pending";
BA_ "VNSigAllNodes" SG_ 2149924864 DSMSS_DrvSelMd1Pn 1;
BA_ "GenSigSendType" SG_ 2149924864 DSMSS_DrvSelMd8Un 10;
BA_ "GenSigSendOnInit" SG_ 2149924864 DSMSS_DrvSelMd8Un 1;
BA_ "SignalType" SG_ 2149924864 DSMSS_DrvSelMd8Un "BLN";
BA_ "PacketOrder" SG_ 2149924864 DSMSS_DrvSelMd8Un 8;
BA_ "SignalLongName" SG_ 2149924864 DSMSS_DrvSelMd8Un "Driver Selected Mode Selection Status : Driver Selected Mode 8 Unavailable";
BA_ "VNSigAllNodes" SG_ 2149924864 DSMSS_DrvSelMd8Un 1;
BA_ "GenSigSendType" SG_ 2149924864 DSMSS_DrvSelMd7Un 10;
BA_ "GenSigSendOnInit" SG_ 2149924864 DSMSS_DrvSelMd7Un 1;
BA_ "SignalType" SG_ 2149924864 DSMSS_DrvSelMd7Un "BLN";
BA_ "PacketOrder" SG_ 2149924864 DSMSS_DrvSelMd7Un 7;
BA_ "SignalLongName" SG_ 2149924864 DSMSS_DrvSelMd7Un "Driver Selected Mode Selection Status : Driver Selected Mode 7 Unavailable";
BA_ "VNSigAllNodes" SG_ 2149924864 DSMSS_DrvSelMd7Un 1;
BA_ "GenSigSendType" SG_ 2149924864 DSMSS_DrvSelMd6Un 10;
BA_ "GenSigSendOnInit" SG_ 2149924864 DSMSS_DrvSelMd6Un 1;
BA_ "SignalType" SG_ 2149924864 DSMSS_DrvSelMd6Un "BLN";
BA_ "PacketOrder" SG_ 2149924864 DSMSS_DrvSelMd6Un 6;
BA_ "SignalLongName" SG_ 2149924864 DSMSS_DrvSelMd6Un "Driver Selected Mode Selection Status : Driver Selected Mode 6 Unavailable";
BA_ "VNSigAllNodes" SG_ 2149924864 DSMSS_DrvSelMd6Un 1;
BA_ "GenSigSendType" SG_ 2149924864 DSMSS_DrvSelMd5Un 10;
BA_ "GenSigSendOnInit" SG_ 2149924864 DSMSS_DrvSelMd5Un 1;
BA_ "SignalType" SG_ 2149924864 DSMSS_DrvSelMd5Un "BLN";
BA_ "PacketOrder" SG_ 2149924864 DSMSS_DrvSelMd5Un 5;
BA_ "SignalLongName" SG_ 2149924864 DSMSS_DrvSelMd5Un "Driver Selected Mode Selection Status : Driver Selected Mode 5 Unavailable";
BA_ "VNSigAllNodes" SG_ 2149924864 DSMSS_DrvSelMd5Un 1;
BA_ "GenSigSendType" SG_ 2149924864 DSMSS_DrvSelMd4Un 10;
BA_ "GenSigSendOnInit" SG_ 2149924864 DSMSS_DrvSelMd4Un 1;
BA_ "SignalType" SG_ 2149924864 DSMSS_DrvSelMd4Un "BLN";
BA_ "PacketOrder" SG_ 2149924864 DSMSS_DrvSelMd4Un 4;
BA_ "SignalLongName" SG_ 2149924864 DSMSS_DrvSelMd4Un "Driver Selected Mode Selection Status : Driver Selected Mode 4 Unavailable";
BA_ "VNSigAllNodes" SG_ 2149924864 DSMSS_DrvSelMd4Un 1;
BA_ "GenSigSendType" SG_ 2149924864 DSMSS_DrvSelMd3Un 10;
BA_ "GenSigSendOnInit" SG_ 2149924864 DSMSS_DrvSelMd3Un 1;
BA_ "SignalType" SG_ 2149924864 DSMSS_DrvSelMd3Un "BLN";
BA_ "PacketOrder" SG_ 2149924864 DSMSS_DrvSelMd3Un 3;
BA_ "SignalLongName" SG_ 2149924864 DSMSS_DrvSelMd3Un "Driver Selected Mode Selection Status : Driver Selected Mode 3 Unavailable";
BA_ "VNSigAllNodes" SG_ 2149924864 DSMSS_DrvSelMd3Un 1;
BA_ "GenSigSendType" SG_ 2149924864 DSMSS_DrvSelMd2Un 10;
BA_ "GenSigSendOnInit" SG_ 2149924864 DSMSS_DrvSelMd2Un 1;
BA_ "SignalType" SG_ 2149924864 DSMSS_DrvSelMd2Un "BLN";
BA_ "PacketOrder" SG_ 2149924864 DSMSS_DrvSelMd2Un 2;
BA_ "SignalLongName" SG_ 2149924864 DSMSS_DrvSelMd2Un "Driver Selected Mode Selection Status : Driver Selected Mode 2 Unavailable";
BA_ "VNSigAllNodes" SG_ 2149924864 DSMSS_DrvSelMd2Un 1;
BA_ "GenSigSendType" SG_ 2149924864 DSMSS_DrvSelMd1Un 10;
BA_ "GenSigSendOnInit" SG_ 2149924864 DSMSS_DrvSelMd1Un 1;
BA_ "SignalType" SG_ 2149924864 DSMSS_DrvSelMd1Un "BLN";
BA_ "PacketOrder" SG_ 2149924864 DSMSS_DrvSelMd1Un 1;
BA_ "SignalLongName" SG_ 2149924864 DSMSS_DrvSelMd1Un "Driver Selected Mode Selection Status : Driver Selected Mode 1 Unavailable";
BA_ "VNSigAllNodes" SG_ 2149924864 DSMSS_DrvSelMd1Un 1;
BA_ "GenSigSendType" SG_ 2149924864 DrvSelMd3Stat 10;
BA_ "GenSigSendOnInit" SG_ 2149924864 DrvSelMd3Stat 1;
BA_ "SignalType" SG_ 2149924864 DrvSelMd3Stat "ENM";
BA_ "SignalLongName" SG_ 2149924864 DrvSelMd3Stat "Driver Selected Mode 3 Status";
BA_ "VNSigAllNodes" SG_ 2149924864 DrvSelMd3Stat 1;
BA_ "GenSigSendType" SG_ 2149924864 DrvSelMd3ReqDnd 10;
BA_ "SignalType" SG_ 2149924864 DrvSelMd3ReqDnd "BLN";
BA_ "SignalLongName" SG_ 2149924864 DrvSelMd3ReqDnd "Driver Selected Mode 3 Request Denied";
BA_ "VNSigAllNodes" SG_ 2149924864 DrvSelMd3ReqDnd 1;
BA_ "GenSigSendType" SG_ 2149924864 DrvSelMd2Stat 10;
BA_ "GenSigSendOnInit" SG_ 2149924864 DrvSelMd2Stat 1;
BA_ "SignalType" SG_ 2149924864 DrvSelMd2Stat "ENM";
BA_ "SignalLongName" SG_ 2149924864 DrvSelMd2Stat "Driver Selected Mode 2 Status";
BA_ "VNSigAllNodes" SG_ 2149924864 DrvSelMd2Stat 1;
BA_ "GenSigSendType" SG_ 2149924864 DrvSelMd2ReqDnd 10;
BA_ "SignalType" SG_ 2149924864 DrvSelMd2ReqDnd "BLN";
BA_ "SignalLongName" SG_ 2149924864 DrvSelMd2ReqDnd "Driver Selected Mode 2 Request Denied";
BA_ "VNSigAllNodes" SG_ 2149924864 DrvSelMd2ReqDnd 1;
BA_ "GenSigSendType" SG_ 2149924864 DrvSelMd1Stat 10;
BA_ "GenSigSendOnInit" SG_ 2149924864 DrvSelMd1Stat 1;
BA_ "SignalType" SG_ 2149924864 DrvSelMd1Stat "ENM";
BA_ "SignalLongName" SG_ 2149924864 DrvSelMd1Stat "Driver Selected Mode 1 Status";
BA_ "VNSigAllNodes" SG_ 2149924864 DrvSelMd1Stat 1;
BA_ "GenSigSendType" SG_ 2149924864 DrvSelMd1ReqDnd 10;
BA_ "SignalType" SG_ 2149924864 DrvSelMd1ReqDnd "BLN";
BA_ "SignalLongName" SG_ 2149924864 DrvSelMd1ReqDnd "Driver Selected Mode 1 Request Denied";
BA_ "VNSigAllNodes" SG_ 2149924864 DrvSelMd1ReqDnd 1;
BA_ "GenSigSendType" SG_ 2149924864 CPSCA_Resrv3Avail 10;
BA_ "GenSigSendOnInit" SG_ 2149924864 CPSCA_Resrv3Avail 1;
BA_ "PacketOrder" SG_ 2149924864 CPSCA_Resrv3Avail 7;
BA_ "SignalType" SG_ 2149924864 CPSCA_Resrv3Avail "BLN";
BA_ "SignalLongName" SG_ 2149924864 CPSCA_Resrv3Avail "Collision Preparation System Customization Available : Reserved3 Available";
BA_ "VNSigAllNodes" SG_ 2149924864 CPSCA_Resrv3Avail 1;
BA_ "GenSigSendType" SG_ 2149924864 CPSCA_Resrv2Avail 10;
BA_ "GenSigSendOnInit" SG_ 2149924864 CPSCA_Resrv2Avail 1;
BA_ "PacketOrder" SG_ 2149924864 CPSCA_Resrv2Avail 6;
BA_ "SignalType" SG_ 2149924864 CPSCA_Resrv2Avail "BLN";
BA_ "SignalLongName" SG_ 2149924864 CPSCA_Resrv2Avail "Collision Preparation System Customization Available : Reserved2 Available";
BA_ "VNSigAllNodes" SG_ 2149924864 CPSCA_Resrv2Avail 1;
BA_ "GenSigSendType" SG_ 2149924864 CPSCA_Resrv1Avail 10;
BA_ "GenSigSendOnInit" SG_ 2149924864 CPSCA_Resrv1Avail 1;
BA_ "PacketOrder" SG_ 2149924864 CPSCA_Resrv1Avail 5;
BA_ "SignalType" SG_ 2149924864 CPSCA_Resrv1Avail "BLN";
BA_ "SignalLongName" SG_ 2149924864 CPSCA_Resrv1Avail "Collision Preparation System Customization Available : Reserved1 Available";
BA_ "VNSigAllNodes" SG_ 2149924864 CPSCA_Resrv1Avail 1;
BA_ "GenSigSendType" SG_ 2149924864 CPSCA_AlrtBrkStrAvail 10;
BA_ "GenSigSendOnInit" SG_ 2149924864 CPSCA_AlrtBrkStrAvail 1;
BA_ "PacketOrder" SG_ 2149924864 CPSCA_AlrtBrkStrAvail 4;
BA_ "SignalType" SG_ 2149924864 CPSCA_AlrtBrkStrAvail "BLN";
BA_ "SignalLongName" SG_ 2149924864 CPSCA_AlrtBrkStrAvail "Collision Preparation System Customization Available : Alert and Brake and Steer Available";
BA_ "VNSigAllNodes" SG_ 2149924864 CPSCA_AlrtBrkStrAvail 1;
BA_ "GenSigSendType" SG_ 2149924864 CPSCA_AlrtBrkAvail 10;
BA_ "GenSigSendOnInit" SG_ 2149924864 CPSCA_AlrtBrkAvail 1;
BA_ "PacketOrder" SG_ 2149924864 CPSCA_AlrtBrkAvail 3;
BA_ "GenSigStartValue" SG_ 2149924864 CPSCA_AlrtBrkAvail 1;
BA_ "SignalType" SG_ 2149924864 CPSCA_AlrtBrkAvail "BLN";
BA_ "SignalLongName" SG_ 2149924864 CPSCA_AlrtBrkAvail "Collision Preparation System Customization Available : Alert and Brake Available";
BA_ "VNSigAllNodes" SG_ 2149924864 CPSCA_AlrtBrkAvail 1;
BA_ "GenSigSendType" SG_ 2149924864 CPSCA_AlrtAvail 10;
BA_ "GenSigSendOnInit" SG_ 2149924864 CPSCA_AlrtAvail 1;
BA_ "PacketOrder" SG_ 2149924864 CPSCA_AlrtAvail 2;
BA_ "GenSigStartValue" SG_ 2149924864 CPSCA_AlrtAvail 1;
BA_ "SignalType" SG_ 2149924864 CPSCA_AlrtAvail "BLN";
BA_ "SignalLongName" SG_ 2149924864 CPSCA_AlrtAvail "Collision Preparation System Customization Available : Alert Available";
BA_ "VNSigAllNodes" SG_ 2149924864 CPSCA_AlrtAvail 1;
BA_ "GenSigSendType" SG_ 2149924864 CPSCA_OffAvail 10;
BA_ "GenSigSendOnInit" SG_ 2149924864 CPSCA_OffAvail 1;
BA_ "PacketOrder" SG_ 2149924864 CPSCA_OffAvail 1;
BA_ "GenSigStartValue" SG_ 2149924864 CPSCA_OffAvail 1;
BA_ "SignalType" SG_ 2149924864 CPSCA_OffAvail "BLN";
BA_ "SignalLongName" SG_ 2149924864 CPSCA_OffAvail "Collision Preparation System Customization Available : Off Available";
BA_ "VNSigAllNodes" SG_ 2149924864 CPSCA_OffAvail 1;
BA_ "GenSigSendType" SG_ 2152054784 FuelEconMetDispUnts 10;
BA_ "GenSigSendOnInit" SG_ 2152054784 FuelEconMetDispUnts 1;
BA_ "VNSigInfotainment" SG_ 2152054784 FuelEconMetDispUnts 1;
BA_ "SignalType" SG_ 2152054784 FuelEconMetDispUnts "ENM";
BA_ "SignalLongName" SG_ 2152054784 FuelEconMetDispUnts "Fuel Economy Metric Display Units";
BA_ "VNSigAllNodes" SG_ 2152054784 FuelEconMetDispUnts 1;
BA_ "GenSigSendType" SG_ 2152054784 IntPnlClstrAnmtStat 10;
BA_ "SignalType" SG_ 2152054784 IntPnlClstrAnmtStat "ENM";
BA_ "SignalLongName" SG_ 2152054784 IntPnlClstrAnmtStat "Instrument Panel Cluster Animation Status";
BA_ "VNSigAllNodes" SG_ 2152054784 IntPnlClstrAnmtStat 1;
BA_ "GenSigSendType" SG_ 2152054784 AnmStrtReq 10;
BA_ "SignalType" SG_ 2152054784 AnmStrtReq "ENM";
BA_ "SignalLongName" SG_ 2152054784 AnmStrtReq "Animation Start Request";
BA_ "VNSigAllNodes" SG_ 2152054784 AnmStrtReq 1;
BA_ "GenSigSendType" SG_ 2150301696 WlcAnmReq 10;
BA_ "SignalType" SG_ 2150301696 WlcAnmReq "BLN";
BA_ "SignalLongName" SG_ 2150301696 WlcAnmReq "Welcome Animation Request";
BA_ "VNSigAllNodes" SG_ 2150301696 WlcAnmReq 1;
BA_ "GenSigSendType" SG_ 2152857600 ACCGrnMdStat 10;
BA_ "SignalType" SG_ 2152857600 ACCGrnMdStat "ENM";
BA_ "SignalLongName" SG_ 2152857600 ACCGrnMdStat "Adaptive Cruise Control Green Mode Status";
BA_ "VNSigAllNodes" SG_ 2152857600 ACCGrnMdStat 1;
BA_ "GenSigSendType" SG_ 2152857600 ACCRteSpdAdaptStat 10;
BA_ "SignalType" SG_ 2152857600 ACCRteSpdAdaptStat "ENM";
BA_ "SignalLongName" SG_ 2152857600 ACCRteSpdAdaptStat "Adaptive Cruise Control Route Speed Adaption Status";
BA_ "VNSigAllNodes" SG_ 2152857600 ACCRteSpdAdaptStat 1;
BA_ "GenSigSendType" SG_ 2152857600 ACCRteSpdDrvIntvReq 10;
BA_ "SignalType" SG_ 2152857600 ACCRteSpdDrvIntvReq "ENM";
BA_ "SignalLongName" SG_ 2152857600 ACCRteSpdDrvIntvReq "Adaptive Cruise Control Route Speed Driver Intervention Request";
BA_ "VNSigAllNodes" SG_ 2152857600 ACCRteSpdDrvIntvReq 1;
BA_ "GenSigSendType" SG_ 2152857600 ACCTrfcJamAstActStat 10;
BA_ "SignalType" SG_ 2152857600 ACCTrfcJamAstActStat "ENM";
BA_ "SignalLongName" SG_ 2152857600 ACCTrfcJamAstActStat "Adaptive Cruise Control Traffic Jam Assist Activation Status";
BA_ "VNSigAllNodes" SG_ 2152857600 ACCTrfcJamAstActStat 1;
BA_ "GenSigDeltaValue" SG_ 2152857600 ACCTrfcJamAstRmnTm 1;
BA_ "GenSigSendType" SG_ 2152857600 ACCTrfcJamAstRmnTm 12;
BA_ "SignalType" SG_ 2152857600 ACCTrfcJamAstRmnTm "UNM";
BA_ "SignalLongName" SG_ 2152857600 ACCTrfcJamAstRmnTm "Adaptive Cruise Control Traffic Jam Assist Remaining Time";
BA_ "VNSigAllNodes" SG_ 2152857600 ACCTrfcJamAstRmnTm 1;
BA_ "GenSigSendType" SG_ 2158149632 ECHGCD_XAxTkMrkInterv 10;
BA_ "GenSigSendOnInit" SG_ 2158149632 ECHGCD_XAxTkMrkInterv 1;
BA_ "PacketOrder" SG_ 2158149632 ECHGCD_XAxTkMrkInterv 3;
BA_ "VNSigInfotainment" SG_ 2158149632 ECHGCD_XAxTkMrkInterv 1;
BA_ "SignalType" SG_ 2158149632 ECHGCD_XAxTkMrkInterv "ENM";
BA_ "SignalLongName" SG_ 2158149632 ECHGCD_XAxTkMrkInterv "Energy Consumption History Graph Configuration Data : X Axis Tick Mark Interval";
BA_ "VNSigAllNodes" SG_ 2158149632 ECHGCD_XAxTkMrkInterv 1;
BA_ "GenSigDeltaValue" SG_ 2158149632 ECHGCD_YAxMaxVal 1;
BA_ "GenSigSendType" SG_ 2158149632 ECHGCD_YAxMaxVal 12;
BA_ "GenSigSendOnInit" SG_ 2158149632 ECHGCD_YAxMaxVal 1;
BA_ "PacketOrder" SG_ 2158149632 ECHGCD_YAxMaxVal 2;
BA_ "VNSigInfotainment" SG_ 2158149632 ECHGCD_YAxMaxVal 1;
BA_ "SignalType" SG_ 2158149632 ECHGCD_YAxMaxVal "UNM";
BA_ "SignalLongName" SG_ 2158149632 ECHGCD_YAxMaxVal "Energy Consumption History Graph Configuration Data : Y Axis Maximum Value";
BA_ "VNSigAllNodes" SG_ 2158149632 ECHGCD_YAxMaxVal 1;
BA_ "GenSigSendType" SG_ 2158149632 ECHGCD_MeasUt 10;
BA_ "GenSigSendOnInit" SG_ 2158149632 ECHGCD_MeasUt 1;
BA_ "PacketOrder" SG_ 2158149632 ECHGCD_MeasUt 1;
BA_ "VNSigInfotainment" SG_ 2158149632 ECHGCD_MeasUt 1;
BA_ "SignalType" SG_ 2158149632 ECHGCD_MeasUt "ENM";
BA_ "SignalLongName" SG_ 2158149632 ECHGCD_MeasUt "Energy Consumption History Graph Configuration Data : Measurement Unit";
BA_ "VNSigAllNodes" SG_ 2158149632 ECHGCD_MeasUt 1;
BA_ "GenSigDeltaValue" SG_ 2158149632 EgyCnsHstGphInsEgyCns 1;
BA_ "GenSigSendType" SG_ 2158149632 EgyCnsHstGphInsEgyCns 12;
BA_ "GenSigSendOnInit" SG_ 2158149632 EgyCnsHstGphInsEgyCns 1;
BA_ "VNSigInfotainment" SG_ 2158149632 EgyCnsHstGphInsEgyCns 1;
BA_ "SignalType" SG_ 2158149632 EgyCnsHstGphInsEgyCns "UNM";
BA_ "SignalLongName" SG_ 2158149632 EgyCnsHstGphInsEgyCns "Energy Consumption History Graph Instantaneous Energy Consumption";
BA_ "VNSigAllNodes" SG_ 2158149632 EgyCnsHstGphInsEgyCns 1;
BA_ "GenSigDeltaValue" SG_ 2158149632 HVBTBSCR_SsnDyStat 1;
BA_ "GenSigSendType" SG_ 2158149632 HVBTBSCR_SsnDyStat 12;
BA_ "GenSigSendOnInit" SG_ 2158149632 HVBTBSCR_SsnDyStat 1;
BA_ "VNSigInfotainment" SG_ 2158149632 HVBTBSCR_SsnDyStat 1;
BA_ "SignalType" SG_ 2158149632 HVBTBSCR_SsnDyStat "UNM";
BA_ "PacketOrder" SG_ 2158149632 HVBTBSCR_SsnDyStat 4;
BA_ "SignalLongName" SG_ 2158149632 HVBTBSCR_SsnDyStat "High Voltage Battery Time Based Season Charging Response : Season Day Status";
BA_ "VNSigAllNodes" SG_ 2158149632 HVBTBSCR_SsnDyStat 1;
BA_ "GenSigSendType" SG_ 2158149632 HVBTBSCR_SsnStat 10;
BA_ "GenSigSendOnInit" SG_ 2158149632 HVBTBSCR_SsnStat 1;
BA_ "VNSigInfotainment" SG_ 2158149632 HVBTBSCR_SsnStat 1;
BA_ "SignalType" SG_ 2158149632 HVBTBSCR_SsnStat "ENM";
BA_ "PacketOrder" SG_ 2158149632 HVBTBSCR_SsnStat 1;
BA_ "SignalLongName" SG_ 2158149632 HVBTBSCR_SsnStat "High Voltage Battery Time Based Season Charging Response : Season Status";
BA_ "VNSigAllNodes" SG_ 2158149632 HVBTBSCR_SsnStat 1;
BA_ "GenSigSendType" SG_ 2158149632 HVBTBSCR_SsnSlctStat 10;
BA_ "GenSigSendOnInit" SG_ 2158149632 HVBTBSCR_SsnSlctStat 1;
BA_ "VNSigInfotainment" SG_ 2158149632 HVBTBSCR_SsnSlctStat 1;
BA_ "SignalType" SG_ 2158149632 HVBTBSCR_SsnSlctStat "ENM";
BA_ "PacketOrder" SG_ 2158149632 HVBTBSCR_SsnSlctStat 2;
BA_ "SignalLongName" SG_ 2158149632 HVBTBSCR_SsnSlctStat "High Voltage Battery Time Based Season Charging Response : Season Selected Status";
BA_ "VNSigAllNodes" SG_ 2158149632 HVBTBSCR_SsnSlctStat 1;
BA_ "GenSigSendType" SG_ 2158149632 HVBTBSCR_SsnMthStat 10;
BA_ "GenSigSendOnInit" SG_ 2158149632 HVBTBSCR_SsnMthStat 1;
BA_ "VNSigInfotainment" SG_ 2158149632 HVBTBSCR_SsnMthStat 1;
BA_ "SignalType" SG_ 2158149632 HVBTBSCR_SsnMthStat "ENM";
BA_ "PacketOrder" SG_ 2158149632 HVBTBSCR_SsnMthStat 3;
BA_ "SignalLongName" SG_ 2158149632 HVBTBSCR_SsnMthStat "High Voltage Battery Time Based Season Charging Response : Season Month Status";
BA_ "VNSigAllNodes" SG_ 2158149632 HVBTBSCR_SsnMthStat 1;
BA_ "GenSigSendType" SG_ 2158149632 HVBatTmBsChrgStRsp 10;
BA_ "GenSigSendOnInit" SG_ 2158149632 HVBatTmBsChrgStRsp 1;
BA_ "VNSigInfotainment" SG_ 2158149632 HVBatTmBsChrgStRsp 1;
BA_ "SignalType" SG_ 2158149632 HVBatTmBsChrgStRsp "ENM";
BA_ "SignalLongName" SG_ 2158149632 HVBatTmBsChrgStRsp "High Voltage Battery Time Based Charging Status Response";
BA_ "VNSigAllNodes" SG_ 2158149632 HVBatTmBsChrgStRsp 1;
BA_ "GenSigSendType" SG_ 2158149632 HVBTBCRS_ChRtDStat 10;
BA_ "GenSigSendOnInit" SG_ 2158149632 HVBTBCRS_ChRtDStat 1;
BA_ "VNSigInfotainment" SG_ 2158149632 HVBTBCRS_ChRtDStat 1;
BA_ "SignalType" SG_ 2158149632 HVBTBCRS_ChRtDStat "ENM";
BA_ "PacketOrder" SG_ 2158149632 HVBTBCRS_ChRtDStat 2;
BA_ "SignalLongName" SG_ 2158149632 HVBTBCRS_ChRtDStat "High Voltage Battery Time Based Charge Rate Response : Charge Rate Day Status";
BA_ "VNSigAllNodes" SG_ 2158149632 HVBTBCRS_ChRtDStat 1;
BA_ "GenSigSendType" SG_ 2158149632 HVBTBCRS_ChRtSlctStat 10;
BA_ "GenSigSendOnInit" SG_ 2158149632 HVBTBCRS_ChRtSlctStat 1;
BA_ "VNSigInfotainment" SG_ 2158149632 HVBTBCRS_ChRtSlctStat 1;
BA_ "SignalType" SG_ 2158149632 HVBTBCRS_ChRtSlctStat "ENM";
BA_ "PacketOrder" SG_ 2158149632 HVBTBCRS_ChRtSlctStat 3;
BA_ "SignalLongName" SG_ 2158149632 HVBTBCRS_ChRtSlctStat "High Voltage Battery Time Based Charge Rate Response : Charge Rate Selected Status";
BA_ "VNSigAllNodes" SG_ 2158149632 HVBTBCRS_ChRtSlctStat 1;
BA_ "GenSigSendType" SG_ 2158149632 HVBTBCRS_ChRtEnblStat 10;
BA_ "GenSigSendOnInit" SG_ 2158149632 HVBTBCRS_ChRtEnblStat 1;
BA_ "VNSigInfotainment" SG_ 2158149632 HVBTBCRS_ChRtEnblStat 1;
BA_ "SignalType" SG_ 2158149632 HVBTBCRS_ChRtEnblStat "ENM";
BA_ "PacketOrder" SG_ 2158149632 HVBTBCRS_ChRtEnblStat 1;
BA_ "SignalLongName" SG_ 2158149632 HVBTBCRS_ChRtEnblStat "High Voltage Battery Time Based Charge Rate Response : Charge Rate Enable Status";
BA_ "VNSigAllNodes" SG_ 2158149632 HVBTBCRS_ChRtEnblStat 1;
BA_ "GenSigSendType" SG_ 2158149632 HVBatCrgDspStat 10;
BA_ "VNSigInfotainment" SG_ 2158149632 HVBatCrgDspStat 1;
BA_ "SignalType" SG_ 2158149632 HVBatCrgDspStat "ENM";
BA_ "SignalLongName" SG_ 2158149632 HVBatCrgDspStat "High Voltage Battery Charge Display Status";
BA_ "VNSigAllNodes" SG_ 2158149632 HVBatCrgDspStat 1;
BA_ "GenSigDeltaValue" SG_ 2158116864 OBHVBCMinsRmng 1;
BA_ "GenSigSendType" SG_ 2158116864 OBHVBCMinsRmng 12;
BA_ "GenSigSendOnInit" SG_ 2158116864 OBHVBCMinsRmng 1;
BA_ "VNSigInfotainment" SG_ 2158116864 OBHVBCMinsRmng 1;
BA_ "SignalType" SG_ 2158116864 OBHVBCMinsRmng "UNM";
BA_ "SignalLongName" SG_ 2158116864 OBHVBCMinsRmng "Off Board High Voltage Bulk Charging Minutes Remaining";
BA_ "VNSigAllNodes" SG_ 2158116864 OBHVBCMinsRmng 1;
BA_ "GenSigSendType" SG_ 2158116864 OBHVBCCompTmDispFrmt 10;
BA_ "GenSigSendOnInit" SG_ 2158116864 OBHVBCCompTmDispFrmt 1;
BA_ "VNSigInfotainment" SG_ 2158116864 OBHVBCCompTmDispFrmt 1;
BA_ "SignalType" SG_ 2158116864 OBHVBCCompTmDispFrmt "ENM";
BA_ "SignalLongName" SG_ 2158116864 OBHVBCCompTmDispFrmt "Off Board High Voltage Bulk Charging Completion Time Display Format";
BA_ "VNSigAllNodes" SG_ 2158116864 OBHVBCCompTmDispFrmt 1;
BA_ "GenSigDeltaValue" SG_ 2158116864 HVBTBRCR_RtCHSlctTblRwStat 1;
BA_ "GenSigSendType" SG_ 2158116864 HVBTBRCR_RtCHSlctTblRwStat 12;
BA_ "GenSigSendOnInit" SG_ 2158116864 HVBTBRCR_RtCHSlctTblRwStat 1;
BA_ "VNSigInfotainment" SG_ 2158116864 HVBTBRCR_RtCHSlctTblRwStat 1;
BA_ "SignalType" SG_ 2158116864 HVBTBRCR_RtCHSlctTblRwStat "UNM";
BA_ "PacketOrder" SG_ 2158116864 HVBTBRCR_RtCHSlctTblRwStat 7;
BA_ "SignalLongName" SG_ 2158116864 HVBTBRCR_RtCHSlctTblRwStat "High Voltage Battery Time Based Rate Charging Response : Rate Charging Selected Table Row Status";
BA_ "VNSigAllNodes" SG_ 2158116864 HVBTBRCR_RtCHSlctTblRwStat 1;
BA_ "GenSigSendType" SG_ 2158116864 HVBTBRCR_RtChSlctStat 10;
BA_ "GenSigSendOnInit" SG_ 2158116864 HVBTBRCR_RtChSlctStat 1;
BA_ "VNSigInfotainment" SG_ 2158116864 HVBTBRCR_RtChSlctStat 1;
BA_ "SignalType" SG_ 2158116864 HVBTBRCR_RtChSlctStat "ENM";
BA_ "PacketOrder" SG_ 2158116864 HVBTBRCR_RtChSlctStat 3;
BA_ "SignalLongName" SG_ 2158116864 HVBTBRCR_RtChSlctStat "High Voltage Battery Time Based Rate Charging Response : Rate Charging Selected Status";
BA_ "VNSigAllNodes" SG_ 2158116864 HVBTBRCR_RtChSlctStat 1;
BA_ "GenSigSendType" SG_ 2158116864 HVBTBRCR_RtChSlRtStat 10;
BA_ "GenSigSendOnInit" SG_ 2158116864 HVBTBRCR_RtChSlRtStat 1;
BA_ "VNSigInfotainment" SG_ 2158116864 HVBTBRCR_RtChSlRtStat 1;
BA_ "SignalType" SG_ 2158116864 HVBTBRCR_RtChSlRtStat "ENM";
BA_ "PacketOrder" SG_ 2158116864 HVBTBRCR_RtChSlRtStat 6;
BA_ "SignalLongName" SG_ 2158116864 HVBTBRCR_RtChSlRtStat "High Voltage Battery Time Based Rate Charging Response : Rate Charging Selected Rate Status";
BA_ "VNSigAllNodes" SG_ 2158116864 HVBTBRCR_RtChSlRtStat 1;
BA_ "GenSigSendType" SG_ 2158116864 HVBTBRCR_RtChSsnStat 10;
BA_ "GenSigSendOnInit" SG_ 2158116864 HVBTBRCR_RtChSsnStat 1;
BA_ "VNSigInfotainment" SG_ 2158116864 HVBTBRCR_RtChSsnStat 1;
BA_ "SignalType" SG_ 2158116864 HVBTBRCR_RtChSsnStat "ENM";
BA_ "PacketOrder" SG_ 2158116864 HVBTBRCR_RtChSsnStat 1;
BA_ "SignalLongName" SG_ 2158116864 HVBTBRCR_RtChSsnStat "High Voltage Battery Time Based Rate Charging Response : Rate Charging Season Status";
BA_ "VNSigAllNodes" SG_ 2158116864 HVBTBRCR_RtChSsnStat 1;
BA_ "GenSigDeltaValue" SG_ 2158116864 HVBTBRCR_RtChMHRsp 1;
BA_ "GenSigSendType" SG_ 2158116864 HVBTBRCR_RtChMHRsp 12;
BA_ "GenSigSendOnInit" SG_ 2158116864 HVBTBRCR_RtChMHRsp 1;
BA_ "VNSigInfotainment" SG_ 2158116864 HVBTBRCR_RtChMHRsp 1;
BA_ "SignalType" SG_ 2158116864 HVBTBRCR_RtChMHRsp "UNM";
BA_ "PacketOrder" SG_ 2158116864 HVBTBRCR_RtChMHRsp 2;
BA_ "SignalLongName" SG_ 2158116864 HVBTBRCR_RtChMHRsp "High Voltage Battery Time Based Rate Charging Response : Rate Charging Minute of Hour Response";
BA_ "VNSigAllNodes" SG_ 2158116864 HVBTBRCR_RtChMHRsp 1;
BA_ "GenSigDeltaValue" SG_ 2158116864 HVBTBRCR_RtChHRsp 1;
BA_ "GenSigSendType" SG_ 2158116864 HVBTBRCR_RtChHRsp 12;
BA_ "GenSigSendOnInit" SG_ 2158116864 HVBTBRCR_RtChHRsp 1;
BA_ "VNSigInfotainment" SG_ 2158116864 HVBTBRCR_RtChHRsp 1;
BA_ "SignalType" SG_ 2158116864 HVBTBRCR_RtChHRsp "UNM";
BA_ "PacketOrder" SG_ 2158116864 HVBTBRCR_RtChHRsp 4;
BA_ "SignalLongName" SG_ 2158116864 HVBTBRCR_RtChHRsp "High Voltage Battery Time Based Rate Charging Response : Rate Charging Hour Response";
BA_ "VNSigAllNodes" SG_ 2158116864 HVBTBRCR_RtChHRsp 1;
BA_ "GenSigSendType" SG_ 2158116864 HVBTBRCR_RtChDStat 10;
BA_ "GenSigSendOnInit" SG_ 2158116864 HVBTBRCR_RtChDStat 1;
BA_ "VNSigInfotainment" SG_ 2158116864 HVBTBRCR_RtChDStat 1;
BA_ "SignalType" SG_ 2158116864 HVBTBRCR_RtChDStat "ENM";
BA_ "PacketOrder" SG_ 2158116864 HVBTBRCR_RtChDStat 5;
BA_ "SignalLongName" SG_ 2158116864 HVBTBRCR_RtChDStat "High Voltage Battery Time Based Rate Charging Response : Rate Charging Day Status";
BA_ "VNSigAllNodes" SG_ 2158116864 HVBTBRCR_RtChDStat 1;
BA_ "GenSigSendType" SG_ 2158116864 HVBTBDCRS_DlChSlctStat 10;
BA_ "GenSigSendOnInit" SG_ 2158116864 HVBTBDCRS_DlChSlctStat 1;
BA_ "VNSigInfotainment" SG_ 2158116864 HVBTBDCRS_DlChSlctStat 1;
BA_ "SignalType" SG_ 2158116864 HVBTBDCRS_DlChSlctStat "ENM";
BA_ "PacketOrder" SG_ 2158116864 HVBTBDCRS_DlChSlctStat 3;
BA_ "SignalLongName" SG_ 2158116864 HVBTBDCRS_DlChSlctStat "High Voltage Battery Time Based Delayed Charging Response : Delayed Charging Selected Status";
BA_ "VNSigAllNodes" SG_ 2158116864 HVBTBDCRS_DlChSlctStat 1;
BA_ "GenSigSendType" SG_ 2158116864 HVBTBDCRS_DlChSsnStat 10;
BA_ "GenSigSendOnInit" SG_ 2158116864 HVBTBDCRS_DlChSsnStat 1;
BA_ "VNSigInfotainment" SG_ 2158116864 HVBTBDCRS_DlChSsnStat 1;
BA_ "SignalType" SG_ 2158116864 HVBTBDCRS_DlChSsnStat "ENM";
BA_ "PacketOrder" SG_ 2158116864 HVBTBDCRS_DlChSsnStat 4;
BA_ "SignalLongName" SG_ 2158116864 HVBTBDCRS_DlChSsnStat "High Voltage Battery Time Based Delayed Charging Response : Delayed Charging Season Status";
BA_ "VNSigAllNodes" SG_ 2158116864 HVBTBDCRS_DlChSsnStat 1;
BA_ "GenSigDeltaValue" SG_ 2158116864 HVBTBDCRS_DlChMHRsp 1;
BA_ "GenSigSendType" SG_ 2158116864 HVBTBDCRS_DlChMHRsp 12;
BA_ "GenSigSendOnInit" SG_ 2158116864 HVBTBDCRS_DlChMHRsp 1;
BA_ "VNSigInfotainment" SG_ 2158116864 HVBTBDCRS_DlChMHRsp 1;
BA_ "SignalType" SG_ 2158116864 HVBTBDCRS_DlChMHRsp "UNM";
BA_ "PacketOrder" SG_ 2158116864 HVBTBDCRS_DlChMHRsp 5;
BA_ "SignalLongName" SG_ 2158116864 HVBTBDCRS_DlChMHRsp "High Voltage Battery Time Based Delayed Charging Response : Delayed Charging Minute of Hour Response";
BA_ "VNSigAllNodes" SG_ 2158116864 HVBTBDCRS_DlChMHRsp 1;
BA_ "GenSigDeltaValue" SG_ 2158116864 HVBTBDCRS_DlChHRsp 1;
BA_ "GenSigSendType" SG_ 2158116864 HVBTBDCRS_DlChHRsp 12;
BA_ "GenSigSendOnInit" SG_ 2158116864 HVBTBDCRS_DlChHRsp 1;
BA_ "VNSigInfotainment" SG_ 2158116864 HVBTBDCRS_DlChHRsp 1;
BA_ "SignalType" SG_ 2158116864 HVBTBDCRS_DlChHRsp "UNM";
BA_ "PacketOrder" SG_ 2158116864 HVBTBDCRS_DlChHRsp 1;
BA_ "SignalLongName" SG_ 2158116864 HVBTBDCRS_DlChHRsp "High Voltage Battery Time Based Delayed Charging Response : Delayed Charging Hour Response";
BA_ "VNSigAllNodes" SG_ 2158116864 HVBTBDCRS_DlChHRsp 1;
BA_ "GenSigSendType" SG_ 2158116864 HVBTBDCRS_DlChDStat 10;
BA_ "GenSigSendOnInit" SG_ 2158116864 HVBTBDCRS_DlChDStat 1;
BA_ "VNSigInfotainment" SG_ 2158116864 HVBTBDCRS_DlChDStat 1;
BA_ "SignalType" SG_ 2158116864 HVBTBDCRS_DlChDStat "ENM";
BA_ "PacketOrder" SG_ 2158116864 HVBTBDCRS_DlChDStat 2;
BA_ "SignalLongName" SG_ 2158116864 HVBTBDCRS_DlChDStat "High Voltage Battery Time Based Delayed Charging Response : Delayed Charging Day Status";
BA_ "VNSigAllNodes" SG_ 2158116864 HVBTBDCRS_DlChDStat 1;
BA_ "GenSigSendType" SG_ 2156281856 HTRCsStReq 10;
BA_ "VNSigInfotainment" SG_ 2156281856 HTRCsStReq 1;
BA_ "SignalType" SG_ 2156281856 HTRCsStReq "ENM";
BA_ "SignalLongName" SG_ 2156281856 HTRCsStReq "Hill Top Reserve Customization Setting Request";
BA_ "VNSigAllNodes" SG_ 2156281856 HTRCsStReq 1;
BA_ "GenSigSendType" SG_ 2156281856 RtBsChrgCmplnTmPrfReq 10;
BA_ "VNSigInfotainment" SG_ 2156281856 RtBsChrgCmplnTmPrfReq 1;
BA_ "SignalType" SG_ 2156281856 RtBsChrgCmplnTmPrfReq "ENM";
BA_ "SignalLongName" SG_ 2156281856 RtBsChrgCmplnTmPrfReq "Rate Based Charge Completion Time Preference Request";
BA_ "VNSigAllNodes" SG_ 2156281856 RtBsChrgCmplnTmPrfReq 1;
BA_ "GenSigSendType" SG_ 2156281856 TONPDTR_StTmpOvrAtv 10;
BA_ "VNSigInfotainment" SG_ 2156281856 TONPDTR_StTmpOvrAtv 1;
BA_ "SignalType" SG_ 2156281856 TONPDTR_StTmpOvrAtv "ENM";
BA_ "PacketOrder" SG_ 2156281856 TONPDTR_StTmpOvrAtv 1;
BA_ "SignalLongName" SG_ 2156281856 TONPDTR_StTmpOvrAtv "Temporary Override Next Planned Departure Time Requested : Set Temporary Override Next Planned Departure Time Active";
BA_ "VNSigAllNodes" SG_ 2156281856 TONPDTR_StTmpOvrAtv 1;
BA_ "GenSigDeltaValue" SG_ 2156281856 TONPDTR_MntOfHr 1;
BA_ "GenSigSendType" SG_ 2156281856 TONPDTR_MntOfHr 12;
BA_ "VNSigInfotainment" SG_ 2156281856 TONPDTR_MntOfHr 1;
BA_ "SignalType" SG_ 2156281856 TONPDTR_MntOfHr "UNM";
BA_ "PacketOrder" SG_ 2156281856 TONPDTR_MntOfHr 4;
BA_ "SignalLongName" SG_ 2156281856 TONPDTR_MntOfHr "Temporary Override Next Planned Departure Time Requested : Minute of Hour";
BA_ "VNSigAllNodes" SG_ 2156281856 TONPDTR_MntOfHr 1;
BA_ "GenSigDeltaValue" SG_ 2156281856 TONPDTR_HrOfDy 1;
BA_ "GenSigSendType" SG_ 2156281856 TONPDTR_HrOfDy 12;
BA_ "VNSigInfotainment" SG_ 2156281856 TONPDTR_HrOfDy 1;
BA_ "SignalType" SG_ 2156281856 TONPDTR_HrOfDy "UNM";
BA_ "PacketOrder" SG_ 2156281856 TONPDTR_HrOfDy 3;
BA_ "SignalLongName" SG_ 2156281856 TONPDTR_HrOfDy "Temporary Override Next Planned Departure Time Requested : Hour of Day";
BA_ "VNSigAllNodes" SG_ 2156281856 TONPDTR_HrOfDy 1;
BA_ "GenSigSendType" SG_ 2156281856 TONPDTR_DyOfWk 10;
BA_ "VNSigInfotainment" SG_ 2156281856 TONPDTR_DyOfWk 1;
BA_ "SignalType" SG_ 2156281856 TONPDTR_DyOfWk "ENM";
BA_ "PacketOrder" SG_ 2156281856 TONPDTR_DyOfWk 2;
BA_ "SignalLongName" SG_ 2156281856 TONPDTR_DyOfWk "Temporary Override Next Planned Departure Time Requested : Day of Week";
BA_ "VNSigAllNodes" SG_ 2156281856 TONPDTR_DyOfWk 1;
BA_ "GenSigSendType" SG_ 2156281856 StTODChrgTmpOvrd 10;
BA_ "VNSigInfotainment" SG_ 2156281856 StTODChrgTmpOvrd 1;
BA_ "SignalType" SG_ 2156281856 StTODChrgTmpOvrd "BLN";
BA_ "SignalLongName" SG_ 2156281856 StTODChrgTmpOvrd "Set Time of Day Charge Temporary Override";
BA_ "VNSigAllNodes" SG_ 2156281856 StTODChrgTmpOvrd 1;
BA_ "GenSigSendType" SG_ 2156281856 HVBTBSCSR_SsnStReq 10;
BA_ "VNSigInfotainment" SG_ 2156281856 HVBTBSCSR_SsnStReq 1;
BA_ "SignalType" SG_ 2156281856 HVBTBSCSR_SsnStReq "ENM";
BA_ "PacketOrder" SG_ 2156281856 HVBTBSCSR_SsnStReq 1;
BA_ "SignalLongName" SG_ 2156281856 HVBTBSCSR_SsnStReq "High Voltage Battery Time Based Season Charging Set Request : Season Set Request";
BA_ "VNSigAllNodes" SG_ 2156281856 HVBTBSCSR_SsnStReq 1;
BA_ "GenSigSendType" SG_ 2156281856 HVBTBSCSR_SsnSlStReq 10;
BA_ "VNSigInfotainment" SG_ 2156281856 HVBTBSCSR_SsnSlStReq 1;
BA_ "SignalType" SG_ 2156281856 HVBTBSCSR_SsnSlStReq "ENM";
BA_ "PacketOrder" SG_ 2156281856 HVBTBSCSR_SsnSlStReq 2;
BA_ "SignalLongName" SG_ 2156281856 HVBTBSCSR_SsnSlStReq "High Voltage Battery Time Based Season Charging Set Request : Season Selected Set Requset";
BA_ "VNSigAllNodes" SG_ 2156281856 HVBTBSCSR_SsnSlStReq 1;
BA_ "GenSigSendType" SG_ 2156281856 HVBTBSCSR_SsnMthStReq 10;
BA_ "VNSigInfotainment" SG_ 2156281856 HVBTBSCSR_SsnMthStReq 1;
BA_ "SignalType" SG_ 2156281856 HVBTBSCSR_SsnMthStReq "ENM";
BA_ "PacketOrder" SG_ 2156281856 HVBTBSCSR_SsnMthStReq 3;
BA_ "SignalLongName" SG_ 2156281856 HVBTBSCSR_SsnMthStReq "High Voltage Battery Time Based Season Charging Set Request : Season Month Set Request";
BA_ "VNSigAllNodes" SG_ 2156281856 HVBTBSCSR_SsnMthStReq 1;
BA_ "GenSigDeltaValue" SG_ 2156281856 HVBTBSCSR_SsnDayStReq 1;
BA_ "GenSigSendType" SG_ 2156281856 HVBTBSCSR_SsnDayStReq 12;
BA_ "VNSigInfotainment" SG_ 2156281856 HVBTBSCSR_SsnDayStReq 1;
BA_ "SignalType" SG_ 2156281856 HVBTBSCSR_SsnDayStReq "UNM";
BA_ "PacketOrder" SG_ 2156281856 HVBTBSCSR_SsnDayStReq 4;
BA_ "SignalLongName" SG_ 2156281856 HVBTBSCSR_SsnDayStReq "High Voltage Battery Time Based Season Charging Set Request : Season Day Set Request";
BA_ "VNSigAllNodes" SG_ 2156281856 HVBTBSCSR_SsnDayStReq 1;
BA_ "GenSigSendType" SG_ 2156281856 HVBTBCRSR_ChRtSlStReq 10;
BA_ "VNSigInfotainment" SG_ 2156281856 HVBTBCRSR_ChRtSlStReq 1;
BA_ "SignalType" SG_ 2156281856 HVBTBCRSR_ChRtSlStReq "ENM";
BA_ "PacketOrder" SG_ 2156281856 HVBTBCRSR_ChRtSlStReq 3;
BA_ "SignalLongName" SG_ 2156281856 HVBTBCRSR_ChRtSlStReq "High Voltage Battery Time Based Charge Rate Set Request : Charge Rate Selected Set Request";
BA_ "VNSigAllNodes" SG_ 2156281856 HVBTBCRSR_ChRtSlStReq 1;
BA_ "GenSigSendType" SG_ 2156281856 HVBTBCRSR_ChRtEnblStReq 10;
BA_ "VNSigInfotainment" SG_ 2156281856 HVBTBCRSR_ChRtEnblStReq 1;
BA_ "SignalType" SG_ 2156281856 HVBTBCRSR_ChRtEnblStReq "ENM";
BA_ "PacketOrder" SG_ 2156281856 HVBTBCRSR_ChRtEnblStReq 1;
BA_ "SignalLongName" SG_ 2156281856 HVBTBCRSR_ChRtEnblStReq "High Voltage Battery Time Based Charge Rate Set Request : Charge Rate Enable Set Request";
BA_ "VNSigAllNodes" SG_ 2156281856 HVBTBCRSR_ChRtEnblStReq 1;
BA_ "GenSigSendType" SG_ 2156281856 HVBTBCRSR_ChRtDStReq 10;
BA_ "VNSigInfotainment" SG_ 2156281856 HVBTBCRSR_ChRtDStReq 1;
BA_ "SignalType" SG_ 2156281856 HVBTBCRSR_ChRtDStReq "ENM";
BA_ "PacketOrder" SG_ 2156281856 HVBTBCRSR_ChRtDStReq 2;
BA_ "SignalLongName" SG_ 2156281856 HVBTBCRSR_ChRtDStReq "High Voltage Battery Time Based Charge Rate Set Request : Charge Rate Day Set Request";
BA_ "VNSigAllNodes" SG_ 2156281856 HVBTBCRSR_ChRtDStReq 1;
BA_ "GenSigSendType" SG_ 2156281856 HVBatTmBsChrgMdReq 10;
BA_ "VNSigInfotainment" SG_ 2156281856 HVBatTmBsChrgMdReq 1;
BA_ "SignalType" SG_ 2156281856 HVBatTmBsChrgMdReq "ENM";
BA_ "SignalLongName" SG_ 2156281856 HVBatTmBsChrgMdReq "High Voltage Battery Time Based Charging Mode Request";
BA_ "VNSigAllNodes" SG_ 2156281856 HVBatTmBsChrgMdReq 1;
BA_ "GenSigSendType" SG_ 2156281856 HVChgSyChgLvlPrfSt 10;
BA_ "VNSigInfotainment" SG_ 2156281856 HVChgSyChgLvlPrfSt 1;
BA_ "SignalType" SG_ 2156281856 HVChgSyChgLvlPrfSt "ENM";
BA_ "SignalLongName" SG_ 2156281856 HVChgSyChgLvlPrfSt "High Voltage Charging System Charge Level Preference Setting";
BA_ "VNSigAllNodes" SG_ 2156281856 HVChgSyChgLvlPrfSt 1;
BA_ "GenSigSendType" SG_ 2156265472 EngyUsgScrnMeasUtStat 10;
BA_ "GenSigSendOnInit" SG_ 2156265472 EngyUsgScrnMeasUtStat 1;
BA_ "VNSigInfotainment" SG_ 2156265472 EngyUsgScrnMeasUtStat 1;
BA_ "SignalType" SG_ 2156265472 EngyUsgScrnMeasUtStat "ENM";
BA_ "SignalLongName" SG_ 2156265472 EngyUsgScrnMeasUtStat "Energy Usage Screen Measurement Unit Status";
BA_ "VNSigAllNodes" SG_ 2156265472 EngyUsgScrnMeasUtStat 1;
BA_ "GenSigSendType" SG_ 2156265472 OffBrdHVCVehCsChRq 10;
BA_ "VNSigInfotainment" SG_ 2156265472 OffBrdHVCVehCsChRq 1;
BA_ "SignalType" SG_ 2156265472 OffBrdHVCVehCsChRq "BLN";
BA_ "SignalLongName" SG_ 2156265472 OffBrdHVCVehCsChRq "Off Board High Voltage Charging Vehicle Cease Charging Requested";
BA_ "VNSigAllNodes" SG_ 2156265472 OffBrdHVCVehCsChRq 1;
BA_ "GenSigSendType" SG_ 2156265472 PrtyChrgRq 10;
BA_ "VNSigInfotainment" SG_ 2156265472 PrtyChrgRq 1;
BA_ "SignalType" SG_ 2156265472 PrtyChrgRq "ENM";
BA_ "SignalLongName" SG_ 2156265472 PrtyChrgRq "Priority Charging Request";
BA_ "VNSigAllNodes" SG_ 2156265472 PrtyChrgRq 1;
BA_ "GenSigSendType" SG_ 2156265472 HVBTBRCSR_RtChSlStReq 10;
BA_ "VNSigInfotainment" SG_ 2156265472 HVBTBRCSR_RtChSlStReq 1;
BA_ "SignalType" SG_ 2156265472 HVBTBRCSR_RtChSlStReq "ENM";
BA_ "PacketOrder" SG_ 2156265472 HVBTBRCSR_RtChSlStReq 3;
BA_ "SignalLongName" SG_ 2156265472 HVBTBRCSR_RtChSlStReq "High Voltage Battery Time Based Rate Charging Set Request : Rate Charging Selected Set Request";
BA_ "VNSigAllNodes" SG_ 2156265472 HVBTBRCSR_RtChSlStReq 1;
BA_ "GenSigSendType" SG_ 2156265472 HVBTBRCSR_RtChSlRtStReq 10;
BA_ "VNSigInfotainment" SG_ 2156265472 HVBTBRCSR_RtChSlRtStReq 1;
BA_ "SignalType" SG_ 2156265472 HVBTBRCSR_RtChSlRtStReq "ENM";
BA_ "PacketOrder" SG_ 2156265472 HVBTBRCSR_RtChSlRtStReq 2;
BA_ "SignalLongName" SG_ 2156265472 HVBTBRCSR_RtChSlRtStReq "High Voltage Battery Time Based Rate Charging Set Request : Rate Charging Selected Rate Set Request";
BA_ "VNSigAllNodes" SG_ 2156265472 HVBTBRCSR_RtChSlRtStReq 1;
BA_ "GenSigSendType" SG_ 2156265472 HVBTBRCSR_RtChSsnStReq 10;
BA_ "VNSigInfotainment" SG_ 2156265472 HVBTBRCSR_RtChSsnStReq 1;
BA_ "SignalType" SG_ 2156265472 HVBTBRCSR_RtChSsnStReq "ENM";
BA_ "PacketOrder" SG_ 2156265472 HVBTBRCSR_RtChSsnStReq 5;
BA_ "SignalLongName" SG_ 2156265472 HVBTBRCSR_RtChSsnStReq "High Voltage Battery Time Based Rate Charging Set Request : Rate Charging Season Set Request";
BA_ "VNSigAllNodes" SG_ 2156265472 HVBTBRCSR_RtChSsnStReq 1;
BA_ "GenSigDeltaValue" SG_ 2156265472 HVBTBRCSR_RtChMHStReq 1;
BA_ "GenSigSendType" SG_ 2156265472 HVBTBRCSR_RtChMHStReq 12;
BA_ "VNSigInfotainment" SG_ 2156265472 HVBTBRCSR_RtChMHStReq 1;
BA_ "SignalType" SG_ 2156265472 HVBTBRCSR_RtChMHStReq "UNM";
BA_ "PacketOrder" SG_ 2156265472 HVBTBRCSR_RtChMHStReq 6;
BA_ "SignalLongName" SG_ 2156265472 HVBTBRCSR_RtChMHStReq "High Voltage Battery Time Based Rate Charging Set Request : Rate Charging Minute of Hour Set Request";
BA_ "VNSigAllNodes" SG_ 2156265472 HVBTBRCSR_RtChMHStReq 1;
BA_ "GenSigDeltaValue" SG_ 2156265472 HVBTBRCSR_RtChHStReq 1;
BA_ "GenSigSendType" SG_ 2156265472 HVBTBRCSR_RtChHStReq 12;
BA_ "VNSigInfotainment" SG_ 2156265472 HVBTBRCSR_RtChHStReq 1;
BA_ "SignalType" SG_ 2156265472 HVBTBRCSR_RtChHStReq "UNM";
BA_ "PacketOrder" SG_ 2156265472 HVBTBRCSR_RtChHStReq 4;
BA_ "SignalLongName" SG_ 2156265472 HVBTBRCSR_RtChHStReq "High Voltage Battery Time Based Rate Charging Set Request : Rate Charging Hour Set Request";
BA_ "VNSigAllNodes" SG_ 2156265472 HVBTBRCSR_RtChHStReq 1;
BA_ "GenSigSendType" SG_ 2156265472 HVBTBRCSR_RtChDStReq 10;
BA_ "VNSigInfotainment" SG_ 2156265472 HVBTBRCSR_RtChDStReq 1;
BA_ "SignalType" SG_ 2156265472 HVBTBRCSR_RtChDStReq "ENM";
BA_ "PacketOrder" SG_ 2156265472 HVBTBRCSR_RtChDStReq 1;
BA_ "SignalLongName" SG_ 2156265472 HVBTBRCSR_RtChDStReq "High Voltage Battery Time Based Rate Charging Set Request : Rate Charging Day Set Request";
BA_ "VNSigAllNodes" SG_ 2156265472 HVBTBRCSR_RtChDStReq 1;
BA_ "GenSigDeltaValue" SG_ 2156265472 HVBTBRCSR_RtChSlTbRwReq 1;
BA_ "GenSigSendType" SG_ 2156265472 HVBTBRCSR_RtChSlTbRwReq 12;
BA_ "VNSigInfotainment" SG_ 2156265472 HVBTBRCSR_RtChSlTbRwReq 1;
BA_ "SignalType" SG_ 2156265472 HVBTBRCSR_RtChSlTbRwReq "UNM";
BA_ "PacketOrder" SG_ 2156265472 HVBTBRCSR_RtChSlTbRwReq 7;
BA_ "SignalLongName" SG_ 2156265472 HVBTBRCSR_RtChSlTbRwReq "High Voltage Battery Time Based Rate Charging Set Request : Rate Charging Selected Table Row Set Request";
BA_ "VNSigAllNodes" SG_ 2156265472 HVBTBRCSR_RtChSlTbRwReq 1;
BA_ "GenSigSendType" SG_ 2156265472 HVBTBDCSRQ_DlChSlStReq 10;
BA_ "VNSigInfotainment" SG_ 2156265472 HVBTBDCSRQ_DlChSlStReq 1;
BA_ "SignalType" SG_ 2156265472 HVBTBDCSRQ_DlChSlStReq "ENM";
BA_ "PacketOrder" SG_ 2156265472 HVBTBDCSRQ_DlChSlStReq 3;
BA_ "SignalLongName" SG_ 2156265472 HVBTBDCSRQ_DlChSlStReq "High Voltage Battery Time Based Delayed Charging Set Request : Delayed Charging Selected Set Request";
BA_ "VNSigAllNodes" SG_ 2156265472 HVBTBDCSRQ_DlChSlStReq 1;
BA_ "GenSigSendType" SG_ 2156265472 HVBTBDCSRQ_DlChSsnStReq 10;
BA_ "VNSigInfotainment" SG_ 2156265472 HVBTBDCSRQ_DlChSsnStReq 1;
BA_ "SignalType" SG_ 2156265472 HVBTBDCSRQ_DlChSsnStReq "ENM";
BA_ "PacketOrder" SG_ 2156265472 HVBTBDCSRQ_DlChSsnStReq 4;
BA_ "SignalLongName" SG_ 2156265472 HVBTBDCSRQ_DlChSsnStReq "High Voltage Battery Time Based Delayed Charging Set Request : Delayed Charging Season Set Request";
BA_ "VNSigAllNodes" SG_ 2156265472 HVBTBDCSRQ_DlChSsnStReq 1;
BA_ "GenSigDeltaValue" SG_ 2156265472 HVBTBDCSRQ_DlChMHStReq 1;
BA_ "GenSigSendType" SG_ 2156265472 HVBTBDCSRQ_DlChMHStReq 12;
BA_ "VNSigInfotainment" SG_ 2156265472 HVBTBDCSRQ_DlChMHStReq 1;
BA_ "SignalType" SG_ 2156265472 HVBTBDCSRQ_DlChMHStReq "UNM";
BA_ "PacketOrder" SG_ 2156265472 HVBTBDCSRQ_DlChMHStReq 5;
BA_ "SignalLongName" SG_ 2156265472 HVBTBDCSRQ_DlChMHStReq "High Voltage Battery Time Based Delayed Charging Set Request : Delayed Charging Minute of Hour Set Request";
BA_ "VNSigAllNodes" SG_ 2156265472 HVBTBDCSRQ_DlChMHStReq 1;
BA_ "GenSigDeltaValue" SG_ 2156265472 HVBTBDCSRQ_DlChHStReq 1;
BA_ "GenSigSendType" SG_ 2156265472 HVBTBDCSRQ_DlChHStReq 12;
BA_ "VNSigInfotainment" SG_ 2156265472 HVBTBDCSRQ_DlChHStReq 1;
BA_ "SignalType" SG_ 2156265472 HVBTBDCSRQ_DlChHStReq "UNM";
BA_ "PacketOrder" SG_ 2156265472 HVBTBDCSRQ_DlChHStReq 1;
BA_ "SignalLongName" SG_ 2156265472 HVBTBDCSRQ_DlChHStReq "High Voltage Battery Time Based Delayed Charging Set Request : Delayed Charging Hour Set Request";
BA_ "VNSigAllNodes" SG_ 2156265472 HVBTBDCSRQ_DlChHStReq 1;
BA_ "GenSigSendType" SG_ 2156265472 HVBTBDCSRQ_DlChDStReq 10;
BA_ "VNSigInfotainment" SG_ 2156265472 HVBTBDCSRQ_DlChDStReq 1;
BA_ "SignalType" SG_ 2156265472 HVBTBDCSRQ_DlChDStReq "ENM";
BA_ "PacketOrder" SG_ 2156265472 HVBTBDCSRQ_DlChDStReq 2;
BA_ "SignalLongName" SG_ 2156265472 HVBTBDCSRQ_DlChDStReq "High Voltage Battery Time Based Delayed Charging Set Request : Delayed Charging Day Set Request";
BA_ "VNSigAllNodes" SG_ 2156265472 HVBTBDCSRQ_DlChDStReq 1;
BA_ "GenSigSendType" SG_ 2156265472 ChgPwLsAlCzStRq 10;
BA_ "VNSigInfotainment" SG_ 2156265472 ChgPwLsAlCzStRq 1;
BA_ "SignalType" SG_ 2156265472 ChgPwLsAlCzStRq "ENM";
BA_ "SignalLongName" SG_ 2156265472 ChgPwLsAlCzStRq "Charge Power Loss Alert Customization Setting Request";
BA_ "VNSigAllNodes" SG_ 2156265472 ChgPwLsAlCzStRq 1;
BA_ "GenSigSendType" SG_ 2156265472 ChgCdTfAlCzStRq 10;
BA_ "VNSigInfotainment" SG_ 2156265472 ChgCdTfAlCzStRq 1;
BA_ "SignalType" SG_ 2156265472 ChgCdTfAlCzStRq "ENM";
BA_ "SignalLongName" SG_ 2156265472 ChgCdTfAlCzStRq "Charge Cord Theft Alert Customization Setting Request";
BA_ "VNSigAllNodes" SG_ 2156265472 ChgCdTfAlCzStRq 1;
BA_ "GenSigSendType" SG_ 2156265472 ChgSysAudInCsStReq 10;
BA_ "VNSigInfotainment" SG_ 2156265472 ChgSysAudInCsStReq 1;
BA_ "SignalType" SG_ 2156265472 ChgSysAudInCsStReq "ENM";
BA_ "SignalLongName" SG_ 2156265472 ChgSysAudInCsStReq "Charger System Audible Indication Customization Setting Request";
BA_ "VNSigAllNodes" SG_ 2156265472 ChgSysAudInCsStReq 1;
BA_ "GenSigSendType" SG_ 2150113280 HVChrgInhbRsn 10;
BA_ "SignalType" SG_ 2150113280 HVChrgInhbRsn "ENM";
BA_ "SignalLongName" SG_ 2150113280 HVChrgInhbRsn "High Voltage Charging Inhibit Reason";
BA_ "VNSigAllNodes" SG_ 2150113280 HVChrgInhbRsn 1;
BA_ "GenSigDeltaValue" SG_ 2150113280 DrvCyclTrpDstTrvld 1;
BA_ "GenSigSendType" SG_ 2150113280 DrvCyclTrpDstTrvld 12;
BA_ "SignalType" SG_ 2150113280 DrvCyclTrpDstTrvld "UNM";
BA_ "SignalLongName" SG_ 2150113280 DrvCyclTrpDstTrvld "Drive Cycle Trip Distance Traveled";
BA_ "VNSigAllNodes" SG_ 2150113280 DrvCyclTrpDstTrvld 1;
BA_ "GenSigDeltaValue" SG_ 2150113280 DrvCyclElecEngyEcon 1;
BA_ "GenSigSendType" SG_ 2150113280 DrvCyclElecEngyEcon 12;
BA_ "SignalType" SG_ 2150113280 DrvCyclElecEngyEcon "UNM";
BA_ "SignalLongName" SG_ 2150113280 DrvCyclElecEngyEcon "Drive Cycle Electrical Energy Economy";
BA_ "VNSigAllNodes" SG_ 2150113280 DrvCyclElecEngyEcon 1;
BA_ "GenSigSendType" SG_ 2150113280 EngyStgSysActCoolEnb 10;
BA_ "GenSigSendOnInit" SG_ 2150113280 EngyStgSysActCoolEnb 1;
BA_ "VNSigInfotainment" SG_ 2150113280 EngyStgSysActCoolEnb 1;
BA_ "SignalType" SG_ 2150113280 EngyStgSysActCoolEnb "BLN";
BA_ "SignalLongName" SG_ 2150113280 EngyStgSysActCoolEnb "Energy Storage System Active Cooling Enabled";
BA_ "VNSigAllNodes" SG_ 2150113280 EngyStgSysActCoolEnb 1;
BA_ "GenSigDeltaValue" SG_ 2150113280 DrvCycElEnrgUsd 1;
BA_ "GenSigSendType" SG_ 2150113280 DrvCycElEnrgUsd 12;
BA_ "GenSigSendOnInit" SG_ 2150113280 DrvCycElEnrgUsd 1;
BA_ "VNSigInfotainment" SG_ 2150113280 DrvCycElEnrgUsd 1;
BA_ "SignalType" SG_ 2150113280 DrvCycElEnrgUsd "UNM";
BA_ "SignalLongName" SG_ 2150113280 DrvCycElEnrgUsd "Drive Cycle Electrical Energy Used";
BA_ "VNSigAllNodes" SG_ 2150113280 DrvCycElEnrgUsd 1;
BA_ "GenSigDeltaValue" SG_ 2150055936 ClmCntCmpPwrUsdClc 1;
BA_ "GenSigSendType" SG_ 2150055936 ClmCntCmpPwrUsdClc 12;
BA_ "SignalType" SG_ 2150055936 ClmCntCmpPwrUsdClc "UNM";
BA_ "SignalLongName" SG_ 2150055936 ClmCntCmpPwrUsdClc "Climate Control Compressor Power Used Calculated";
BA_ "VNSigAllNodes" SG_ 2150055936 ClmCntCmpPwrUsdClc 1;
BA_ "GenSigDeltaValue" SG_ 2150055936 ClimCtrlHVDvcShtdwnCmd 1;
BA_ "GenSigSendType" SG_ 2150055936 ClimCtrlHVDvcShtdwnCmd 10;
BA_ "GenSigSendOnInit" SG_ 2150055936 ClimCtrlHVDvcShtdwnCmd 1;
BA_ "SignalType" SG_ 2150055936 ClimCtrlHVDvcShtdwnCmd "BLN";
BA_ "SignalLongName" SG_ 2150055936 ClimCtrlHVDvcShtdwnCmd "Climate Control High Voltage Device Shutdown Commanded";
BA_ "VNSigAllNodes" SG_ 2150055936 ClimCtrlHVDvcShtdwnCmd 1;
BA_ "GenSigDeltaValue" SG_ 2150055936 ClmtCtrlLwrPwrLmt 1;
BA_ "GenSigSendType" SG_ 2150055936 ClmtCtrlLwrPwrLmt 12;
BA_ "GenSigSendOnInit" SG_ 2150055936 ClmtCtrlLwrPwrLmt 1;
BA_ "SignalType" SG_ 2150055936 ClmtCtrlLwrPwrLmt "UNM";
BA_ "SignalLongName" SG_ 2150055936 ClmtCtrlLwrPwrLmt "Climate Control Lower Power Limit";
BA_ "VNSigAllNodes" SG_ 2150055936 ClmtCtrlLwrPwrLmt 1;
BA_ "GenSigDeltaValue" SG_ 2150055936 ClmtCtrlUpprPwrLmt 1;
BA_ "GenSigSendType" SG_ 2150055936 ClmtCtrlUpprPwrLmt 12;
BA_ "GenSigSendOnInit" SG_ 2150055936 ClmtCtrlUpprPwrLmt 1;
BA_ "SignalType" SG_ 2150055936 ClmtCtrlUpprPwrLmt "UNM";
BA_ "SignalLongName" SG_ 2150055936 ClmtCtrlUpprPwrLmt "Climate Control Upper Power Limit";
BA_ "VNSigAllNodes" SG_ 2150055936 ClmtCtrlUpprPwrLmt 1;
BA_ "GenSigSendType" SG_ 2150039552 EvpCorOtltAirTmpCalcdV 10;
BA_ "SignalType" SG_ 2150039552 EvpCorOtltAirTmpCalcdV "ENM";
BA_ "SignalLongName" SG_ 2150039552 EvpCorOtltAirTmpCalcdV "Evaporator Core Outlet Air Temperature Calculated Validity";
BA_ "VNSigAllNodes" SG_ 2150039552 EvpCorOtltAirTmpCalcdV 1;
BA_ "GenSigSendType" SG_ 2150039552 ThrmlRefCompStat 10;
BA_ "GenSigSendOnInit" SG_ 2150039552 ThrmlRefCompStat 1;
BA_ "SignalType" SG_ 2150039552 ThrmlRefCompStat "ENM";
BA_ "SignalLongName" SG_ 2150039552 ThrmlRefCompStat "Thermal Refrigerant Compressor Status";
BA_ "VNSigAllNodes" SG_ 2150039552 ThrmlRefCompStat 1;
BA_ "GenSigSendType" SG_ 2150039552 ThrmlRefCompSpdV 10;
BA_ "GenSigSendOnInit" SG_ 2150039552 ThrmlRefCompSpdV 1;
BA_ "SignalType" SG_ 2150039552 ThrmlRefCompSpdV "ENM";
BA_ "SignalLongName" SG_ 2150039552 ThrmlRefCompSpdV "Thermal Refrigerant Compressor Speed Validity";
BA_ "VNSigAllNodes" SG_ 2150039552 ThrmlRefCompSpdV 1;
BA_ "GenSigDeltaValue" SG_ 2150039552 ThrmlRefCompSpd 1;
BA_ "GenSigSendType" SG_ 2150039552 ThrmlRefCompSpd 12;
BA_ "GenSigSendOnInit" SG_ 2150039552 ThrmlRefCompSpd 1;
BA_ "SignalType" SG_ 2150039552 ThrmlRefCompSpd "UNM";
BA_ "SignalLongName" SG_ 2150039552 ThrmlRefCompSpd "Thermal Refrigerant Compressor Speed";
BA_ "VNSigAllNodes" SG_ 2150039552 ThrmlRefCompSpd 1;
BA_ "GenSigSendType" SG_ 2150039552 ThrmlRfCmpOvTmpFltPr 10;
BA_ "GenSigSendOnInit" SG_ 2150039552 ThrmlRfCmpOvTmpFltPr 1;
BA_ "SignalType" SG_ 2150039552 ThrmlRfCmpOvTmpFltPr "BLN";
BA_ "SignalLongName" SG_ 2150039552 ThrmlRfCmpOvTmpFltPr "Thermal Refrigerant Compressor Over Temperature Fault Present";
BA_ "VNSigAllNodes" SG_ 2150039552 ThrmlRfCmpOvTmpFltPr 1;
BA_ "GenSigDeltaValue" SG_ 2150039552 EvpCorOtltAirTmpCalcd 1;
BA_ "GenSigSendType" SG_ 2150039552 EvpCorOtltAirTmpCalcd 12;
BA_ "SignalType" SG_ 2150039552 EvpCorOtltAirTmpCalcd "UNM";
BA_ "SignalLongName" SG_ 2150039552 EvpCorOtltAirTmpCalcd "Evaporator Core Outlet Air Temperature Calculated";
BA_ "VNSigAllNodes" SG_ 2150039552 EvpCorOtltAirTmpCalcd 1;
BA_ "GenSigDeltaValue" SG_ 2154856448 HmdtySnsrTemp 1;
BA_ "GenSigSendType" SG_ 2154856448 HmdtySnsrTemp 12;
BA_ "SignalType" SG_ 2154856448 HmdtySnsrTemp "UNM";
BA_ "SignalLongName" SG_ 2154856448 HmdtySnsrTemp "Humidity Sensor Temperature";
BA_ "VNSigAllNodes" SG_ 2154856448 HmdtySnsrTemp 1;
BA_ "GenSigDeltaValue" SG_ 2154856448 HmdtySnsrRltvHmdty 1;
BA_ "GenSigSendType" SG_ 2154856448 HmdtySnsrRltvHmdty 12;
BA_ "SignalType" SG_ 2154856448 HmdtySnsrRltvHmdty "UNM";
BA_ "SignalLongName" SG_ 2154856448 HmdtySnsrRltvHmdty "Humidity Sensor Relative Humidity";
BA_ "VNSigAllNodes" SG_ 2154856448 HmdtySnsrRltvHmdty 1;
BA_ "GenSigDeltaValue" SG_ 2154856448 HmdtySnsrGlssTemp 1;
BA_ "GenSigSendType" SG_ 2154856448 HmdtySnsrGlssTemp 12;
BA_ "SignalType" SG_ 2154856448 HmdtySnsrGlssTemp "UNM";
BA_ "SignalLongName" SG_ 2154856448 HmdtySnsrGlssTemp "Humidity Sensor Glass Temperature";
BA_ "VNSigAllNodes" SG_ 2154856448 HmdtySnsrGlssTemp 1;
BA_ "GenSigSendType" SG_ 2151489536 NVSysStat 10;
BA_ "SignalType" SG_ 2151489536 NVSysStat "ENM";
BA_ "SignalLongName" SG_ 2151489536 NVSysStat "Night Vision System Status";
BA_ "VNSigAllNodes" SG_ 2151489536 NVSysStat 1;
BA_ "GenSigSendType" SG_ 2151489536 RVBShtToPrkBfExtngVehIO 10;
BA_ "GenSigSendOnInit" SG_ 2151489536 RVBShtToPrkBfExtngVehIO 2;
BA_ "SignalType" SG_ 2151489536 RVBShtToPrkBfExtngVehIO "BLN";
BA_ "SignalLongName" SG_ 2151489536 RVBShtToPrkBfExtngVehIO "RVB Shift to Park Before Exiting Vehicle Indication On";
BA_ "VNSigAllNodes" SG_ 2151489536 RVBShtToPrkBfExtngVehIO 1;
BA_ "GenSigSendType" SG_ 2151489536 RVBAutoBrkRlsIO 10;
BA_ "SignalType" SG_ 2151489536 RVBAutoBrkRlsIO "BLN";
BA_ "SignalLongName" SG_ 2151489536 RVBAutoBrkRlsIO "RVB Autonomous Brake Release Indication On";
BA_ "VNSigAllNodes" SG_ 2151489536 RVBAutoBrkRlsIO 1;
BA_REL_ "GenSigSuprvResp" BU_SG_REL_ MCTM_LS SG_ 2150227968 PhnSpRcgnApSt 1;
BA_REL_ "GenSigRxStartValue" BU_SG_REL_ SCCM_1_LS SG_ 2152546304 BSCWA_ZnEnbd "0";
BA_REL_ "GenSigSuprvResp" BU_SG_REL_ SCCM_1_LS SG_ 2152546304 BSCWA_ZnEnbd 1;
BA_REL_ "GenSigRxStartValue" BU_SG_REL_ SCCM_1_LS SG_ 2152546304 BSCWA_Zn6 "0";
BA_REL_ "GenSigSuprvResp" BU_SG_REL_ SCCM_1_LS SG_ 2152546304 BSCWA_Zn6 1;
BA_REL_ "GenSigRxStartValue" BU_SG_REL_ SCCM_1_LS SG_ 2152546304 BSCWA_Zn5 "0";
BA_REL_ "GenSigSuprvResp" BU_SG_REL_ SCCM_1_LS SG_ 2152546304 BSCWA_Zn5 1;
BA_REL_ "GenSigRxStartValue" BU_SG_REL_ SCCM_1_LS SG_ 2152546304 BSCWA_Zn4 "0";
BA_REL_ "GenSigSuprvResp" BU_SG_REL_ SCCM_1_LS SG_ 2152546304 BSCWA_Zn4 1;
BA_REL_ "GenSigRxStartValue" BU_SG_REL_ SCCM_1_LS SG_ 2152546304 BSCWA_Zn1 "0";
BA_REL_ "GenSigSuprvResp" BU_SG_REL_ SCCM_1_LS SG_ 2152546304 BSCWA_Zn1 1;
BA_REL_ "GenSigRxStartValue" BU_SG_REL_ SCCM_1_LS SG_ 2152546304 BSCAA_ZnEnbd "0";
BA_REL_ "GenSigSuprvResp" BU_SG_REL_ SCCM_1_LS SG_ 2152546304 BSCAA_ZnEnbd 1;
BA_REL_ "GenSigRxStartValue" BU_SG_REL_ SCCM_1_LS SG_ 2152546304 BSCAA_Zn6 "0";
BA_REL_ "GenSigSuprvResp" BU_SG_REL_ SCCM_1_LS SG_ 2152546304 BSCAA_Zn6 1;
BA_REL_ "GenSigRxStartValue" BU_SG_REL_ SCCM_1_LS SG_ 2152546304 BSCAA_Zn5 "0";
BA_REL_ "GenSigSuprvResp" BU_SG_REL_ SCCM_1_LS SG_ 2152546304 BSCAA_Zn5 1;
BA_REL_ "GenSigRxStartValue" BU_SG_REL_ SCCM_1_LS SG_ 2152546304 BSCAA_Zn4 "0";
BA_REL_ "GenSigSuprvResp" BU_SG_REL_ SCCM_1_LS SG_ 2152546304 BSCAA_Zn4 1;
BA_REL_ "GenSigRxStartValue" BU_SG_REL_ SCCM_1_LS SG_ 2152546304 BSCAA_Zn1 "0";
BA_REL_ "GenSigSuprvResp" BU_SG_REL_ SCCM_1_LS SG_ 2152546304 BSCAA_Zn1 1;
BA_REL_ "GenSigSuprvResp" BU_SG_REL_ EOCM2cp_K2_LS SG_ 2149941248 PrkAstRrObjSnsngAct 1;
BA_REL_ "GenSigSuprvResp" BU_SG_REL_ EOCM2cp_K2_LS SG_ 2149941248 PrkAstRrSysStatUnfltd 1;
BA_REL_ "GenSigSuprvResp" BU_SG_REL_ EOCM2cp_K2_LS SG_ 2149941248 PrkAstRrExtdDstUnfltd 1;
BA_REL_ "GenSigSuprvResp" BU_SG_REL_ EOCM2cp_K2_LS SG_ 2149941248 PrkAstFntnSnsDstrbdIO 1;
BA_REL_ "GenSigSuprvResp" BU_SG_REL_ EOCM2cp_K2_LS SG_ 2149941248 PrkAstFntnSnrsBlkd 1;
BA_REL_ "GenSigSuprvResp" BU_SG_REL_ EOCM2cp_K2_LS SG_ 2149941248 PrkAstFntnFld 1;
BA_REL_ "GenSigSuprvResp" BU_SG_REL_ EOCM2cp_K2_LS SG_ 2149941248 PrkAstFntnDsbldIO 1;
BA_REL_ "GenSigSuprvResp" BU_SG_REL_ EOCM2cp_K2_LS SG_ 2149941248 PrkAstFntnClnPrkAstIO 1;
BA_REL_ "GenSigSuprvResp" BU_SG_REL_ EOCM2cp_K2_LS SG_ 2149941248 ClsnMtgtnInhbtReqtd 1;
BA_REL_ "GenSigSuprvResp" BU_SG_REL_ EOCM2cp_K2_LS SG_ 2149941248 PARrRgn4ObjStatUnfltd 1;
BA_REL_ "GenSigSuprvResp" BU_SG_REL_ EOCM2cp_K2_LS SG_ 2149941248 PARrRgn3ObjStatUnfltd 1;
BA_REL_ "GenSigSuprvResp" BU_SG_REL_ EOCM2cp_K2_LS SG_ 2149941248 PARrRgn2ObjStatUnfltd 1;
BA_REL_ "GenSigSuprvResp" BU_SG_REL_ EOCM2cp_K2_LS SG_ 2149941248 PARrRgn1ObjStatUnfltd 1;
BA_REL_ "GenSigSuprvResp" BU_SG_REL_ BCM_LS SG_ 2156314624 OBVhCsACChgRqBnVs 1;
BA_REL_ "GenSigSuprvResp" BU_SG_REL_ BCM_LS SG_ 2156314624 TODCNPDT_Min 1;
BA_REL_ "GenSigSuprvResp" BU_SG_REL_ BCM_LS SG_ 2156314624 TODCNPDT_Hr 1;
BA_REL_ "GenSigSuprvResp" BU_SG_REL_ BCM_LS SG_ 2156314624 TODCNPDT_DyOfWk 1;
BA_REL_ "GenSigSuprvResp" BU_SG_REL_ BCM_LS SG_ 2156314624 TODCDMPTO_TpOvR 1;
BA_REL_ "GenSigSuprvResp" BU_SG_REL_ BCM_LS SG_ 2156314624 TODCDMPTO_CmPgR 1;
BA_REL_ "GenSigSuprvResp" BU_SG_REL_ BCM_LS SG_ 2156314624 HVChrgSysStNot 1;
BA_REL_ "GenSigSuprvResp" BU_SG_REL_ BCM_LS SG_ 2156314624 HVCSCLPD_UsrIntTyp 1;
BA_REL_ "GenSigSuprvResp" BU_SG_REL_ BCM_LS SG_ 2156314624 HVCSCLPD_RdCrntLv3 1;
BA_REL_ "GenSigSuprvResp" BU_SG_REL_ BCM_LS SG_ 2156314624 HVCSCLPD_RdCrntLv2 1;
BA_REL_ "GenSigSuprvResp" BU_SG_REL_ BCM_LS SG_ 2156314624 HVCSCLPD_RdCrntLv1 1;
BA_REL_ "GenSigSuprvResp" BU_SG_REL_ BCM_LS SG_ 2156314624 HVCSCLPD_NrmChrgC 1;
BA_REL_ "GenSigSuprvResp" BU_SG_REL_ BCM_LS SG_ 2156314624 HVCSCLPD_ChgLvlPfS 1;
BA_REL_ "GenSigSuprvResp" BU_SG_REL_ ECC_LS SG_ 2150080512 EngAstHtDfrdHtMdAct 1;
BA_REL_ "GenSigSuprvResp" BU_SG_REL_ BCM_LS SG_ 2156331008 LwRngLVLdShdRq 1;
BA_REL_ "GenSigSuprvResp" BU_SG_REL_ BCM_LS SG_ 2150375424 USBProgInPrgrs 1;
BA_REL_ "GenSigSuprvResp" BU_SG_REL_ BCM_LS SG_ 2150375424 DsplTrnsShftLvrLckRqd 1;
BA_REL_ "GenSigSuprvResp" BU_SG_REL_ BCM_LS SG_ 2156298240 HVBSTLPC_MntOfHr 1;
BA_REL_ "GenSigSuprvResp" BU_SG_REL_ BCM_LS SG_ 2156298240 HVBSTLPC_HrOfDy 1;
BA_REL_ "GenSigSuprvResp" BU_SG_REL_ BCM_LS SG_ 2156298240 HVBSTLPC_DyOfWk 1;
BA_REL_ "GenSigSuprvResp" BU_SG_REL_ BCM_LS SG_ 2156298240 HVBSTHPC_MntOfHr 1;
BA_REL_ "GenSigSuprvResp" BU_SG_REL_ BCM_LS SG_ 2156298240 HVBSTHPC_HrOfDy 1;
BA_REL_ "GenSigSuprvResp" BU_SG_REL_ BCM_LS SG_ 2156298240 HVBSTHPC_DyOfWk 1;
BA_REL_ "GenSigSuprvResp" BU_SG_REL_ BCM_LS SG_ 2156298240 HVBCTLPC_MntOfHr 1;
BA_REL_ "GenSigSuprvResp" BU_SG_REL_ BCM_LS SG_ 2156298240 HVBCTLPC_HrOfDy 1;
BA_REL_ "GenSigSuprvResp" BU_SG_REL_ BCM_LS SG_ 2156298240 HVBCTLPC_DyOfWk 1;
BA_REL_ "GenSigSuprvResp" BU_SG_REL_ BCM_LS SG_ 2156298240 HVBCTHPC_MntOfHr 1;
BA_REL_ "GenSigSuprvResp" BU_SG_REL_ BCM_LS SG_ 2156298240 HVBCTHPC_HrOfDy 1;
BA_REL_ "GenSigSuprvResp" BU_SG_REL_ BCM_LS SG_ 2156298240 HVBCTHPC_DyOfWk 1;
BA_REL_ "GenSigSuprvResp" BU_SG_REL_ BCM_LS SG_ 2156298240 HVCSDTES_NPDTIO 1;
BA_REL_ "GenSigSuprvResp" BU_SG_REL_ BCM_LS SG_ 2156298240 HVCSDTES_LoPwrCIO 1;
BA_REL_ "GenSigSuprvResp" BU_SG_REL_ BCM_LS SG_ 2156298240 HVCSDTES_HiPwrCIO 1;
BA_REL_ "GenSigSuprvResp" BU_SG_REL_ ECC_LS SG_ 2149924864 DrvSelMd8Stat 1;
BA_REL_ "GenSigSuprvResp" BU_SG_REL_ ECC_LS SG_ 2149924864 DrvSelMd7Stat 1;
BA_REL_ "GenSigSuprvResp" BU_SG_REL_ ECC_LS SG_ 2149924864 DrvSelMd6Stat 1;
BA_REL_ "GenSigSuprvResp" BU_SG_REL_ ECC_LS SG_ 2149924864 DrvSelMd5Stat 1;
BA_REL_ "GenSigSuprvResp" BU_SG_REL_ ECC_LS SG_ 2149924864 DrvSelMd4Stat 1;
BA_REL_ "GenSigSuprvResp" BU_SG_REL_ ECC_LS SG_ 2149924864 DrvSelMd3Stat 1;
BA_REL_ "GenSigSuprvResp" BU_SG_REL_ ECC_LS SG_ 2149924864 DrvSelMd2Stat 1;
BA_REL_ "GenSigSuprvResp" BU_SG_REL_ ECC_LS SG_ 2149924864 DrvSelMd1Stat 1;
BA_REL_ "GenSigSuprvResp" BU_SG_REL_ VICM_LS SG_ 2152054784 FuelEconMetDispUnts 1;
BA_REL_ "GenSigSuprvResp" BU_SG_REL_ BCM_LS SG_ 2158149632 HVBatTmBsChrgStRsp 1;
BA_REL_ "GenSigSuprvResp" BU_SG_REL_ BCM_LS SG_ 2158116864 HVBTBDCRS_DlChSlctStat 1;
BA_REL_ "GenSigSuprvResp" BU_SG_REL_ BCM_LS SG_ 2158116864 HVBTBDCRS_DlChSsnStat 1;
BA_REL_ "GenSigSuprvResp" BU_SG_REL_ BCM_LS SG_ 2158116864 HVBTBDCRS_DlChMHRsp 1;
BA_REL_ "GenSigSuprvResp" BU_SG_REL_ BCM_LS SG_ 2158116864 HVBTBDCRS_DlChHRsp 1;
BA_REL_ "GenSigSuprvResp" BU_SG_REL_ BCM_LS SG_ 2158116864 HVBTBDCRS_DlChDStat 1;
BA_REL_ "GenSigSuprvResp" BU_SG_REL_ VICM_LS SG_ 2156281856 TONPDTR_StTmpOvrAtv 1;
BA_REL_ "GenSigSuprvResp" BU_SG_REL_ VICM_LS SG_ 2156281856 TONPDTR_MntOfHr 1;
BA_REL_ "GenSigSuprvResp" BU_SG_REL_ VICM_LS SG_ 2156281856 TONPDTR_HrOfDy 1;
BA_REL_ "GenSigSuprvResp" BU_SG_REL_ VICM_LS SG_ 2156281856 TONPDTR_DyOfWk 1;
BA_REL_ "GenSigSuprvResp" BU_SG_REL_ VICM_LS SG_ 2156265472 EngyUsgScrnMeasUtStat 1;
BA_REL_ "GenSigSuprvResp" BU_SG_REL_ VICM_LS SG_ 2156265472 ChgPwLsAlCzStRq 1;
BA_REL_ "GenSigSuprvResp" BU_SG_REL_ VICM_LS SG_ 2156265472 ChgCdTfAlCzStRq 1;
BA_REL_ "GenSigSuprvResp" BU_SG_REL_ ECC_LS SG_ 2150055936 ClmCntCmpPwrUsdClc 1;
BA_REL_ "GenSigSuprvResp" BU_SG_REL_ ECC_LS SG_ 2150039552 EvpCorOtltAirTmpCalcd 1;
BA_REL_ "GenSigSuprvResp" BU_SG_REL_ VICM_LS SG_ 2154856448 HmdtySnsrTemp 1;
BA_REL_ "GenSigSuprvResp" BU_SG_REL_ VICM_LS SG_ 2154856448 HmdtySnsrRltvHmdty 1;
VAL_ 2154790912 AutHgBmAsCsCrStVal 0 "No Value" 1 "Off" 2 "On" 3 "Reserved1" 4 "Reserved2" 5 "Reserved3" 6 "Reserved4" 7 "Reserved5" ;
VAL_ 2154790912 AutHgBmAsSnCsStAvl 1 "true" 0 "false" ;
VAL_ 2154790912 AutHgBmAsSnCsCrStVa 0 "No Value" 1 "Off" 2 "On Normal Sensitivity" 3 "On Reduced Sensitivity" 4 "Reserved1" 5 "Reserved2" 6 "Reserved3" 7 "Reserved4" ;
VAL_ 2154790912 AutHgBmAsCsStAvl 1 "true" 0 "false" ;
VAL_ 2154790912 AdpHgBmAsCsCrStVal 7 "Reserved5" 6 "Reserved4" 5 "Reserved3" 4 "Reserved2" 3 "Reserved1" 2 "On" 1 "Off" 0 "No Value" ;
VAL_ 2154790912 AdpHgBmAsCsStAvl 1 "true" 0 "false" ;
VAL_ 2154790912 AdpHgBmAsSnCsCrStVal 7 "Reserved4" 6 "Reserved3" 5 "Reserved2" 4 "Reserved1" 3 "On Reduced Sensitivity" 2 "On Normal Sensitivity" 1 "Off" 0 "No Value" ;
VAL_ 2154790912 AdpHgBmAsSnCsStAvl 1 "true" 0 "false" ;
VAL_ 2150227968 PhnSpRcgnApSt 3 "Unused" 2 "Audio Prompt Active" 1 "Speech Rec Active" 0 "Inactive" ;
VAL_ 2150580224 CstmrNonUsblSOCV 1 "Invalid" 0 "Valid" ;
VAL_ 2151735296 RtSdDetSysServDsbld 1 "true" 0 "false" ;
VAL_ 2151735296 RtSdDetSysTmpDsbld 1 "true" 0 "false" ;
VAL_ 2151735296 RtLnChgAlrtEnbld 1 "true" 0 "false" ;
VAL_ 2151735296 RtSBZAlrtEnbld 1 "true" 0 "false" ;
VAL_ 2151735296 RtRrCrsTrfcAlrtEnbld 1 "true" 0 "false" ;
VAL_ 2151735296 LnChgAlrtOffIndOn 1 "true" 0 "false" ;
VAL_ 2151735296 RrCrsTrfcAlrtOffIO 1 "true" 0 "false" ;
VAL_ 2151792640 RCTARIC_Indctr1Act 1 "true" 0 "false" ;
VAL_ 2151792640 RCTARIC_IndReq 0 "Off" 1 "Continuous Indication" 2 "Flashing Indication" ;
VAL_ 2152546304 BSCWA_ZnEnbd 1 "true" 0 "false" ;
VAL_ 2152546304 BSCAA_ZnEnbd 1 "true" 0 "false" ;
VAL_ 2149941248 PrkAstRrObjSnsngAct 1 "true" 0 "false" ;
VAL_ 2149941248 PrkAstRrSysStatUnfltd 0 "Disabled" 1 "Enabled" 2 "Inhibited" 3 "Failed" ;
VAL_ 2149941248 PrkAstFntnSnsDstrbdIO 1 "true" 0 "false" ;
VAL_ 2149941248 PrkAstFntnSnrsBlkd 1 "true" 0 "false" ;
VAL_ 2149941248 PrkAstFntnFld 1 "true" 0 "false" ;
VAL_ 2149941248 PrkAstFntnDsbldIO 1 "true" 0 "false" ;
VAL_ 2149941248 PrkAstFntnClnPrkAstIO 1 "true" 0 "false" ;
VAL_ 2149941248 ClsnMtgtnInhbtReqtd 1 "true" 0 "false" ;
VAL_ 2149941248 PARrRgn4ObjStatUnfltd 0 "No Object" 1 "Zone 1" 2 "Zone 2" 3 "Zone 3" 4 "Zone 4" 5 "Zone 5" 6 "Zone 6" 7 "Zone 7" 8 "Zone 8" 9 "Zone 9" 10 "Zone 10" 11 "Zone 11" 12 "Zone 12" 13 "Zone 13" 14 "Zone 14" 15 "Zone 15" ;
VAL_ 2149941248 PARrRgn3ObjStatUnfltd 0 "No Object" 1 "Zone 1" 2 "Zone 2" 3 "Zone 3" 4 "Zone 4" 5 "Zone 5" 6 "Zone 6" 7 "Zone 7" 8 "Zone 8" 9 "Zone 9" 10 "Zone 10" 11 "Zone 11" 12 "Zone 12" 13 "Zone 13" 14 "Zone 14" 15 "Zone 15" ;
VAL_ 2149941248 PARrRgn2ObjStatUnfltd 0 "No Object" 1 "Zone 1" 2 "Zone 2" 3 "Zone 3" 4 "Zone 4" 5 "Zone 5" 6 "Zone 6" 7 "Zone 7" 8 "Zone 8" 9 "Zone 9" 10 "Zone 10" 11 "Zone 11" 12 "Zone 12" 13 "Zone 13" 14 "Zone 14" 15 "Zone 15" ;
VAL_ 2149941248 PARrRgn1ObjStatUnfltd 0 "No Object" 1 "Zone 1" 2 "Zone 2" 3 "Zone 3" 4 "Zone 4" 5 "Zone 5" 6 "Zone 6" 7 "Zone 7" 8 "Zone 8" 9 "Zone 9" 10 "Zone 10" 11 "Zone 11" 12 "Zone 12" 13 "Zone 13" 14 "Zone 14" 15 "Zone 15" ;
VAL_ 2156314624 HVChrgSysSplyFltIO 1 "true" 0 "false" ;
VAL_ 2156314624 OffBrdCSFltDtctd 1 "true" 0 "false" ;
VAL_ 2156314624 OBVhCsACChgRqBnVs 1 "true" 0 "false" ;
VAL_ 2156314624 TODCNPDT_DyOfWk 0 "Unknown" 1 "Sunday" 2 "Monday" 3 "Tuesday" 4 "Wednesday" 5 "Thursday" 6 "Friday" 7 "Saturday" ;
VAL_ 2156314624 TODCOpMd 0 "Normal Operation" 1 "Departure Time Temporary Override" 2 "Charge Mode Temporary Override" 3 "Time of Day Faulted" ;
VAL_ 2156314624 TODCDMPTO_TpOvR 11 "Offboard Thermal Conditioning Only" 10 "Offboard Not Active Bulk Done" 9 "Offboard Active Bulk Done" 8 "Offboard Not Active" 7 "Offboard Active" 0 "None" 1 "Override Immediate" 2 "Override Next Plan Depart Time" 3 "Disabled" 4 "Onboard Fault" 5 "Offboard Fault Off Vehicle" 6 "Offboard Fault On Vehicle" ;
VAL_ 2156314624 TODCDMPTO_CmPgR 1 "true" 0 "false" ;
VAL_ 2156314624 HVChrgSysStNot 6 "Utility Override" 0 "Default" 1 "Idle" 2 "Initializing" 3 "Active" 4 "Complete" 5 "Aborted" ;
VAL_ 2156314624 HVChrgAbrtRsn 0 "No Action" 1 "Loss of AC" 2 "Unplug Charge" 3 "Unplug Delay" 4 "Charge Failure" 5 "Cordset Fault" 6 "Cordset Delay" ;
VAL_ 2156314624 HVCSCLPD_UsrIntTyp 0 "User Interface 1" 1 "User Interface 2" ;
VAL_ 2156314624 HVCSCLPD_ChgLvlPfS 0 "No Reduction" 1 "Reduced Current Level 1" 2 "Reduced Current Level 2" 3 "Reduced Current Level 3" ;
VAL_ 2150449152 ESPDrvrExtIO 1 "true" 0 "false" ;
VAL_ 2150449152 ESPDrvrDrStIndtrmntIO 1 "true" 0 "false" ;
VAL_ 2150449152 ESPAutoPrkIO 1 "true" 0 "false" ;
VAL_ 2150449152 ASIRI_Indication08 1 "true" 0 "false" ;
VAL_ 2150449152 ASIRI_Indication07 1 "true" 0 "false" ;
VAL_ 2150449152 ASIRI_Indication06 1 "true" 0 "false" ;
VAL_ 2150449152 ASIRI_Indication05 1 "true" 0 "false" ;
VAL_ 2150449152 ASIRI_Indication04 1 "true" 0 "false" ;
VAL_ 2150449152 ASIRI_Indication03 1 "true" 0 "false" ;
VAL_ 2150449152 ASIRI_Indication02 1 "true" 0 "false" ;
VAL_ 2150449152 ASIRI_Indication01 1 "true" 0 "false" ;
VAL_ 2150449152 SpdLmtrSttngTypAct 3 "Reserved" 2 "Auto" 1 "Manual" 0 "Off" ;
VAL_ 2150449152 EngInltSpcfcHmdtyV 1 "Invalid" 0 "Valid" ;
VAL_ 2150449152 EngInltSpcfcHmdtyM 1 "Use Data" 0 "Don't Use Data" ;
VAL_ 2149793792 FCACustStngAvlbl 1 "true" 0 "false" ;
VAL_ 2149793792 FwdClnAlrtCustCrntSetngVal 0 "No Action" 1 "Off" 2 "On" ;
VAL_ 2150080512 LBCVLS_VehGPSLctV 1 "Invalid" 0 "Valid" ;
VAL_ 2150080512 LBCVLS_VehGPSLct 4 "Vehicle Within Stored GPS Region 4" 3 "Vehicle Within Stored GPS Region 3" 2 "Vehicle Within Stored GPS Region 2" 1 "Vehicle Within Stored GPS Region 1" 0 "Vehicle Not Within Stored GPS Region" ;
VAL_ 2150080512 LBCPSS_PosUpdtStat 2 "Position Modification Failed " 1 "Position  Updated  " 0 "No Action" ;
VAL_ 2150080512 LBCPSS_PosUpdtLct 4 "Position 4" 3 "Position 3" 2 "Position 2" 1 "Position 1" 0 "No Action" ;
VAL_ 2150080512 LBCCsStAvl 1 "true" 0 "false" ;
VAL_ 2150080512 LBCCsCrStVal 2 "On" 1 "Off" 0 "No Action" ;
VAL_ 2150080512 LBCCF_Lct4PosStrdIO 1 "true" 0 "false" ;
VAL_ 2150080512 LBCCF_Lct3PosStrdIO 1 "true" 0 "false" ;
VAL_ 2150080512 LBCCF_Lct2PosStrdIO 1 "true" 0 "false" ;
VAL_ 2150080512 LBCCF_Lct1PosStrdIO 1 "true" 0 "false" ;
VAL_ 2150080512 LBCCDRR_PosNumbr 4 "Position Number 4 " 3 "Position Number 3" 2 "Position Number 2" 1 "Position Number 1" 0 "No Action" ;
VAL_ 2150080512 LBCCDRR_ClrStrdPosResp 2 "Clear Position Performed" 1 "Clear Position Request Acknowledged" 0 "No Action" ;
VAL_ 2150080512 LBCChrgLvlPrfExpIO 1 "true" 0 "false" ;
VAL_ 2150080512 EngAstHtDfrdHtMdAct 1 "true" 0 "false" ;
VAL_ 2150080512 AuxClntHtrVlvStat 7 "Unused and Reserved 2" 6 "De-Aeration Routine Active" 5 "Diagnostic Override" 4 "Re-Calibration" 3 "Fault Active" 2 "Engine Link" 1 "Transition" 0 "Engine Bypass" ;
VAL_ 2156331008 LwRngLVLdShdRq 0 "No Load Shedding" 1 "Load Shed Level1" 2 "Load Shed Level2" 3 "Load Shed Level3" ;
VAL_ 2151776256 RCTALIC_Indctr1Act 1 "true" 0 "false" ;
VAL_ 2151776256 RCTALIC_IndReq 0 "Off" 1 "Continuous Indication" 2 "Flashing Indication" ;
VAL_ 2150375424 LBCCsStReq 2 "On" 1 "Off" 0 "No Action" ;
VAL_ 2150375424 LBCPosMdfcReq 4 "Store Position 4" 3 "Store Position 3" 2 "Store Position 2" 1 "Store Position 1" 0 "No Action" ;
VAL_ 2150375424 LBCCDRR_ClrStrdPosReq 2 "Confirmation to Clear Position" 1 "Request to Clear Position" 0 "No Action" ;
VAL_ 2150375424 LBCCDRR_PosNum 4 "Position Number 4" 3 "Position Number 3" 2 "Position Number 2" 1 "Position Number 1" 0 "No Action" ;
VAL_ 2150375424 USBProgInPrgrs 1 "true" 0 "false" ;
VAL_ 2150375424 EngyCnsHistGrphRstRq 1 "true" 0 "false" ;
VAL_ 2150375424 DsplTrnsShftLvrLckRqd 1 "true" 0 "false" ;
VAL_ 2150375424 EngAstHtPlgInCstStRq 0 "No Action" 1 "Off" 2 "On" ;
VAL_ 2150375424 EngAstHtCstStRq 0 "No Action" 1 "On" 2 "Deferred" ;
VAL_ 2150375424 MntnceMdStEngRq 1 "true" 0 "false" ;
VAL_ 2150383616 EngMntnceMdAct 1 "true" 0 "false" ;
VAL_ 2150383616 MntnceMdDsplyRq 15 "Unused and Reserved" 14 "Continue FM" 13 "Force FM" 12 "FM 1 Day Warning" 11 "FM 2 Day Warning" 10 "FM 3 Day Warning" 9 "FM 4 Day Warning" 8 "FM 5 Day Warning" 7 "Continue EM" 6 "Force EM" 5 "EM 1 Day Warning" 4 "EM 2 Day Warning" 3 "EM 3 Day Warning" 2 "EM 4 Day Warning" 1 "EM 5 Day Warning" 0 "No Request" ;
VAL_ 2156298240 HTRActvIndOn 1 "true" 0 "false" ;
VAL_ 2156298240 HVBSTLPC_DyOfWk 0 "Unknown" 1 "Sunday" 2 "Monday" 3 "Tuesday" 4 "Wednesday" 5 "Thursday" 6 "Friday" 7 "Saturday" ;
VAL_ 2156298240 HVBSTHPC_DyOfWk 0 "Unknown" 1 "Sunday" 2 "Monday" 3 "Tuesday" 4 "Wednesday" 5 "Thursday" 6 "Friday" 7 "Saturday" ;
VAL_ 2156298240 HVBCTLPC_DyOfWk 0 "Unknown" 1 "Sunday" 2 "Monday" 3 "Tuesday" 4 "Wednesday" 5 "Thursday" 6 "Friday" 7 "Saturday" ;
VAL_ 2156298240 HVBCTHPC_DyOfWk 0 "Unknown" 1 "Sunday" 2 "Monday" 3 "Tuesday" 4 "Wednesday" 5 "Thursday" 6 "Friday" 7 "Saturday" ;
VAL_ 2156298240 InvldHMIEtrIO 1 "true" 0 "false" ;
VAL_ 2156298240 InsfcntTmTFlChrgIO 1 "true" 0 "false" ;
VAL_ 2156298240 HVBatChrgCrdAlrtReq 0 "None" 1 "Pedestrian" 2 "Theft" ;
VAL_ 2156298240 HVCSDTES_NPDTIO 1 "true" 0 "false" ;
VAL_ 2156298240 HVCSDTES_LoPwrCIO 1 "true" 0 "false" ;
VAL_ 2156298240 HVCSDTES_HiPwrCIO 1 "true" 0 "false" ;
VAL_ 2149924864 a_12VBatSysUnstab 1 "true" 0 "false" ;
VAL_ 2149924864 FwdClnMtgnBrkReqAct 1 "true" 0 "false" ;
VAL_ 2149924864 TireRRLowTracIO 1 "true" 0 "false" ;
VAL_ 2149924864 TireRFLowTracIO 1 "true" 0 "false" ;
VAL_ 2149924864 TireLRLowTracIO 1 "true" 0 "false" ;
VAL_ 2149924864 TireLFLowTracIO 1 "true" 0 "false" ;
VAL_ 2149924864 HilRlbkCtrlActIO 1 "true" 0 "false" ;
VAL_ 2149924864 FstIdlMdAct 1 "true" 0 "false" ;
VAL_ 2149924864 DrvSelMd8Stat 1 "Active" 0 "Inactive" ;
VAL_ 2149924864 DrvSelMd8ReqDnd 1 "true" 0 "false" ;
VAL_ 2149924864 DrvSelMd7Stat 1 "Active" 0 "Inactive" ;
VAL_ 2149924864 DrvSelMd7ReqDnd 1 "true" 0 "false" ;
VAL_ 2149924864 DrvSelMd6Stat 1 "Active" 0 "Inactive" ;
VAL_ 2149924864 DrvSelMd6ReqDnd 1 "true" 0 "false" ;
VAL_ 2149924864 DrvSelMd5Stat 1 "Active" 0 "Inactive" ;
VAL_ 2149924864 DrvSelMd5ReqDnd 1 "true" 0 "false" ;
VAL_ 2149924864 DrvSelMd4Stat 1 "Active" 0 "Inactive" ;
VAL_ 2149924864 DrvSelMd4ReqDnd 1 "true" 0 "false" ;
VAL_ 2149924864 DSMSS_DrvSelMd0Pn 1 "true" 0 "false" ;
VAL_ 2149924864 DSMSS_DrvSelMd8Pn 1 "true" 0 "false" ;
VAL_ 2149924864 DSMSS_DrvSelMd7Pn 1 "true" 0 "false" ;
VAL_ 2149924864 DSMSS_DrvSelMd6Pn 1 "true" 0 "false" ;
VAL_ 2149924864 DSMSS_DrvSelMd5Pn 1 "true" 0 "false" ;
VAL_ 2149924864 DSMSS_DrvSelMd4Pn 1 "true" 0 "false" ;
VAL_ 2149924864 DSMSS_DrvSelMd3Pn 1 "true" 0 "false" ;
VAL_ 2149924864 DSMSS_DrvSelMd2Pn 1 "true" 0 "false" ;
VAL_ 2149924864 DSMSS_DrvSelMd1Pn 1 "true" 0 "false" ;
VAL_ 2149924864 DSMSS_DrvSelMd8Un 1 "true" 0 "false" ;
VAL_ 2149924864 DSMSS_DrvSelMd7Un 1 "true" 0 "false" ;
VAL_ 2149924864 DSMSS_DrvSelMd6Un 1 "true" 0 "false" ;
VAL_ 2149924864 DSMSS_DrvSelMd5Un 1 "true" 0 "false" ;
VAL_ 2149924864 DSMSS_DrvSelMd4Un 1 "true" 0 "false" ;
VAL_ 2149924864 DSMSS_DrvSelMd3Un 1 "true" 0 "false" ;
VAL_ 2149924864 DSMSS_DrvSelMd2Un 1 "true" 0 "false" ;
VAL_ 2149924864 DSMSS_DrvSelMd1Un 1 "true" 0 "false" ;
VAL_ 2149924864 DrvSelMd3Stat 1 "Active" 0 "Inactive" ;
VAL_ 2149924864 DrvSelMd3ReqDnd 1 "true" 0 "false" ;
VAL_ 2149924864 DrvSelMd2Stat 1 "Active" 0 "Inactive" ;
VAL_ 2149924864 DrvSelMd2ReqDnd 1 "true" 0 "false" ;
VAL_ 2149924864 DrvSelMd1Stat 1 "Active" 0 "Inactive" ;
VAL_ 2149924864 DrvSelMd1ReqDnd 1 "true" 0 "false" ;
VAL_ 2149924864 CPSCA_Resrv3Avail 1 "true" 0 "false" ;
VAL_ 2149924864 CPSCA_Resrv2Avail 1 "true" 0 "false" ;
VAL_ 2149924864 CPSCA_Resrv1Avail 1 "true" 0 "false" ;
VAL_ 2149924864 CPSCA_AlrtBrkStrAvail 1 "true" 0 "false" ;
VAL_ 2149924864 CPSCA_AlrtBrkAvail 1 "true" 0 "false" ;
VAL_ 2149924864 CPSCA_AlrtAvail 1 "true" 0 "false" ;
VAL_ 2149924864 CPSCA_OffAvail 1 "true" 0 "false" ;
VAL_ 2152054784 FuelEconMetDispUnts 0 "Kilometers per liter" 1 "Liters per 100 km" ;
VAL_ 2152054784 IntPnlClstrAnmtStat 0 "Animation Not Available" 1 "Animation Available" 2 "Welcome Active" 3 "CRANK Active" 4 "RUN Active" 5 "Good Bye Active" ;
VAL_ 2152054784 AnmStrtReq 0 "No Action" 1 "Welcome" 2 "CRANK" 3 "RUN" 4 "Good Bye" ;
VAL_ 2150301696 WlcAnmReq 1 "true" 0 "false" ;
VAL_ 2152857600 ACCGrnMdStat 0 "Not Active" 1 "Ready to Assist" 2 "(Curve / Urban / Slope) Active" 3 "Temporarily not Available" ;
VAL_ 2152857600 ACCRteSpdAdaptStat 0 "Not Active" 1 "Ready to Assist" 2 "Active" 3 "Temporarily not Available" ;
VAL_ 2152857600 ACCRteSpdDrvIntvReq 0 "No Indication" 1 "Indication Level 1" 2 "Indication Level 2" 3 "Indication Level 3" ;
VAL_ 2152857600 ACCTrfcJamAstActStat 0 "Not Active" 1 "Timer Elapsed" 2 "Timer Active" 3 "Timer Retriggered" 4 "Timer Canceled" 5 "Temporarily Not Available" 6 "Traffic Jam Assist Failed" 7 "Vehicle Auto Go Notification" ;
VAL_ 2158149632 ECHGCD_XAxTkMrkInterv 7 "100" 6 "80" 5 "50" 4 "20" 3 "10" 2 "5" 1 "1" 0 "0.5" ;
VAL_ 2158149632 ECHGCD_MeasUt 15 "Unused and Reserved 7" 14 "Unused and Reserved 6" 13 "Unused and Reserved 5" 12 "Unused and Reserved 4" 11 "Unused and Reserved 3" 10 "Unused and Reserved 2" 9 "Unused and  Reserved 1" 8 "km per L e Combined" 7 "L per 100km e Combined" 6 "MPGe Combined" 5 "L per 100km" 4 "mi per gal" 3 "km per L" 2 "kWh per 100km" 1 "mi per kWh" 0 "km per kWh" ;
VAL_ 2158149632 HVBTBSCR_SsnStat 3 "Yearly" 0 "No Action" 1 "Summer" 2 "Winter" ;
VAL_ 2158149632 HVBTBSCR_SsnSlctStat 0 "No Action" 1 "Selected Season" 2 "Start Season" 3 "End Season" ;
VAL_ 2158149632 HVBTBSCR_SsnMthStat 0 "No Action" 1 "January" 2 "February" 3 "Mars" 4 "April" 5 "May" 6 "June" 7 "July" 8 "August" 9 "September" 10 "October" 11 "November" 12 "December" ;
VAL_ 2158149632 HVBatTmBsChrgStRsp 0 "No Action" 1 "Charge Now" 2 "Delayed Charge" 3 "Rate Based Charge" ;
VAL_ 2158149632 HVBTBCRS_ChRtDStat 0 "No Action" 1 "Sunday" 2 "Monday" 3 "Tuesday" 4 "Wednsday" 5 "Thursday" 6 "Friday" 7 "Saturday" 8 "All Days Same" 9 "Mon - Fri Same" 10 "Sat & Sun Same" ;
VAL_ 2158149632 HVBTBCRS_ChRtSlctStat 0 "No Action" 1 "Low Rate" 2 "Medium Rate" 3 "High Rate" ;
VAL_ 2158149632 HVBTBCRS_ChRtEnblStat 0 "No Action" 1 "Enabled" 2 "Disabled" ;
VAL_ 2158149632 HVBatCrgDspStat 0 "Inactive" 1 "Pending" 2 "Active Charging" 3 "Complete" 4 "Faulted" ;
VAL_ 2158116864 OBHVBCCompTmDispFrmt 2 "Display Remaining Minutes To Complete" 1 "Display Completion Time" 0 "No Action" ;
VAL_ 2158116864 HVBTBRCR_RtChSlctStat 0 "No Action" 1 "Charge Start" 2 "Charge End" 3 "Charge Start Invalid" 4 "Charge End Invalid" ;
VAL_ 2158116864 HVBTBRCR_RtChSlRtStat 0 "No Action" 1 "Low Rate" 2 "Medium Rate" 3 "High Rate" 4 "Reserved 1" 5 "Invalid Rate" ;
VAL_ 2158116864 HVBTBRCR_RtChSsnStat 3 "Yearly" 0 "No Action" 1 "Summer" 2 "Winter" ;
VAL_ 2158116864 HVBTBRCR_RtChDStat 0 "No Action" 1 "Sunday" 2 "Monday" 3 "Tuesday" 4 "Wednsday" 5 "Thursday" 6 "Friday" 7 "Saturday" 8 "All Days Same" 9 "Mon - Fri Same" 10 "Sat & Sun Same" ;
VAL_ 2158116864 HVBTBDCRS_DlChSlctStat 0 "No Action" 1 "Departure Time 1" 2 "Reserved" 3 "Departure Time 1 Invalid" 4 "Reserved" 5 "Departure Time 2" 6 "Reserved" 7 "Departure Time 2 Invalid" 8 "Reserved" ;
VAL_ 2158116864 HVBTBDCRS_DlChSsnStat 3 "Yearly" 0 "No Action" 1 "Summer" 2 "Winter" ;
VAL_ 2158116864 HVBTBDCRS_DlChDStat 0 "No Action" 1 "Sunday" 2 "Monday" 3 "Tuesday" 4 "Wednsday" 5 "Thursday" 6 "Friday" 7 "Saturday" 8 "All Days Same" 9 "Mon - Fri Same" 10 "Sat & Sun Same" ;
VAL_ 2156281856 HTRCsStReq 4 "On Away" 3 "On Home" 2 "On" 1 "Off" 0 "No Action" ;
VAL_ 2156281856 RtBsChrgCmplnTmPrfReq 2 "Latest Possible" 1 "Earliest Possible" 0 "No Action" ;
VAL_ 2156281856 TONPDTR_StTmpOvrAtv 0 "No Action" 1 "False (Inactive)" 2 "True (Active)" 3 "Unused and Reserved" ;
VAL_ 2156281856 TONPDTR_DyOfWk 0 "No Action" 1 "Unknown" 2 "Sunday" 3 "Monday" 4 "Tuesday" 5 "Wednesday" 6 "Thursday" 7 "Friday" 8 "Saturday" ;
VAL_ 2156281856 StTODChrgTmpOvrd 1 "true" 0 "false" ;
VAL_ 2156281856 HVBTBSCSR_SsnStReq 3 "Yearly" 0 "No Action" 1 "Summer" 2 "Winter" ;
VAL_ 2156281856 HVBTBSCSR_SsnSlStReq 0 "No Action" 1 "Selected Season" 2 "Start Season" 3 "End Season" ;
VAL_ 2156281856 HVBTBSCSR_SsnMthStReq 0 "No Action" 1 "January" 2 "February" 3 "Mars" 4 "April" 5 "May" 6 "June" 7 "July" 8 "August" 9 "September" 10 "October" 11 "November" 12 "December" ;
VAL_ 2156281856 HVBTBCRSR_ChRtSlStReq 0 "No Action" 1 "Low Rate" 2 "Medium Rate" 3 "High Rate" ;
VAL_ 2156281856 HVBTBCRSR_ChRtEnblStReq 0 "No Action" 1 "Enabled" 2 "Disabled" ;
VAL_ 2156281856 HVBTBCRSR_ChRtDStReq 0 "No Action" 1 "Sunday" 2 "Monday" 3 "Tuesday" 4 "Wednsday" 5 "Thursday" 6 "Friday" 7 "Saturday" 8 "All Days Same" 9 "Mon - Fri Same" 10 "Sat & Sun Same" ;
VAL_ 2156281856 HVBatTmBsChrgMdReq 0 "No Action" 1 "Charge Now" 2 "Delayed Charge" 3 "Rate Based Charge" ;
VAL_ 2156281856 HVChgSyChgLvlPrfSt 0 "No Action" 1 "No Reduction" 2 "Reduced Current Level 1" 3 "Reduced Current Level 2" 4 "Reduced Current Level 3" ;
VAL_ 2156265472 EngyUsgScrnMeasUtStat 15 "Unused and Reserved 9" 14 "Unused and Reserved 8" 13 "Unused and Reserved 7" 12 "Unused and Reserved 6" 11 "Unused and Reserved 5" 10 "Unused and Reserved 4" 9 "Unused and Reserved 3" 8 "Unused and Reserved 2" 7 "Unused and Reserved 1" 6 "km/L e Combined" 5 "km/L" 4 "L/100km e Combined" 3 "L/100km" 2 "MPGe Combined" 1 "MPG" 0 "No Action" ;
VAL_ 2156265472 OffBrdHVCVehCsChRq 1 "true" 0 "false" ;
VAL_ 2156265472 PrtyChrgRq 0 "No Action" 1 "False" 2 "True" ;
VAL_ 2156265472 HVBTBRCSR_RtChSlStReq 0 "No Action" 1 "Charge Start" 2 "Charge End" 3 "Charge Start Invalid" 4 "Charge End Invalid" ;
VAL_ 2156265472 HVBTBRCSR_RtChSlRtStReq 0 "No Action" 1 "Low Rate" 2 "Medium Rate" 3 "High Rate" 4 "Reserved 1" 5 "Invalid Rate" ;
VAL_ 2156265472 HVBTBRCSR_RtChSsnStReq 3 "Yearly" 0 "No Action" 1 "Summer" 2 "Winter" ;
VAL_ 2156265472 HVBTBRCSR_RtChDStReq 0 "No Action" 1 "Sunday" 2 "Monday" 3 "Tuesday" 4 "Wednsday" 5 "Thursday" 6 "Friday" 7 "Saturday" 8 "All Days Same" 9 "Mon - Fri Same" 10 "Sat & Sun Same" ;
VAL_ 2156265472 HVBTBDCSRQ_DlChSlStReq 8 "Reserved" 7 "Departure Time 2 Invalid" 6 "Reserved" 5 "Departure Time 2" 4 "Reserved" 3 "Departure Time 1 Invalid" 2 "Reserved" 1 "Departure Time 1" 0 "No Action" ;
VAL_ 2156265472 HVBTBDCSRQ_DlChSsnStReq 3 "Yearly" 0 "No Action" 1 "Summer" 2 "Winter" ;
VAL_ 2156265472 HVBTBDCSRQ_DlChDStReq 10 "Sat & Sun Same" 9 "Mon - Fri Same" 8 "All Days Same" 7 "Saturday" 6 "Friday" 5 "Thursday" 4 "Wednsday" 3 "Tuesday" 2 "Monday" 1 "Sunday" 0 "No Action" ;
VAL_ 2156265472 ChgPwLsAlCzStRq 0 "No Action" 1 "Off" 2 "On" 3 "Reserved 1" 4 "Reserved 2" 5 "Reserved 3" 6 "Reserved 4" 7 "Reserved 5" ;
VAL_ 2156265472 ChgCdTfAlCzStRq 0 "No Action" 1 "Off" 2 "On" 3 "Reserved 1" 4 "Reserved 2" 5 "Reserved 3" 6 "Reserved 4" 7 "Reserved 5" ;
VAL_ 2156265472 ChgSysAudInCsStReq 0 "No Action" 1 "Off" 2 "On" ;
VAL_ 2150113280 HVChrgInhbRsn 3 "See Charging Station" 2 "Charge Cord Lock Not Engaged" 1 "Charge Cord Not Fully Inserted" 0 "No Action" ;
VAL_ 2150113280 EngyStgSysActCoolEnb 1 "true" 0 "false" ;
VAL_ 2150055936 ClimCtrlHVDvcShtdwnCmd 1 "true" 0 "false" ;
VAL_ 2150039552 EvpCorOtltAirTmpCalcdV 1 "Invalid" 0 "Valid" ;
VAL_ 2150039552 ThrmlRefCompStat 0 "Normal Operation" 1 "Degraded Operation" 2 "Inoperative" 3 "Invalid" ;
VAL_ 2150039552 ThrmlRefCompSpdV 1 "Invalid" 0 "Valid" ;
VAL_ 2150039552 ThrmlRfCmpOvTmpFltPr 1 "true" 0 "false" ;
VAL_ 2151489536 NVSysStat 7 "Needs Headlights" 6 "Temporarily Unavailable" 5 "Not Dark" 4 "Needs Service" 3 "Active" 2 "Inactive" 1 "Initializing" 0 "Unknown" ;
VAL_ 2151489536 RVBShtToPrkBfExtngVehIO 1 "true" 0 "false" ;
VAL_ 2151489536 RVBAutoBrkRlsIO 1 "true" 0 "false" ;
SIG_GROUP_ 2153914368 EngyUsgScrScal 1 : EUSS_TrEgUgScrMxScVal EUSS_TrEgUgScrMnScVal EUSS_TcEgUgScrMxScVal EUSS_TcEgUgScrMnScVal EUSS_ITEgUgScrMxScVal EUSS_ITEgUgScrMnScVal EUSS_OTEgUgScrMxScVal EUSS_OTEgUgScrMnScVal;
SIG_GROUP_ 2151792640 RrCrsTrfAltRgtIndCtrl 1 : RCTARIC_Indctr1Act RCTARIC_IndReq;
SIG_GROUP_ 2152546304 BckupSnsrClngWshA 1 : BSCWA_ZnEnbd BSCWA_Zn6 BSCWA_Zn5 BSCWA_Zn4 BSCWA_Zn1;
SIG_GROUP_ 2152546304 BckupSnsrClngAirA 1 : BSCAA_ZnEnbd BSCAA_Zn6 BSCAA_Zn5 BSCAA_Zn4 BSCAA_Zn1;
SIG_GROUP_ 2156314624 TODCNxtPlnndDprtrTm 1 : TODCNPDT_Min TODCNPDT_Hr TODCNPDT_DyOfWk;
SIG_GROUP_ 2156314624 TODCDspMnPgTmpOr 1 : TODCDMPTO_TpOvR TODCDMPTO_CmPgR;
SIG_GROUP_ 2156314624 HVChgSyChgLvlPrfDt 1 : HVCSCLPD_UsrIntTyp HVCSCLPD_RdCrntLv3 HVCSCLPD_RdCrntLv2 HVCSCLPD_RdCrntLv1 HVCSCLPD_NrmChrgC HVCSCLPD_ChgLvlPfS;
SIG_GROUP_ 2150449152 AutoStpInhbtRsnInd 1 : ASIRI_Indication08 ASIRI_Indication07 ASIRI_Indication06 ASIRI_Indication05 ASIRI_Indication04 ASIRI_Indication03 ASIRI_Indication02 ASIRI_Indication01;
SIG_GROUP_ 2150080512 LBCVehLctStat 1 : LBCVLS_VehGPSLctV LBCVLS_VehGPSLct;
SIG_GROUP_ 2150080512 LBCPosStgStat 1 : LBCPSS_PosUpdtStat LBCPSS_PosUpdtLct;
SIG_GROUP_ 2150080512 LBCCstmrFdbk 1 : LBCCF_Lct4PosStrdIO LBCCF_Lct3PosStrdIO LBCCF_Lct2PosStrdIO LBCCF_Lct1PosStrdIO;
SIG_GROUP_ 2150080512 LBCCstmrDaRstResp 1 : LBCCDRR_PosNumbr LBCCDRR_ClrStrdPosResp;
SIG_GROUP_ 2151776256 RrCrsTrfAltLftIndCtrl 1 : RCTALIC_Indctr1Act RCTALIC_IndReq;
SIG_GROUP_ 2150375424 LBCCstmrDaRstReq 1 : LBCCDRR_ClrStrdPosReq LBCCDRR_PosNum;
SIG_GROUP_ 2151981056 DstTrvldDt 1 : DTD_FuelPrpDstTrvld DTD_DrvCyclDstTrvld DTD_BattPrpDstTrvld;
SIG_GROUP_ 2156298240 HVBatStrTmLwPwrChrg 1 : HVBSTLPC_MntOfHr HVBSTLPC_HrOfDy HVBSTLPC_DyOfWk;
SIG_GROUP_ 2156298240 HVBatStrTmHghPwrChrg 1 : HVBSTHPC_MntOfHr HVBSTHPC_HrOfDy HVBSTHPC_DyOfWk;
SIG_GROUP_ 2156298240 HVBatCmpltTmLwPwrChrg 1 : HVBCTLPC_MntOfHr HVBCTLPC_HrOfDy HVBCTLPC_DyOfWk;
SIG_GROUP_ 2156298240 HVBatCmpltTmHghPwrChrg 1 : HVBCTHPC_MntOfHr HVBCTHPC_HrOfDy HVBCTHPC_DyOfWk;
SIG_GROUP_ 2156298240 HVChrgSysDpTmExdSt 1 : HVCSDTES_NPDTIO HVCSDTES_LoPwrCIO HVCSDTES_HiPwrCIO;
SIG_GROUP_ 2149924864 DrvSelMdSelnStat 1 : DSMSS_DrvSelMd0Pn DSMSS_DrvSelMd8Pn DSMSS_DrvSelMd7Pn DSMSS_DrvSelMd6Pn DSMSS_DrvSelMd5Pn DSMSS_DrvSelMd4Pn DSMSS_DrvSelMd3Pn DSMSS_DrvSelMd2Pn DSMSS_DrvSelMd1Pn DSMSS_DrvSelMd8Un DSMSS_DrvSelMd7Un DSMSS_DrvSelMd6Un DSMSS_DrvSelMd5Un DSMSS_DrvSelMd4Un DSMSS_DrvSelMd3Un DSMSS_DrvSelMd2Un DSMSS_DrvSelMd1Un;
SIG_GROUP_ 2149924864 ColPrepSysCustAvail 1 : CPSCA_Resrv3Avail CPSCA_Resrv2Avail CPSCA_Resrv1Avail CPSCA_AlrtBrkStrAvail CPSCA_AlrtBrkAvail CPSCA_AlrtAvail CPSCA_OffAvail;
SIG_GROUP_ 2158149632 EngyCnsHsGrphCnfgDt 1 : ECHGCD_XAxTkMrkInterv ECHGCD_YAxMaxVal ECHGCD_MeasUt;
SIG_GROUP_ 2158149632 HVBatTmBsSsnChRsp 1 : HVBTBSCR_SsnDyStat HVBTBSCR_SsnStat HVBTBSCR_SsnSlctStat HVBTBSCR_SsnMthStat;
SIG_GROUP_ 2158149632 HVBatTmBsChrgRtRsp 1 : HVBTBCRS_ChRtDStat HVBTBCRS_ChRtSlctStat HVBTBCRS_ChRtEnblStat;
SIG_GROUP_ 2158116864 HVBatTmBsRtChrgRsp 1 : HVBTBRCR_RtCHSlctTblRwStat HVBTBRCR_RtChSlctStat HVBTBRCR_RtChSlRtStat HVBTBRCR_RtChSsnStat HVBTBRCR_RtChMHRsp HVBTBRCR_RtChHRsp HVBTBRCR_RtChDStat;
SIG_GROUP_ 2158116864 HVBatTmBsDelChrgRsp 1 : HVBTBDCRS_DlChSlctStat HVBTBDCRS_DlChSsnStat HVBTBDCRS_DlChMHRsp HVBTBDCRS_DlChHRsp HVBTBDCRS_DlChDStat;
SIG_GROUP_ 2156281856 TmpOvdNxtPlnDptTmRq 1 : TONPDTR_StTmpOvrAtv TONPDTR_MntOfHr TONPDTR_HrOfDy TONPDTR_DyOfWk;
SIG_GROUP_ 2156281856 HVBatTmBsSsnChStReq 1 : HVBTBSCSR_SsnStReq HVBTBSCSR_SsnSlStReq HVBTBSCSR_SsnMthStReq HVBTBSCSR_SsnDayStReq;
SIG_GROUP_ 2156281856 HVBatTmBsChrgRtStReq 1 : HVBTBCRSR_ChRtSlStReq HVBTBCRSR_ChRtEnblStReq HVBTBCRSR_ChRtDStReq;
SIG_GROUP_ 2156265472 HVBatTmBsRtChrgStReq 1 : HVBTBRCSR_RtChSlStReq HVBTBRCSR_RtChSlRtStReq HVBTBRCSR_RtChSsnStReq HVBTBRCSR_RtChMHStReq HVBTBRCSR_RtChHStReq HVBTBRCSR_RtChDStReq HVBTBRCSR_RtChSlTbRwReq;
SIG_GROUP_ 2156265472 HVBatTmBsDlChStReq 1 : HVBTBDCSRQ_DlChSlStReq HVBTBDCSRQ_DlChSsnStReq HVBTBDCSRQ_DlChMHStReq HVBTBDCSRQ_DlChHStReq HVBTBDCSRQ_DlChDStReq;
